VERSION "created by canmatrix"

NS_ :

BS_:

BU_: IPD

BO_ 712 IPD_BKPCANFD_100ms_FrP124: 16 IPD
 SG_ NrwroadFwdBtnDsp : 15|2@0+ (1,0) [0|3] "null" Vector__XXX
 SG_ NrwroadFwdReDst : 23|11@0+ (0.1,0) [0|204.7] "m" Vector__XXX
 SG_ NrwroadFwdDsp : 28|5@0+ (1,0) [0|31] "null" Vector__XXX
 SG_ NrwroadFwdDstL : 39|8@0+ (1,0) [0|255] "cm" Vector__XXX
 SG_ NrwroadFwdDstR : 47|8@0+ (1,0) [0|255] "cm" Vector__XXX
 SG_ NrwroadFwdCndNotSt : 55|5@0+ (1,0) [0|31] "null" Vector__XXX
 SG_ NrwroadFwdDstTostDsp : 111|4@0+ (1,0) [0|15] "null" Vector__XXX
 SG_ NrwroadFwdSwSts : 113|2@0+ (1,0) [0|3] "null" Vector__XXX
 SG_ NrwroadFwdDst360Req : 116|3@0+ (1,0) [0|7] "null" Vector__XXX
 SG_ NrwroadFwdDstBtnDsp : 119|3@0+ (1,0) [0|7] "null" Vector__XXX

BO_ 710 IPD_BKPCANFD_100ms_FrP127: 64 IPD
 SG_ SpedRegulaModSwSts : 180|3@0+ (1,0) [0|7] "null" Vector__XXX
 SG_ RADSSwSts : 373|2@0+ (1,0) [0|3] "null" Vector__XXX

BO_ 706 IPD_BKPCANFD_100ms_FrP128: 64 IPD
 SG_ PDSysKeyPsAvlbl : 113|2@0+ (1,0) [0|3] "null" Vector__XXX

BO_ 807 IPD_BKPCANFD_100ms_FrP35: 64 IPD
 SG_ TSRTrgtWarnSign : 23|7@0+ (1,0) [0|127] "null" Vector__XXX
 SG_ SpdAstSysTrgtSpd_IPD : 55|15@0+ (0.015625,0) [0.000000|511.984375] "null" Vector__XXX
 SG_ TSRTrgtBanSign : 77|6@0+ (1,0) [0|63] "null" Vector__XXX
 SG_ TSRSwReqResp : 97|2@0+ (1,0) [0|3] "null" Vector__XXX
 SG_ SLIFSts_IPD : 100|3@0+ (1,0) [0|7] "null" Vector__XXX
 SG_ TSRSts : 111|3@0+ (1,0) [0|7] "null" Vector__XXX
 SG_ PilotSysAVCamrF1FltSts : 244|3@0+ (1,0) [0|7] "null" Vector__XXX
 SG_ PilotSysADASFltSts : 247|3@0+ (1,0) [0|7] "null" Vector__XXX
 SG_ AIParkngSSPLotSwSts : 249|2@0+ (1,0) [0|3] "null" Vector__XXX
 SG_ PilotSysAVCamrRFltSts : 252|3@0+ (1,0) [0|7] "null" Vector__XXX
 SG_ PilotSysAVCamrF3FltSts : 255|3@0+ (1,0) [0|7] "null" Vector__XXX
 SG_ PilotSysAVCamrFRSFltSts : 260|3@0+ (1,0) [0|7] "null" Vector__XXX
 SG_ PilotSysAVCamrFLSFltSts : 263|3@0+ (1,0) [0|7] "null" Vector__XXX
 SG_ PilotSysAVCamrRRSFltSts : 268|3@0+ (1,0) [0|7] "null" Vector__XXX
 SG_ PilotSysAVCamrRLSFltSts : 271|3@0+ (1,0) [0|7] "null" Vector__XXX
 SG_ PilotSysHDAVMCamrRFltSts : 276|3@0+ (1,0) [0|7] "null" Vector__XXX
 SG_ PilotSysHDAVMCamrFFltSts : 279|3@0+ (1,0) [0|7] "null" Vector__XXX
 SG_ PilotSysHDAVMCamrRHFltSts : 284|3@0+ (1,0) [0|7] "null" Vector__XXX
 SG_ PilotSysHDAVMCamrLHFltSts : 287|3@0+ (1,0) [0|7] "null" Vector__XXX
 SG_ SLIFWrnngMdResp : 289|2@0+ (1,0) [0|3] "null" Vector__XXX
 SG_ PilotSysLFSDAFltSts : 292|3@0+ (1,0) [0|7] "null" Vector__XXX
 SG_ PilotSysFDRFltSts : 295|3@0+ (1,0) [0|7] "null" Vector__XXX
 SG_ TrgtSpdSrcSts_IPD : 297|2@0+ (1,0) [0|3] "null" Vector__XXX
 SG_ PilotSysLHRDAFltSts : 300|3@0+ (1,0) [0|7] "null" Vector__XXX
 SG_ PilotSysRFSDAFltSts : 303|3@0+ (1,0) [0|7] "null" Vector__XXX
 SG_ SLIFAudWrnng_IPD : 304|1@0+ (1,0) [0|1] "null" Vector__XXX
 SG_ SLIFUpdtInd_IPD : 305|1@0+ (1,0) [0|1] "null" Vector__XXX
 SG_ PilotSysFLIDARFltSts : 308|3@0+ (1,0) [0|7] "null" Vector__XXX
 SG_ PilotSysRHRDAFltSts : 311|3@0+ (1,0) [0|7] "null" Vector__XXX
 SG_ PilotSysUSSFltSts : 319|3@0+ (1,0) [0|7] "null" Vector__XXX
 SG_ HORWarningEvtSts : 338|3@0+ (1,0) [0|7] "null" Vector__XXX
 SG_ EORWarningEvtSts : 341|3@0+ (1,0) [0|7] "null" Vector__XXX
 SG_ PosALCFailed : 351|8@0+ (1,0) [0|255] "null" Vector__XXX
 SG_ SLIFSysFltSts : 355|3@0+ (1,0) [0|7] "null" Vector__XXX
 SG_ ADS_ISAMsgReq : 359|4@0+ (1,0) [0|15] "null" Vector__XXX
 SG_ SLIFUpdtIndResp_IPD : 361|2@0+ (1,0) [0|3] "null" Vector__XXX
 SG_ ADS_ISASysFltSts : 364|3@0+ (1,0) [0|7] "null" Vector__XXX
 SG_ ADS_ISASysSts : 367|3@0+ (1,0) [0|7] "null" Vector__XXX
 SG_ ParkngSpdSwResp : 375|2@0+ (1,0) [0|3] "null" Vector__XXX

BO_ 765 IPD_BKPCANFD_100ms_FrP50: 32 IPD
 SG_ FrtCamrHeatCtrl : 195|1@0+ (1,0) [0|1] "null" Vector__XXX

BO_ 844 IPD_BKPCANFD_100ms_FrP58: 32 IPD
 SG_ RAAlrWorDis : 23|10@0+ (0.1,0) [0|102.3] "m" Vector__XXX
 SG_ IACCPreSpdLimtCmd : 25|2@0+ (1,0) [0|3] "null" Vector__XXX
 SG_ IACCPreMsgReq : 29|4@0+ (1,0) [0|15] "null" Vector__XXX
 SG_ TgtParkingFavorite : 59|4@0+ (1,0) [0|15] "null" Vector__XXX
 SG_ IPDWtrClntInltFlwReq : 63|4@0+ (1,0) [0|15] "null" Vector__XXX
 SG_ IPDAVCamrHeatReq : 72|1@0+ (1,0) [0|1] "null" Vector__XXX
 SG_ IPDWtrClntInltTimeReq : 109|1@0+ (1,0) [0|1] "null" Vector__XXX
 SG_ SpdLmtOfstSetNumResp : 115|4@0+ (1,0) [0|15] "null" Vector__XXX
 SG_ TJAICAMsgReq : 123|5@0+ (1,0) [0|31] "null" Vector__XXX
 SG_ SpdLmtOfstSetPercResp : 127|3@0+ (1,0) [0|7] "null" Vector__XXX
 SG_ ACCStsSw : 129|2@0+ (1,0) [0|3] "null" Vector__XXX
 SG_ ACCSpdLimtSw : 131|2@0+ (1,0) [0|3] "null" Vector__XXX
 SG_ SpdLimitManualSts : 137|2@0+ (1,0) [0|3] "null" Vector__XXX
 SG_ NonDirectDMSSwDspCmd : 139|2@0+ (1,0) [0|3] "null" Vector__XXX
 SG_ CCSpdlVcCmdSwReqDspCmd : 141|2@0+ (1,0) [0|3] "null" Vector__XXX
 SG_ ADAudioSWSts : 143|2@0+ (1,0) [0|3] "null" Vector__XXX
 SG_ SpdLmtMdMsgReq : 147|3@0+ (1,0) [0|7] "null" Vector__XXX
 SG_ NonDirectDMSSysSts : 151|3@0+ (1,0) [0|7] "null" Vector__XXX
 SG_ ParkngEndDis : 159|8@0+ (0.1,0) [0|25.5] "null" Vector__XXX
 SG_ IACCOvTSuppresCmd : 167|3@0+ (1,0) [0|7] "null" Vector__XXX

BO_ 755 IPD_BKPCANFD_100ms_FrP61: 24 IPD
 SG_ LADSInfoDispReqToICM_HPP : 23|8@0+ (1,0) [0|255] "null" Vector__XXX
 SG_ ESSAdoWrnngDspCmd : 25|2@0+ (1,0) [0|3] "null" Vector__XXX
 SG_ HPPFnSts : 31|6@0+ (1,0) [0|63] "null" Vector__XXX
 SG_ HPPInBmtSts : 32|1@0+ (1,0) [0|1] "null" Vector__XXX
 SG_ LADSCurToEndPntDist : 39|7@0+ (0.1,0) [0|12.7] "null" Vector__XXX
 SG_ ESSDspCmd : 41|2@0+ (1,0) [0|3] "null" Vector__XXX
 SG_ NOACitySysMsg : 47|6@0+ (1,0) [0|63] "null" Vector__XXX
 SG_ FLSUSSSts : 49|2@0+ (1,0) [0|3] "null" Vector__XXX
 SG_ NOPSysMsg : 55|6@0+ (1,0) [0|63] "null" Vector__XXX
 SG_ LCRInHMI : 58|3@0+ (1,0) [0|7] "null" Vector__XXX
 SG_ NOADistDecMsg : 63|5@0+ (1,0) [0|31] "null" Vector__XXX
 SG_ NarRoVslAssSwResp : 66|3@0+ (1,0) [0|7] "null" Vector__XXX
 SG_ NrwroadBwdAssMesg : 71|5@0+ (1,0) [0|31] "null" Vector__XXX
 SG_ JAMsgReq : 75|4@0+ (1,0) [0|15] "null" Vector__XXX
 SG_ DetourMsgReq : 79|4@0+ (1,0) [0|15] "null" Vector__XXX
 SG_ ParkngOutDircnSelResult : 83|4@0+ (1,0) [0|15] "null" Vector__XXX
 SG_ NOAQukChgSwDspCmd : 87|4@0+ (1,0) [0|15] "null" Vector__XXX
 SG_ NrwroadBwdAssSwSts : 90|3@0+ (1,0) [0|7] "null" Vector__XXX
 SG_ FLUSSSts : 92|2@0+ (1,0) [0|3] "null" Vector__XXX
 SG_ PEBSts : 95|3@0+ (1,0) [0|7] "null" Vector__XXX
 SG_ FrtCarGoNotfrDspCmd : 97|2@0+ (1,0) [0|3] "null" Vector__XXX
 SG_ FRSUSSSts : 99|2@0+ (1,0) [0|3] "null" Vector__XXX
 SG_ FMRUSSSts : 101|2@0+ (1,0) [0|3] "null" Vector__XXX
 SG_ FMLUSSSts : 103|2@0+ (1,0) [0|3] "null" Vector__XXX
 SG_ NOALaneSetDspCmd : 105|2@0+ (1,0) [0|3] "null" Vector__XXX
 SG_ NOAETCSetDspCmd : 107|2@0+ (1,0) [0|3] "null" Vector__XXX
 SG_ LCRSwDspCmd : 109|2@0+ (1,0) [0|3] "null" Vector__XXX
 SG_ FRUSSSts : 111|2@0+ (1,0) [0|3] "null" Vector__XXX
 SG_ NOPCitySwDspCmd : 113|2@0+ (1,0) [0|3] "null" Vector__XXX
 SG_ NOPSwDspCmd : 116|3@0+ (1,0) [0|7] "null" Vector__XXX
 SG_ NOAReportSetDspCmd : 119|3@0+ (1,0) [0|7] "null" Vector__XXX
 SG_ RLUSSSts : 121|2@0+ (1,0) [0|3] "null" Vector__XXX
 SG_ RLSUSSSts : 123|2@0+ (1,0) [0|3] "null" Vector__XXX
 SG_ PEBWarngReq : 125|2@0+ (1,0) [0|3] "null" Vector__XXX
 SG_ NrwroadBwdAssConfrmSwDscmd : 127|2@0+ (1,0) [0|3] "null" Vector__XXX
 SG_ RRUSSSts : 129|2@0+ (1,0) [0|3] "null" Vector__XXX
 SG_ RRSUSSSts : 131|2@0+ (1,0) [0|3] "null" Vector__XXX
 SG_ RMRUSSSts : 133|2@0+ (1,0) [0|3] "null" Vector__XXX
 SG_ RMLUSSSts : 135|2@0+ (1,0) [0|3] "null" Vector__XXX
 SG_ ParkngOutFRCrsSts : 136|1@0+ (1,0) [0|1] "null" Vector__XXX
 SG_ ParkngOutFLParllSts : 137|1@0+ (1,0) [0|1] "null" Vector__XXX
 SG_ ParkngOutFLCrsSts : 138|1@0+ (1,0) [0|1] "null" Vector__XXX
 SG_ ParkngOutBkRCrsSts : 139|1@0+ (1,0) [0|1] "null" Vector__XXX
 SG_ ParkngOutBkLCrsSts : 140|1@0+ (1,0) [0|1] "null" Vector__XXX
 SG_ ParkngOutBkCrsSts : 141|1@0+ (1,0) [0|1] "null" Vector__XXX
 SG_ HPPOnRoutSts : 142|1@0+ (1,0) [0|1] "null" Vector__XXX
 SG_ HPPMapBuildSts : 143|1@0+ (1,0) [0|1] "null" Vector__XXX
 SG_ ParkngDirAvlSts : 145|3@0+ (1,0) [0|7] "null" Vector__XXX
 SG_ ParkngDirSwResp : 147|2@0+ (1,0) [0|3] "null" Vector__XXX
 SG_ ParkngSlotFindSts : 149|1@0+ (1,0) [0|1] "null" Vector__XXX
 SG_ ParkngOutFrtCrsSts : 150|1@0+ (1,0) [0|1] "null" Vector__XXX
 SG_ ParkngOutFRParllSts : 151|1@0+ (1,0) [0|1] "null" Vector__XXX
 SG_ PEBSwResp : 158|2@0+ (1,0) [0|3] "null" Vector__XXX

BO_ 774 IPD_BKPCANFD_100ms_P31: 64 IPD
 SG_ TrfcMrgdForbidDist : 15|15@0+ (0.0156,-256) [-256.0000|255.1652] "null" Vector__XXX
 SG_ TrfcMrgdInfoSignDist : 31|15@0+ (0.0156,-256) [-256.0000|255.1652] "null" Vector__XXX
 SG_ TrfcMrgdWrnngSignDist : 47|15@0+ (0.0156,-256) [-256.0000|255.1652] "null" Vector__XXX
 SG_ ParkngInPrgs : 63|7@0+ (1,0) [0|127] "%" Vector__XXX
 SG_ ParkngNCPAvlSts : 76|3@0+ (1,0) [0|7] "null" Vector__XXX
 SG_ TrfcLghtFuctionSwSts : 97|2@0+ (1,0) [0|3] "null" Vector__XXX
 SG_ APASpdMdSwSts : 99|2@0+ (1,0) [0|3] "null" Vector__XXX
 SG_ TrfcMrgdWrnngSign : 175|64@0+ (1,0) [0|18446744073709551615] "null" Vector__XXX
 SG_ TrfcMrgdForbidSign : 239|64@0+ (1,0) [0|18446744073709551615] "null" Vector__XXX
 SG_ TrfcMrgdInfoSign : 303|64@0+ (1,0) [0|18446744073709551615] "null" Vector__XXX

BO_ 208 IPD_BKPCANFD_10ms_FrP59: 16 IPD
 SG_ APAParkInOffsetType : 15|4@0+ (1,0) [0|15] "null" Vector__XXX
 SG_ APARemShifGear : 23|10@0+ (1,0) [0|1023] "null" Vector__XXX
 SG_ APASW : 29|2@0+ (1,0) [0|3] "null" Vector__XXX

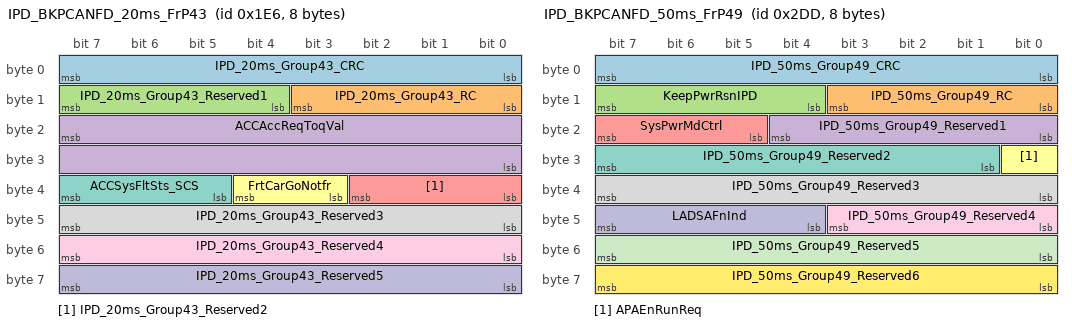
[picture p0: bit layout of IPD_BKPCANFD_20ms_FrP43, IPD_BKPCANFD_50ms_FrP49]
BO_ 486 IPD_BKPCANFD_20ms_FrP43: 8 IPD
 SG_ IPD_20ms_Group43_CRC : 7|8@0+ (1,0) [0|255] "null" Vector__XXX
 SG_ IPD_20ms_Group43_RC : 11|4@0+ (1,0) [0|15] "null" Vector__XXX
 SG_ IPD_20ms_Group43_Reserved1 : 15|4@0+ (1,0) [0|15] "null" Vector__XXX
 SG_ ACCAccReqToqVal : 23|16@0+ (1,0) [0|65535] "Nm" Vector__XXX
 SG_ IPD_20ms_Group43_Reserved2 : 34|3@0+ (1,0) [0|7] "null" Vector__XXX
 SG_ FrtCarGoNotfr : 36|2@0+ (1,0) [0|3] "null" Vector__XXX
 SG_ ACCSysFltSts_SCS : 39|3@0+ (1,0) [0|7] "null" Vector__XXX
 SG_ IPD_20ms_Group43_Reserved3 : 47|8@0+ (1,0) [0|255] "null" Vector__XXX
 SG_ IPD_20ms_Group43_Reserved4 : 55|8@0+ (1,0) [0|255] "null" Vector__XXX
 SG_ IPD_20ms_Group43_Reserved5 : 63|8@0+ (1,0) [0|255] "null" Vector__XXX

BO_ 337 IPD_BKPCANFD_20ms_FrP60: 20 IPD
 SG_ IPD_20ms_Group60_CRC : 7|8@0+ (1,0) [0|255] "null" Vector__XXX
 SG_ IPD_20ms_Group60_RC : 11|4@0+ (1,0) [0|15] "null" Vector__XXX
 SG_ AutoLaneChngRLaneSts : 15|4@0+ (1,0) [0|15] "null" Vector__XXX
 SG_ IPD_20ms_Group60_Reserved1 : 23|8@0+ (1,0) [0|255] "null" Vector__XXX
 SG_ IPD_20ms_Group60_Reserved2 : 31|8@0+ (1,0) [0|255] "null" Vector__XXX
 SG_ APASCSToqReqVal : 39|16@0+ (1,0) [0|65535] "Nm" Vector__XXX
 SG_ APAVehCrdnatPosY : 55|13@0+ (1,-4096) [-4096|4095] "cm" Vector__XXX
 SG_ APAVehCrdnatAzmth : 56|9@0+ (1,0) [0|511] "degree" Vector__XXX
 SG_ ESSDirInd : 58|2@0+ (1,0) [0|3] "null" Vector__XXX
 SG_ PilotTkovMsgReq : 75|4@0+ (1,0) [0|15] "null" Vector__XXX
 SG_ NOPSysSts_ZPD : 79|4@0+ (1,0) [0|15] "null" Vector__XXX
 SG_ PrkgDstCtrlSwResp : 81|2@0+ (1,0) [0|3] "null" Vector__XXX
 SG_ ALCSysSts : 84|3@0+ (1,0) [0|7] "null" Vector__XXX
 SG_ ALCSysFltSts : 87|3@0+ (1,0) [0|7] "null" Vector__XXX
 SG_ APAVehCrdnatPosX : 95|12@0+ (1,-2048) [-2048|2047] "cm" Vector__XXX
 SG_ AutoLaneChngLLaneSts : 99|4@0+ (1,0) [0|15] "null" Vector__XXX
 SG_ IPD_20ms_Group60_Reserved4 : 105|2@0+ (1,0) [0|3] "null" Vector__XXX
 SG_ ESSSysSts : 108|3@0+ (1,0) [0|7] "null" Vector__XXX
 SG_ ESSSysFltSts : 111|3@0+ (1,0) [0|7] "null" Vector__XXX
 SG_ IPD_20ms_Group60_Reserved6 : 112|1@0+ (1,0) [0|1] "null" Vector__XXX
 SG_ ESSDrvrTkovReq : 113|1@0+ (1,0) [0|1] "null" Vector__XXX
 SG_ IPD_20ms_Group60_Reserved5 : 116|3@0+ (1,0) [0|7] "null" Vector__XXX
 SG_ Parkngslottype : 119|3@0+ (1,0) [0|7] "null" Vector__XXX
 SG_ IPD_20ms_Group60_Reserved7 : 124|5@0+ (1,0) [0|31] "null" Vector__XXX
 SG_ NOPSysFltSts : 127|3@0+ (1,0) [0|7] "null" Vector__XXX
 SG_ IPD_20ms_Group60_Reserved8 : 135|8@0+ (1,0) [0|255] "null" Vector__XXX
 SG_ IPD_20ms_Group60_Reserved9 : 143|8@0+ (1,0) [0|255] "null" Vector__XXX
 SG_ IPD_20ms_Group60_Reserved10 : 151|8@0+ (1,0) [0|255] "null" Vector__XXX
 SG_ IPD_20ms_Group60_Reserved11 : 159|8@0+ (1,0) [0|255] "null" Vector__XXX

BO_ 720 IPD_BKPCANFD_50ms_FrP14: 16 IPD
 SG_ IPD_50ms_Group14_CRC : 7|8@0+ (1,0) [0|255] "null" Vector__XXX
 SG_ IPD_50ms_Group14_RC : 11|4@0+ (1,0) [0|15] "null" Vector__XXX
 SG_ IPD_50ms_Group14_Reserved1 : 15|4@0+ (1,0) [0|15] "null" Vector__XXX
 SG_ IPD_50ms_Group14_Reserved2 : 23|8@0+ (1,0) [0|255] "null" Vector__XXX
 SG_ IPD_50ms_Group14_Reserved3 : 31|8@0+ (1,0) [0|255] "null" Vector__XXX
 SG_ IPD_50ms_Group14_Reserved4 : 39|8@0+ (1,0) [0|255] "null" Vector__XXX
 SG_ IPD_50ms_Group14_Reserved5 : 47|8@0+ (1,0) [0|255] "null" Vector__XXX
 SG_ IPD_50ms_Group14_Reserved6 : 55|8@0+ (1,0) [0|255] "null" Vector__XXX
 SG_ LADSInfoDispReq : 63|8@0+ (1,0) [0|255] "null" Vector__XXX
 SG_ LADSInfoDispReqToICM : 71|8@0+ (1,0) [0|255] "null" Vector__XXX
 SG_ IPD_50ms_Group14_Reserved7 : 72|1@0+ (1,0) [0|1] "null" Vector__XXX
 SG_ LADSProgressBar : 79|7@0+ (1,0) [0|127] "Percent" Vector__XXX
 SG_ SDWLSRObsRng : 83|4@0+ (1,0) [0|15] "null" Vector__XXX
 SG_ SDWLSFObsRng : 87|4@0+ (1,0) [0|15] "null" Vector__XXX
 SG_ SDWRSRObsRng : 91|4@0+ (1,0) [0|15] "null" Vector__XXX
 SG_ SDWRSFObsRng : 95|4@0+ (1,0) [0|15] "null" Vector__XXX
 SG_ IPD_50ms_Group14_Reserved8 : 103|8@0+ (1,0) [0|255] "null" Vector__XXX
 SG_ IPD_50ms_Group14_Reserved9 : 111|8@0+ (1,0) [0|255] "null" Vector__XXX
 SG_ IPD_50ms_Group14_Reserved10 : 119|8@0+ (1,0) [0|255] "null" Vector__XXX
 SG_ IPD_50ms_Group14_Reserved11 : 127|8@0+ (1,0) [0|255] "null" Vector__XXX

BO_ 733 IPD_BKPCANFD_50ms_FrP49: 8 IPD
 SG_ IPD_50ms_Group49_CRC : 7|8@0+ (1,0) [0|255] "null" Vector__XXX
 SG_ IPD_50ms_Group49_RC : 11|4@0+ (1,0) [0|15] "null" Vector__XXX
 SG_ KeepPwrRsnIPD : 15|4@0+ (1,0) [0|15] "null" Vector__XXX
 SG_ IPD_50ms_Group49_Reserved1 : 20|5@0+ (1,0) [0|31] "null" Vector__XXX
 SG_ SysPwrMdCtrl : 23|3@0+ (1,0) [0|7] "null" Vector__XXX
 SG_ APAEnRunReq : 24|1@0+ (1,0) [0|1] "null" Vector__XXX
 SG_ IPD_50ms_Group49_Reserved2 : 31|7@0+ (1,0) [0|127] "null" Vector__XXX
 SG_ IPD_50ms_Group49_Reserved3 : 39|8@0+ (1,0) [0|255] "null" Vector__XXX
 SG_ IPD_50ms_Group49_Reserved4 : 43|4@0+ (1,0) [0|15] "null" Vector__XXX
 SG_ LADSAFnInd : 47|4@0+ (1,0) [0|15] "null" Vector__XXX
 SG_ IPD_50ms_Group49_Reserved5 : 55|8@0+ (1,0) [0|255] "null" Vector__XXX
 SG_ IPD_50ms_Group49_Reserved6 : 63|8@0+ (1,0) [0|255] "null" Vector__XXX

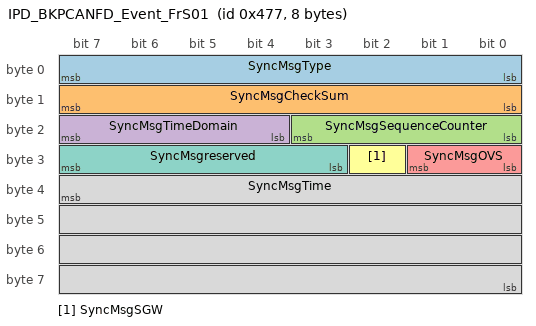
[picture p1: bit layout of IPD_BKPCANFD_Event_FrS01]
BO_ 1143 IPD_BKPCANFD_Event_FrS01: 8 IPD
 SG_ SyncMsgType : 7|8@0+ (1,0) [0|255] "null" Vector__XXX
 SG_ SyncMsgCheckSum : 15|8@0+ (1,0) [0|255] "null" Vector__XXX
 SG_ SyncMsgSequenceCounter : 19|4@0+ (1,0) [0|15] "null" Vector__XXX
 SG_ SyncMsgTimeDomain : 23|4@0+ (1,0) [0|15] "null" Vector__XXX
 SG_ SyncMsgOVS : 25|2@0+ (1,0) [0|3] "s" Vector__XXX
 SG_ SyncMsgSGW : 26|1@0+ (1,0) [0|1] "null" Vector__XXX
 SG_ SyncMsgreserved : 31|5@0+ (1,0) [0|31] "null" Vector__XXX
 SG_ SyncMsgTime : 39|32@0+ (1,0) [0|4294967295] "null" Vector__XXX

BO_ 1399 IPD_BKPCANFD_Event_FrS13: 20 IPD
 SG_ IPDIdentityResp : 7|64@0+ (1,0) [0|18446744073709551615] "null" Vector__XXX

BO_ 1526 IPD_BKPCANFD_Event_FrS35: 8 IPD
 SG_ IPDComKeyEnbResp : 3|1@0+ (1,0) [0|1] "null" Vector__XXX
 SG_ AIParkngRespICB : 55|8@0+ (1,0) [0|255] "null" Vector__XXX

BA_DEF_ BO_ "FrameTriggeringName" STRING;
BA_DEF_ BO_ "GenMsgCycleTime" INT 0 65535;
BA_DEF_ BO_ "GenMsgDelayTime" INT 0 65535;
BA_DEF_ BO_ "GenMsgSendType" ENUM  "cyclicX","spontanX","cyclicIfActiveX","spontanWithDelay","cyclicAndSpontanX","cyclicAndSpontanWithDelay","spontanWithRepitition","cyclicIfActiveAndSpontanWD","cyclicIfActiveFast","cyclicWithRepeatOnDemand","none";
BA_DEF_ BO_ "GenMsgStartValue" STRING;
BA_DEF_ BO_ "PduName" STRING;
BA_DEF_ BO_ "SystemMessageLongSymbol" STRING;
BA_DEF_ BO_ "VFrameFormat" ENUM  "StandardCAN","ExtendedCAN","reserved","reserved","reserved","reserved","reserved","reserved","reserved","reserved","reserved","reserved","reserved","reserved","StandardCAN_FD","ExtendedCAN_FD";
BA_DEF_ SG_ "CompuMethodName" STRING;
BA_DEF_ SG_ "GenSigStartValue" FLOAT 0 100000000000;
BA_DEF_ SG_ "ISignalName" STRING;
BA_DEF_ SG_ "LongName" STRING;
BA_DEF_ SG_ "SysSignalName" STRING;
BA_DEF_ SG_ "SystemSignalLongSymbol" STRING;
BA_ "FrameTriggeringName" BO_ 712 "IPD_BKPCANFD_100ms_FrP124";
BA_ "GenMsgCycleTime" BO_ 712 100;
BA_ "GenMsgSendType" BO_ 712 0;
BA_ "GenMsgStartValue" BO_ 712 "00c0ffe0ffff00000000000000000100";
BA_ "PduName" BO_ 712 "IPD_100ms_PDU124";
BA_ "VFrameFormat" BO_ 712 14;
BA_ "FrameTriggeringName" BO_ 710 "IPD_BKPCANFD_100ms_FrP127";
BA_ "GenMsgCycleTime" BO_ 710 100;
BA_ "GenMsgSendType" BO_ 710 0;
BA_ "GenMsgStartValue" BO_ 710 "00000000000000000000000000000000000000000000000000000000000000000000000000000000000000000000100000000000000000000000000000000000";
BA_ "PduName" BO_ 710 "IPD_100ms_PDU127";
BA_ "VFrameFormat" BO_ 710 14;
BA_ "FrameTriggeringName" BO_ 706 "IPD_BKPCANFD_100ms_FrP128";
BA_ "GenMsgCycleTime" BO_ 706 100;
BA_ "GenMsgSendType" BO_ 706 0;
BA_ "GenMsgStartValue" BO_ 706 "00000000000000000000000000000000000000000000000000000000000000000000000000000000000000000000000000000000000000000000000000000000";
BA_ "PduName" BO_ 706 "IPD_100ms_PDU128";
BA_ "VFrameFormat" BO_ 706 14;
BA_ "FrameTriggeringName" BO_ 807 "IPD_BKPCANFD_100ms_FrP35";
BA_ "GenMsgCycleTime" BO_ 807 100;
BA_ "GenMsgSendType" BO_ 807 0;
BA_ "GenMsgStartValue" BO_ 807 "00000000000000000000000000000000000000000000000000000000000000000000000000000000000000000000000000000000000000000000000000000000";
BA_ "PduName" BO_ 807 "IPD_100ms_PDU35";
BA_ "VFrameFormat" BO_ 807 14;
BA_ "FrameTriggeringName" BO_ 765 "IPD_BKPCANFD_100ms_FrP50";
BA_ "GenMsgCycleTime" BO_ 765 100;
BA_ "GenMsgSendType" BO_ 765 0;
BA_ "GenMsgStartValue" BO_ 765 "0000000000000000000000000000000000000000000000000000000000000000";
BA_ "PduName" BO_ 765 "IPD_100ms_PDU50";
BA_ "VFrameFormat" BO_ 765 14;
BA_ "FrameTriggeringName" BO_ 844 "IPD_BKPCANFD_100ms_FrP58";
BA_ "GenMsgCycleTime" BO_ 844 100;
BA_ "GenMsgSendType" BO_ 844 0;
BA_ "GenMsgStartValue" BO_ 844 "0000000000000000000000000000000000000000000000000000000000000000";
BA_ "PduName" BO_ 844 "IPD_100ms_PDU58";
BA_ "VFrameFormat" BO_ 844 14;
BA_ "FrameTriggeringName" BO_ 755 "IPD_BKPCANFD_100ms_FrP61";
BA_ "GenMsgCycleTime" BO_ 755 100;
BA_ "GenMsgSendType" BO_ 755 0;
BA_ "GenMsgStartValue" BO_ 755 "000000020002040000000000000000000000000000000000";
BA_ "PduName" BO_ 755 "IPD_100ms_PDU61";
BA_ "VFrameFormat" BO_ 755 14;
BA_ "FrameTriggeringName" BO_ 774 "IPD_BKPCANFD_100ms_P31";
BA_ "GenMsgCycleTime" BO_ 774 100;
BA_ "GenMsgSendType" BO_ 774 0;
BA_ "GenMsgStartValue" BO_ 774 "00000000000000000000000004000000000000000000000000000000000000000000000000000000000000000000000000000000000000000000000000000000";
BA_ "PduName" BO_ 774 "ICBAD_100ms_PDU31";
BA_ "VFrameFormat" BO_ 774 14;
BA_ "FrameTriggeringName" BO_ 208 "IPD_BKPCANFD_10ms_FrP59";
BA_ "GenMsgCycleTime" BO_ 208 10;
BA_ "GenMsgSendType" BO_ 208 0;
BA_ "GenMsgStartValue" BO_ 208 "00000000000000000000000000000000";
BA_ "PduName" BO_ 208 "IPD_10ms_PDU59";
BA_ "VFrameFormat" BO_ 208 14;
BA_ "FrameTriggeringName" BO_ 486 "IPD_BKPCANFD_20ms_FrP43";
BA_ "GenMsgCycleTime" BO_ 486 20;
BA_ "GenMsgSendType" BO_ 486 0;
BA_ "GenMsgStartValue" BO_ 486 "00f0000007ffffff";
BA_ "PduName" BO_ 486 "IPD_20ms_PDU43";
BA_ "VFrameFormat" BO_ 486 14;
BA_ "FrameTriggeringName" BO_ 337 "IPD_BKPCANFD_20ms_FrP60";
BA_ "GenMsgCycleTime" BO_ 337 20;
BA_ "GenMsgSendType" BO_ 337 0;
BA_ "GenMsgStartValue" BO_ 337 "0000ffff000000000000010000071d1fffffffff";
BA_ "PduName" BO_ 337 "IPD_20ms_PDU60";
BA_ "VFrameFormat" BO_ 337 14;
BA_ "FrameTriggeringName" BO_ 720 "IPD_BKPCANFD_50ms_FrP14";
BA_ "GenMsgCycleTime" BO_ 720 50;
BA_ "GenMsgSendType" BO_ 720 0;
BA_ "GenMsgStartValue" BO_ 720 "00f0ffffffffff0000010000ffffffff";
BA_ "PduName" BO_ 720 "IPD_50ms_PDU14";
BA_ "VFrameFormat" BO_ 720 14;
BA_ "FrameTriggeringName" BO_ 733 "IPD_BKPCANFD_50ms_FrP49";
BA_ "GenMsgCycleTime" BO_ 733 50;
BA_ "GenMsgSendType" BO_ 733 0;
BA_ "GenMsgStartValue" BO_ 733 "00001ffeff0fffff";
BA_ "PduName" BO_ 733 "IPD_50ms_PDU49";
BA_ "VFrameFormat" BO_ 733 14;
BA_ "FrameTriggeringName" BO_ 1143 "IPD_BKPCANFD_Event_FrS01";
BA_ "GenMsgSendType" BO_ 1143 1;
BA_ "GenMsgStartValue" BO_ 1143 "0000100000000000";
BA_ "PduName" BO_ 1143 "IPD_Sporadic_PDU01";
BA_ "VFrameFormat" BO_ 1143 14;
BA_ "FrameTriggeringName" BO_ 1399 "IPD_BKPCANFD_Event_FrS13";
BA_ "GenMsgSendType" BO_ 1399 1;
BA_ "GenMsgStartValue" BO_ 1399 "0000000000000000000000000000000000000000";
BA_ "PduName" BO_ 1399 "IPD_Sporadic_PDU13";
BA_ "VFrameFormat" BO_ 1399 14;
BA_ "FrameTriggeringName" BO_ 1526 "IPD_BKPCANFD_Event_FrS35";
BA_ "GenMsgSendType" BO_ 1526 1;
BA_ "GenMsgStartValue" BO_ 1526 "0000000000000000";
BA_ "PduName" BO_ 1526 "IPD_Sporadic_PDU35";
BA_ "VFrameFormat" BO_ 1526 14;
BA_ "CompuMethodName" SG_ 712 NrwroadFwdBtnDsp "NrwroadFwdBtnDsp";
BA_ "GenSigStartValue" SG_ 712 NrwroadFwdBtnDsp 3;
BA_ "ISignalName" SG_ 712 NrwroadFwdBtnDsp "INrwroadFwdBtnDsp";
BA_ "LongName" SG_ 712 NrwroadFwdBtnDsp "Narrow road forward button display";
BA_ "SysSignalName" SG_ 712 NrwroadFwdBtnDsp "NrwroadFwdBtnDsp";
BA_ "CompuMethodName" SG_ 712 NrwroadFwdReDst "NrwroadFwdReDst";
BA_ "GenSigStartValue" SG_ 712 NrwroadFwdReDst 2047;
BA_ "ISignalName" SG_ 712 NrwroadFwdReDst "INrwroadFwdReDst";
BA_ "LongName" SG_ 712 NrwroadFwdReDst "Narrow road forward remaining distance";
BA_ "SysSignalName" SG_ 712 NrwroadFwdReDst "NrwroadFwdReDst";
BA_ "CompuMethodName" SG_ 712 NrwroadFwdDsp "NrwroadFwdDsp";
BA_ "ISignalName" SG_ 712 NrwroadFwdDsp "INrwroadFwdDsp";
BA_ "LongName" SG_ 712 NrwroadFwdDsp "Narrow road forward display";
BA_ "SysSignalName" SG_ 712 NrwroadFwdDsp "NrwroadFwdDsp";
BA_ "CompuMethodName" SG_ 712 NrwroadFwdDstL "NrwroadFwdDstL";
BA_ "GenSigStartValue" SG_ 712 NrwroadFwdDstL 255;
BA_ "ISignalName" SG_ 712 NrwroadFwdDstL "INrwroadFwdDstL";
BA_ "LongName" SG_ 712 NrwroadFwdDstL "Narrow road forward distance left";
BA_ "SysSignalName" SG_ 712 NrwroadFwdDstL "NrwroadFwdDstL";
BA_ "CompuMethodName" SG_ 712 NrwroadFwdDstR "NrwroadFwdDstR";
BA_ "GenSigStartValue" SG_ 712 NrwroadFwdDstR 255;
BA_ "ISignalName" SG_ 712 NrwroadFwdDstR "INrwroadFwdDstR";
BA_ "LongName" SG_ 712 NrwroadFwdDstR "Narrow road forward distance right";
BA_ "SysSignalName" SG_ 712 NrwroadFwdDstR "NrwroadFwdDstR";
BA_ "CompuMethodName" SG_ 712 NrwroadFwdCndNotSt "NrwroadFwdCndNotSt";
BA_ "ISignalName" SG_ 712 NrwroadFwdCndNotSt "INrwroadFwdCndNotSt";
BA_ "LongName" SG_ 712 NrwroadFwdCndNotSt "Narrow road forward not satisfied";
BA_ "SysSignalName" SG_ 712 NrwroadFwdCndNotSt "NrwroadFwdCndNotSt";
BA_ "CompuMethodName" SG_ 712 NrwroadFwdDstTostDsp "NrwroadFwdDstTostDsp";
BA_ "ISignalName" SG_ 712 NrwroadFwdDstTostDsp "INrwroadFwdDstTostDsp";
BA_ "LongName" SG_ 712 NrwroadFwdDstTostDsp "Narrow road forward distance Toast display";
BA_ "SysSignalName" SG_ 712 NrwroadFwdDstTostDsp "NrwroadFwdDstTostDsp";
BA_ "CompuMethodName" SG_ 712 NrwroadFwdSwSts "NrwroadFwdSwSts";
BA_ "GenSigStartValue" SG_ 712 NrwroadFwdSwSts 1;
BA_ "ISignalName" SG_ 712 NrwroadFwdSwSts "INrwroadFwdSwSts";
BA_ "LongName" SG_ 712 NrwroadFwdSwSts "Narrow road forward Switch Status";
BA_ "SysSignalName" SG_ 712 NrwroadFwdSwSts "NrwroadFwdSwSts";
BA_ "CompuMethodName" SG_ 712 NrwroadFwdDst360Req "NrwroadFwdDst360Req";
BA_ "ISignalName" SG_ 712 NrwroadFwdDst360Req "INrwroadFwdDst360Req";
BA_ "LongName" SG_ 712 NrwroadFwdDst360Req "Narrow road forward distance 360 Requst";
BA_ "SysSignalName" SG_ 712 NrwroadFwdDst360Req "NrwroadFwdDst360Req";
BA_ "CompuMethodName" SG_ 712 NrwroadFwdDstBtnDsp "NrwroadFwdDstBtnDsp";
BA_ "ISignalName" SG_ 712 NrwroadFwdDstBtnDsp "INrwroadFwdDstBtnDsp";
BA_ "LongName" SG_ 712 NrwroadFwdDstBtnDsp "Narrow road forward distance button display";
BA_ "SysSignalName" SG_ 712 NrwroadFwdDstBtnDsp "NrwroadFwdDstBtnDsp";
BA_ "CompuMethodName" SG_ 710 SpedRegulaModSwSts "SpedRegulaModSwSts";
BA_ "ISignalName" SG_ 710 SpedRegulaModSwSts "ISpedRegulaModSwSts";
BA_ "LongName" SG_ 710 SpedRegulaModSwSts "Speed Regulation Mode Switch status";
BA_ "SysSignalName" SG_ 710 SpedRegulaModSwSts "SpedRegulaModSwSts";
BA_ "CompuMethodName" SG_ 710 RADSSwSts "RADSSwSts";
BA_ "GenSigStartValue" SG_ 710 RADSSwSts 1;
BA_ "ISignalName" SG_ 710 RADSSwSts "IRADSSwSts";
BA_ "LongName" SG_ 710 RADSSwSts "Remenber Autonomous Driving System Switch Status";
BA_ "SysSignalName" SG_ 710 RADSSwSts "RADSSwSts";
BA_ "CompuMethodName" SG_ 706 PDSysKeyPsAvlbl "PDSysKeyPsAvlbl";
BA_ "ISignalName" SG_ 706 PDSysKeyPsAvlbl "IPDSysKeyPsAvlbl";
BA_ "LongName" SG_ 706 PDSysKeyPsAvlbl "Key valid";
BA_ "SysSignalName" SG_ 706 PDSysKeyPsAvlbl "PDSysKeyPsAvlbl";
BA_ "CompuMethodName" SG_ 807 TSRTrgtWarnSign "TSRTrgtWarnSign";
BA_ "ISignalName" SG_ 807 TSRTrgtWarnSign "ITSRTrgtWarnSign";
BA_ "LongName" SG_ 807 TSRTrgtWarnSign "Traffic Sign Recognization Target Warning Sign";
BA_ "SysSignalName" SG_ 807 TSRTrgtWarnSign "TSRTrgtWarnSign";
BA_ "CompuMethodName" SG_ 807 SpdAstSysTrgtSpd_IPD "SpdAstSysTrgtSpd_IPD";
BA_ "ISignalName" SG_ 807 SpdAstSysTrgtSpd_IPD "ISpdAstSysTrgtSpd_IPD";
BA_ "LongName" SG_ 807 SpdAstSysTrgtSpd_IPD "Speed_Assist_System_Target_Speed";
BA_ "SysSignalName" SG_ 807 SpdAstSysTrgtSpd_IPD "SpdAstSysTrgtSpd_IPD";
BA_ "CompuMethodName" SG_ 807 TSRTrgtBanSign "TSRTrgtBanSign";
BA_ "ISignalName" SG_ 807 TSRTrgtBanSign "ITSRTrgtBanSign";
BA_ "LongName" SG_ 807 TSRTrgtBanSign "Traffic Sign Recognization Target Ban Sign";
BA_ "SysSignalName" SG_ 807 TSRTrgtBanSign "TSRTrgtBanSign";
BA_ "CompuMethodName" SG_ 807 TSRSwReqResp "TSRSwReqResp";
BA_ "ISignalName" SG_ 807 TSRSwReqResp "ITSRSwReqResp";
BA_ "LongName" SG_ 807 TSRSwReqResp "TSR_Switch_Request_Response";
BA_ "SysSignalName" SG_ 807 TSRSwReqResp "TSRSwReqResp";
BA_ "CompuMethodName" SG_ 807 SLIFSts_IPD "SLIFSts_IPD";
BA_ "ISignalName" SG_ 807 SLIFSts_IPD "ISLIFSts_IPD";
BA_ "LongName" SG_ 807 SLIFSts_IPD "Speed Limit Information Function Status";
BA_ "SysSignalName" SG_ 807 SLIFSts_IPD "SLIFSts_IPD";
BA_ "CompuMethodName" SG_ 807 TSRSts "TSRSts";
BA_ "ISignalName" SG_ 807 TSRSts "ITSRSts";
BA_ "LongName" SG_ 807 TSRSts "Traffic Sign Recognization Function Status";
BA_ "SysSignalName" SG_ 807 TSRSts "TSRSts";
BA_ "CompuMethodName" SG_ 807 PilotSysAVCamrF1FltSts "PilotSysAVCamrF1FltSts";
BA_ "ISignalName" SG_ 807 PilotSysAVCamrF1FltSts "IPilotSysAVCamrF1FltSts";
BA_ "LongName" SG_ 807 PilotSysAVCamrF1FltSts "Pilot System AVCamr_F1 Fault Status";
BA_ "SysSignalName" SG_ 807 PilotSysAVCamrF1FltSts "PilotSysAVCamrF1FltSts";
BA_ "CompuMethodName" SG_ 807 PilotSysADASFltSts "PilotSysADASFltSts";
BA_ "ISignalName" SG_ 807 PilotSysADASFltSts "IPilotSysADASFltSts";
BA_ "LongName" SG_ 807 PilotSysADASFltSts "Pilot System ADAS Fault Status";
BA_ "SysSignalName" SG_ 807 PilotSysADASFltSts "PilotSysADASFltSts";
BA_ "CompuMethodName" SG_ 807 AIParkngSSPLotSwSts "AIParkngSSPLotSwSts";
BA_ "ISignalName" SG_ 807 AIParkngSSPLotSwSts "IAIParkngSSPLotSwSts";
BA_ "LongName" SG_ 807 AIParkngSSPLotSwSts "Ai Parking Silent Search Parking Slot Switch Status";
BA_ "SysSignalName" SG_ 807 AIParkngSSPLotSwSts "AIParkngSSPLotSwSts";
BA_ "CompuMethodName" SG_ 807 PilotSysAVCamrRFltSts "PilotSysAVCamrRFltSts";
BA_ "ISignalName" SG_ 807 PilotSysAVCamrRFltSts "IPilotSysAVCamrRFltSts";
BA_ "LongName" SG_ 807 PilotSysAVCamrRFltSts "Pilot System AVCamr_R Fault Status";
BA_ "SysSignalName" SG_ 807 PilotSysAVCamrRFltSts "PilotSysAVCamrRFltSts";
BA_ "CompuMethodName" SG_ 807 PilotSysAVCamrF3FltSts "PilotSysAVCamrF3FltSts";
BA_ "ISignalName" SG_ 807 PilotSysAVCamrF3FltSts "IPilotSysAVCamrF3FltSts";
BA_ "LongName" SG_ 807 PilotSysAVCamrF3FltSts "Pilot System AVCamr_F3 Fault Status";
BA_ "SysSignalName" SG_ 807 PilotSysAVCamrF3FltSts "PilotSysAVCamrF3FltSts";
BA_ "CompuMethodName" SG_ 807 PilotSysAVCamrFRSFltSts "PilotSysAVCamrFRSFltSts";
BA_ "ISignalName" SG_ 807 PilotSysAVCamrFRSFltSts "IPilotSysAVCamrFRSFltSts";
BA_ "LongName" SG_ 807 PilotSysAVCamrFRSFltSts "Pilot System AVCamr_FRS Fault Status";
BA_ "SysSignalName" SG_ 807 PilotSysAVCamrFRSFltSts "PilotSysAVCamrFRSFltSts";
BA_ "CompuMethodName" SG_ 807 PilotSysAVCamrFLSFltSts "PilotSysAVCamrFLSFltSts";
BA_ "ISignalName" SG_ 807 PilotSysAVCamrFLSFltSts "IPilotSysAVCamrFLSFltSts";
BA_ "LongName" SG_ 807 PilotSysAVCamrFLSFltSts "Pilot System AVCamr_FLS Fault Status";
BA_ "SysSignalName" SG_ 807 PilotSysAVCamrFLSFltSts "PilotSysAVCamrFLSFltSts";
BA_ "CompuMethodName" SG_ 807 PilotSysAVCamrRRSFltSts "PilotSysAVCamrRRSFltSts";
BA_ "ISignalName" SG_ 807 PilotSysAVCamrRRSFltSts "IPilotSysAVCamrRRSFltSts";
BA_ "LongName" SG_ 807 PilotSysAVCamrRRSFltSts "Pilot System AVCamr_RRS Fault Status";
BA_ "SysSignalName" SG_ 807 PilotSysAVCamrRRSFltSts "PilotSysAVCamrRRSFltSts";
BA_ "CompuMethodName" SG_ 807 PilotSysAVCamrRLSFltSts "PilotSysAVCamrRLSFltSts";
BA_ "ISignalName" SG_ 807 PilotSysAVCamrRLSFltSts "IPilotSysAVCamrRLSFltSts";
BA_ "LongName" SG_ 807 PilotSysAVCamrRLSFltSts "Pilot System AVCamr_RLS Fault Status";
BA_ "SysSignalName" SG_ 807 PilotSysAVCamrRLSFltSts "PilotSysAVCamrRLSFltSts";
BA_ "CompuMethodName" SG_ 807 PilotSysHDAVMCamrRFltSts "PilotSysHDAVMCamrRFltSts";
BA_ "ISignalName" SG_ 807 PilotSysHDAVMCamrRFltSts "IPilotSysHDAVMCamrRFltSts";
BA_ "LongName" SG_ 807 PilotSysHDAVMCamrRFltSts "Pilot System HDAVMCamr_R Fault Status";
BA_ "SysSignalName" SG_ 807 PilotSysHDAVMCamrRFltSts "PilotSysHDAVMCamrRFltSts";
BA_ "CompuMethodName" SG_ 807 PilotSysHDAVMCamrFFltSts "PilotSysHDAVMCamrFFltSts";
BA_ "ISignalName" SG_ 807 PilotSysHDAVMCamrFFltSts "IPilotSysHDAVMCamrFFltSts";
BA_ "LongName" SG_ 807 PilotSysHDAVMCamrFFltSts "Pilot System HDAVMCamr_F Fault Status";
BA_ "SysSignalName" SG_ 807 PilotSysHDAVMCamrFFltSts "PilotSysHDAVMCamrFFltSts";
BA_ "CompuMethodName" SG_ 807 PilotSysHDAVMCamrRHFltSts "PilotSysHDAVMCamrRHFltSts";
BA_ "ISignalName" SG_ 807 PilotSysHDAVMCamrRHFltSts "IPilotSysHDAVMCamrRHFltSts";
BA_ "LongName" SG_ 807 PilotSysHDAVMCamrRHFltSts "Pilot System HDAVMCamr_RH Fault Status";
BA_ "SysSignalName" SG_ 807 PilotSysHDAVMCamrRHFltSts "PilotSysHDAVMCamrRHFltSts";
BA_ "CompuMethodName" SG_ 807 PilotSysHDAVMCamrLHFltSts "PilotSysHDAVMCamrLHFltSts";
BA_ "ISignalName" SG_ 807 PilotSysHDAVMCamrLHFltSts "IPilotSysHDAVMCamrLHFltSts";
BA_ "LongName" SG_ 807 PilotSysHDAVMCamrLHFltSts "Pilot System HDAVMCamr_LH Fault Status";
BA_ "SysSignalName" SG_ 807 PilotSysHDAVMCamrLHFltSts "PilotSysHDAVMCamrLHFltSts";
BA_ "CompuMethodName" SG_ 807 SLIFWrnngMdResp "SLIFWrnngMdResp";
BA_ "ISignalName" SG_ 807 SLIFWrnngMdResp "ISLIFWrnngMdResp";
BA_ "LongName" SG_ 807 SLIFWrnngMdResp "Speed Limit Information Function Warning Mode Response";
BA_ "SysSignalName" SG_ 807 SLIFWrnngMdResp "SLIFWrnngMdResp";
BA_ "CompuMethodName" SG_ 807 PilotSysLFSDAFltSts "PilotSysLFSDAFltSts";
BA_ "ISignalName" SG_ 807 PilotSysLFSDAFltSts "IPilotSysLFSDAFltSts";
BA_ "LongName" SG_ 807 PilotSysLFSDAFltSts "Pilot System LFSDA Fault Status";
BA_ "SysSignalName" SG_ 807 PilotSysLFSDAFltSts "PilotSysLFSDAFltSts";
BA_ "CompuMethodName" SG_ 807 PilotSysFDRFltSts "PilotSysFDRFltSts";
BA_ "ISignalName" SG_ 807 PilotSysFDRFltSts "IPilotSysFDRFltSts";
BA_ "LongName" SG_ 807 PilotSysFDRFltSts "Pilot System FDR Fault Status";
BA_ "SysSignalName" SG_ 807 PilotSysFDRFltSts "PilotSysFDRFltSts";
BA_ "CompuMethodName" SG_ 807 TrgtSpdSrcSts_IPD "TrgtSpdSrcSts_IPD";
BA_ "ISignalName" SG_ 807 TrgtSpdSrcSts_IPD "ITrgtSpdSrcSts_IPD";
BA_ "LongName" SG_ 807 TrgtSpdSrcSts_IPD "Target Speed Source Status";
BA_ "SysSignalName" SG_ 807 TrgtSpdSrcSts_IPD "TrgtSpdSrcSts_IPD";
BA_ "CompuMethodName" SG_ 807 PilotSysLHRDAFltSts "PilotSysLHRDAFltSts";
BA_ "ISignalName" SG_ 807 PilotSysLHRDAFltSts "IPilotSysLHRDAFltSts";
BA_ "LongName" SG_ 807 PilotSysLHRDAFltSts "Pilot System LHRDA Fault Status";
BA_ "SysSignalName" SG_ 807 PilotSysLHRDAFltSts "PilotSysLHRDAFltSts";
BA_ "CompuMethodName" SG_ 807 PilotSysRFSDAFltSts "PilotSysRFSDAFltSts";
BA_ "ISignalName" SG_ 807 PilotSysRFSDAFltSts "IPilotSysRFSDAFltSts";
BA_ "LongName" SG_ 807 PilotSysRFSDAFltSts "Pilot System RFSDA Fault Status";
BA_ "SysSignalName" SG_ 807 PilotSysRFSDAFltSts "PilotSysRFSDAFltSts";
BA_ "CompuMethodName" SG_ 807 SLIFAudWrnng_IPD "SLIFAudWrnng_IPD";
BA_ "ISignalName" SG_ 807 SLIFAudWrnng_IPD "ISLIFAudWrnng_IPD";
BA_ "LongName" SG_ 807 SLIFAudWrnng_IPD "Speed Limit Information Function Audible Warning";
BA_ "SysSignalName" SG_ 807 SLIFAudWrnng_IPD "SLIFAudWrnng_IPD";
BA_ "CompuMethodName" SG_ 807 SLIFUpdtInd_IPD "SLIFUpdtInd_IPD";
BA_ "ISignalName" SG_ 807 SLIFUpdtInd_IPD "ISLIFUpdtInd_IPD";
BA_ "LongName" SG_ 807 SLIFUpdtInd_IPD "Speed Limit Information Function Update Indication";
BA_ "SysSignalName" SG_ 807 SLIFUpdtInd_IPD "SLIFUpdtInd_IPD";
BA_ "CompuMethodName" SG_ 807 PilotSysFLIDARFltSts "PilotSysFLIDARFltSts";
BA_ "ISignalName" SG_ 807 PilotSysFLIDARFltSts "IPilotSysFLIDARFltSts";
BA_ "LongName" SG_ 807 PilotSysFLIDARFltSts "Pilot System FLIDAR Fault Status";
BA_ "SysSignalName" SG_ 807 PilotSysFLIDARFltSts "PilotSysFLIDARFltSts";
BA_ "CompuMethodName" SG_ 807 PilotSysRHRDAFltSts "PilotSysRHRDAFltSts";
BA_ "ISignalName" SG_ 807 PilotSysRHRDAFltSts "IPilotSysRHRDAFltSts";
BA_ "LongName" SG_ 807 PilotSysRHRDAFltSts "Pilot System RHRDA Fault Status";
BA_ "SysSignalName" SG_ 807 PilotSysRHRDAFltSts "PilotSysRHRDAFltSts";
BA_ "CompuMethodName" SG_ 807 PilotSysUSSFltSts "PilotSysUSSFltSts";
BA_ "ISignalName" SG_ 807 PilotSysUSSFltSts "IPilotSysUSSFltSts";
BA_ "LongName" SG_ 807 PilotSysUSSFltSts "Pilot System USS Fault Status";
BA_ "SysSignalName" SG_ 807 PilotSysUSSFltSts "PilotSysUSSFltSts";
BA_ "CompuMethodName" SG_ 807 HORWarningEvtSts "HORWarningEvtSts";
BA_ "ISignalName" SG_ 807 HORWarningEvtSts "IHORWarningEvtSts";
BA_ "LongName" SG_ 807 HORWarningEvtSts "HOR Warning Event Status";
BA_ "SysSignalName" SG_ 807 HORWarningEvtSts "HORWarningEvtSts";
BA_ "CompuMethodName" SG_ 807 EORWarningEvtSts "EORWarningEvtSts";
BA_ "ISignalName" SG_ 807 EORWarningEvtSts "IEORWarningEvtSts";
BA_ "LongName" SG_ 807 EORWarningEvtSts "EOR Warning Event Status";
BA_ "SysSignalName" SG_ 807 EORWarningEvtSts "EORWarningEvtSts";
BA_ "CompuMethodName" SG_ 807 PosALCFailed "PosALCFailed";
BA_ "ISignalName" SG_ 807 PosALCFailed "IPosALCFailed";
BA_ "LongName" SG_ 807 PosALCFailed "Positive ALC Failed";
BA_ "SysSignalName" SG_ 807 PosALCFailed "PosALCFailed";
BA_ "CompuMethodName" SG_ 807 SLIFSysFltSts "SLIFSysFltSts";
BA_ "ISignalName" SG_ 807 SLIFSysFltSts "ISLIFSysFltSts";
BA_ "LongName" SG_ 807 SLIFSysFltSts "Speed_Limit_Information_Function_System_Fault_Status";
BA_ "SysSignalName" SG_ 807 SLIFSysFltSts "SLIFSysFltSts";
BA_ "CompuMethodName" SG_ 807 ADS_ISAMsgReq "ADS_ISAMsgReq";
BA_ "ISignalName" SG_ 807 ADS_ISAMsgReq "IADS_ISAMsgReq";
BA_ "LongName" SG_ 807 ADS_ISAMsgReq "ADAS_Intelligence_Speed_Assist _System_Message_Request";
BA_ "SysSignalName" SG_ 807 ADS_ISAMsgReq "ADS_ISAMsgReq";
BA_ "CompuMethodName" SG_ 807 SLIFUpdtIndResp_IPD "SLIFUpdtIndResp_IPD";
BA_ "ISignalName" SG_ 807 SLIFUpdtIndResp_IPD "ISLIFUpdtIndResp_IPD";
BA_ "LongName" SG_ 807 SLIFUpdtIndResp_IPD "Speed Limit Information Function Update Indication Response";
BA_ "SysSignalName" SG_ 807 SLIFUpdtIndResp_IPD "SLIFUpdtIndResp_IPD";
BA_ "CompuMethodName" SG_ 807 ADS_ISASysFltSts "ADS_ISASysFltSts";
BA_ "ISignalName" SG_ 807 ADS_ISASysFltSts "IADS_ISASysFltSts";
BA_ "LongName" SG_ 807 ADS_ISASysFltSts "ADAS_Intelligence_Speed_Assist _System_Fault_Status";
BA_ "SysSignalName" SG_ 807 ADS_ISASysFltSts "ADS_ISASysFltSts";
BA_ "CompuMethodName" SG_ 807 ADS_ISASysSts "ADS_ISASysSts";
BA_ "ISignalName" SG_ 807 ADS_ISASysSts "IADS_ISASysSts";
BA_ "LongName" SG_ 807 ADS_ISASysSts "ADAS_Intelligence_Speed_Assist _System_Status";
BA_ "SysSignalName" SG_ 807 ADS_ISASysSts "ADS_ISASysSts";
BA_ "CompuMethodName" SG_ 807 ParkngSpdSwResp "ParkngSpdSwResp";
BA_ "ISignalName" SG_ 807 ParkngSpdSwResp "IParkngSpdSwResp";
BA_ "LongName" SG_ 807 ParkngSpdSwResp "Parking_Speed_Switch_Response";
BA_ "SysSignalName" SG_ 807 ParkngSpdSwResp "ParkngSpdSwResp";
BA_ "CompuMethodName" SG_ 765 FrtCamrHeatCtrl "FrtCamrHeatCtrl";
BA_ "ISignalName" SG_ 765 FrtCamrHeatCtrl "IFrtCamrHeatCtrl";
BA_ "LongName" SG_ 765 FrtCamrHeatCtrl "Front Camera Heat Control";
BA_ "SysSignalName" SG_ 765 FrtCamrHeatCtrl "FrtCamrHeatCtrl";
BA_ "CompuMethodName" SG_ 844 RAAlrWorDis "RAAlrWorDis";
BA_ "ISignalName" SG_ 844 RAAlrWorDis "IRAAlrWorDis";
BA_ "LongName" SG_ 844 RAAlrWorDis "Reverse Assist Already Working Distance";
BA_ "SysSignalName" SG_ 844 RAAlrWorDis "RAAlrWorDis";
BA_ "CompuMethodName" SG_ 844 IACCPreSpdLimtCmd "IACCPreSpdLimtCmd";
BA_ "ISignalName" SG_ 844 IACCPreSpdLimtCmd "IIACCPreSpdLimtCmd";
BA_ "LongName" SG_ 844 IACCPreSpdLimtCmd "Intelligent ACC prediction speed limit command";
BA_ "SysSignalName" SG_ 844 IACCPreSpdLimtCmd "IACCPreSpdLimtCmd";
BA_ "CompuMethodName" SG_ 844 IACCPreMsgReq "IACCPreMsgReq";
BA_ "ISignalName" SG_ 844 IACCPreMsgReq "IIACCPreMsgReq";
BA_ "LongName" SG_ 844 IACCPreMsgReq "Intelligent ACC prediction message request";
BA_ "SysSignalName" SG_ 844 IACCPreMsgReq "IACCPreMsgReq";
BA_ "CompuMethodName" SG_ 844 TgtParkingFavorite "TgtParkingFavorite";
BA_ "ISignalName" SG_ 844 TgtParkingFavorite "ITgtParkingFavorite";
BA_ "LongName" SG_ 844 TgtParkingFavorite "Target Parking Favorite";
BA_ "SysSignalName" SG_ 844 TgtParkingFavorite "TgtParkingFavorite";
BA_ "CompuMethodName" SG_ 844 IPDWtrClntInltFlwReq "IPDWtrClntInltFlwReq";
BA_ "ISignalName" SG_ 844 IPDWtrClntInltFlwReq "IIPDWtrClntInltFlwReq";
BA_ "LongName" SG_ 844 IPDWtrClntInltFlwReq "IPD_water_coolant_inlet_flow_request";
BA_ "SysSignalName" SG_ 844 IPDWtrClntInltFlwReq "IPDWtrClntInltFlwReq";
BA_ "CompuMethodName" SG_ 844 IPDAVCamrHeatReq "IPDAVCamrHeatReq";
BA_ "ISignalName" SG_ 844 IPDAVCamrHeatReq "IIPDAVCamrHeatReq";
BA_ "SysSignalName" SG_ 844 IPDAVCamrHeatReq "IPDAVCamrHeatReq";
BA_ "CompuMethodName" SG_ 844 IPDWtrClntInltTimeReq "IPDWtrClntInltTimeReq";
BA_ "ISignalName" SG_ 844 IPDWtrClntInltTimeReq "IIPDWtrClntInltTimeReq";
BA_ "LongName" SG_ 844 IPDWtrClntInltTimeReq "IPD_water_coolant_inlet_Time_request";
BA_ "SysSignalName" SG_ 844 IPDWtrClntInltTimeReq "IPDWtrClntInltTimeReq";
BA_ "CompuMethodName" SG_ 844 SpdLmtOfstSetNumResp "SpdLmtOfstSetNumResp";
BA_ "ISignalName" SG_ 844 SpdLmtOfstSetNumResp "ISpdLmtOfstSetNumResp";
BA_ "LongName" SG_ 844 SpdLmtOfstSetNumResp "Speed Limit Offset Set Number_Response";
BA_ "SysSignalName" SG_ 844 SpdLmtOfstSetNumResp "SpdLmtOfstSetNumResp";
BA_ "CompuMethodName" SG_ 844 TJAICAMsgReq "TJAICAMsgReq";
BA_ "ISignalName" SG_ 844 TJAICAMsgReq "ITJAICAMsgReq";
BA_ "LongName" SG_ 844 TJAICAMsgReq "Traffic_Jam_Assist_Integrated_Cruise_Assist_Message_Request";
BA_ "SysSignalName" SG_ 844 TJAICAMsgReq "TJAICAMsgReq";
BA_ "CompuMethodName" SG_ 844 SpdLmtOfstSetPercResp "SpdLmtOfstSetPercResp";
BA_ "ISignalName" SG_ 844 SpdLmtOfstSetPercResp "ISpdLmtOfstSetPercResp";
BA_ "LongName" SG_ 844 SpdLmtOfstSetPercResp "Speed Limit Offset Set Percent_Response";
BA_ "SysSignalName" SG_ 844 SpdLmtOfstSetPercResp "SpdLmtOfstSetPercResp";
BA_ "CompuMethodName" SG_ 844 ACCStsSw "ACCStsSw";
BA_ "ISignalName" SG_ 844 ACCStsSw "IACCStsSw";
BA_ "LongName" SG_ 844 ACCStsSw "ACC status switch";
BA_ "SysSignalName" SG_ 844 ACCStsSw "ACCStsSw";
BA_ "CompuMethodName" SG_ 844 ACCSpdLimtSw "ACCSpdLimtSw";
BA_ "ISignalName" SG_ 844 ACCSpdLimtSw "IACCSpdLimtSw";
BA_ "LongName" SG_ 844 ACCSpdLimtSw "ACC speed limit swtich";
BA_ "SysSignalName" SG_ 844 ACCSpdLimtSw "ACCSpdLimtSw";
BA_ "CompuMethodName" SG_ 844 SpdLimitManualSts "SpdLimitManualSts";
BA_ "ISignalName" SG_ 844 SpdLimitManualSts "ISpdLimitManualSts";
BA_ "LongName" SG_ 844 SpdLimitManualSts "Speed limit manual status";
BA_ "SysSignalName" SG_ 844 SpdLimitManualSts "SpdLimitManualSts";
BA_ "CompuMethodName" SG_ 844 NonDirectDMSSwDspCmd "NonDirectDMSSwDspCmd";
BA_ "ISignalName" SG_ 844 NonDirectDMSSwDspCmd "INonDirectDMSSwDspCmd";
BA_ "LongName" SG_ 844 NonDirectDMSSwDspCmd "Non-directional_Driver_Monitor_System_Switch_Display_Command";
BA_ "SysSignalName" SG_ 844 NonDirectDMSSwDspCmd "NonDirectDMSSwDspCmd";
BA_ "CompuMethodName" SG_ 844 CCSpdlVcCmdSwReqDspCmd "CCSpdlVcCmdSwReqDspCmd";
BA_ "ISignalName" SG_ 844 CCSpdlVcCmdSwReqDspCmd "ICCSpdlVcCmdSwReqDspCmd";
BA_ "LongName" SG_ 844 CCSpdlVcCmdSwReqDspCmd "Cruise_Control_Speed_Voice_Command_Switch_Request_Display_Command";
BA_ "SysSignalName" SG_ 844 CCSpdlVcCmdSwReqDspCmd "CCSpdlVcCmdSwReqDspCmd";
BA_ "CompuMethodName" SG_ 844 ADAudioSWSts "ADAudioSWSts";
BA_ "ISignalName" SG_ 844 ADAudioSWSts "IADAudioSWSts";
BA_ "LongName" SG_ 844 ADAudioSWSts "AD audio switch status";
BA_ "SysSignalName" SG_ 844 ADAudioSWSts "ADAudioSWSts";
BA_ "CompuMethodName" SG_ 844 SpdLmtMdMsgReq "SpdLmtMdMsgReq";
BA_ "ISignalName" SG_ 844 SpdLmtMdMsgReq "ISpdLmtMdMsgReq";
BA_ "LongName" SG_ 844 SpdLmtMdMsgReq "Speed_Limit_Mode_Message_Request";
BA_ "SysSignalName" SG_ 844 SpdLmtMdMsgReq "SpdLmtMdMsgReq";
BA_ "CompuMethodName" SG_ 844 NonDirectDMSSysSts "NonDirectDMSSysSts";
BA_ "ISignalName" SG_ 844 NonDirectDMSSysSts "INonDirectDMSSysSts";
BA_ "LongName" SG_ 844 NonDirectDMSSysSts "Non-directional_Driver_Monitor_System_System_Status";
BA_ "SysSignalName" SG_ 844 NonDirectDMSSysSts "NonDirectDMSSysSts";
BA_ "CompuMethodName" SG_ 844 ParkngEndDis "ParkngEndDis";
BA_ "ISignalName" SG_ 844 ParkngEndDis "IParkngEndDis";
BA_ "LongName" SG_ 844 ParkngEndDis "Parking to End Distance";
BA_ "SysSignalName" SG_ 844 ParkngEndDis "ParkngEndDis";
BA_ "CompuMethodName" SG_ 844 IACCOvTSuppresCmd "IACCOvTSuppresCmd";
BA_ "ISignalName" SG_ 844 IACCOvTSuppresCmd "IIACCOvTSuppresCmd";
BA_ "LongName" SG_ 844 IACCOvTSuppresCmd "Intelligent ACC Overtaking Suppres Command";
BA_ "SysSignalName" SG_ 844 IACCOvTSuppresCmd "IACCOvTSuppresCmd";
BA_ "CompuMethodName" SG_ 755 LADSInfoDispReqToICM_HPP "LADSInfoDispReqToICM_HPP";
BA_ "ISignalName" SG_ 755 LADSInfoDispReqToICM_HPP "ILADSInfoDispReqToICM_HPP";
BA_ "LongName" SG_ 755 LADSInfoDispReqToICM_HPP "Advance_Park_Assist_Information_Display_Request_HPP";
BA_ "SysSignalName" SG_ 755 LADSInfoDispReqToICM_HPP "LADSInfoDispReqToICM_HPP";
BA_ "CompuMethodName" SG_ 755 ESSAdoWrnngDspCmd "ESSAdoWrnngDspCmd";
BA_ "GenSigStartValue" SG_ 755 ESSAdoWrnngDspCmd 2;
BA_ "ISignalName" SG_ 755 ESSAdoWrnngDspCmd "IESSAdoWrnngDspCmd";
BA_ "LongName" SG_ 755 ESSAdoWrnngDspCmd "Emergency_Steering_System Audio Warning Display Command";
BA_ "SysSignalName" SG_ 755 ESSAdoWrnngDspCmd "ESSAdoWrnngDspCmd";
BA_ "CompuMethodName" SG_ 755 HPPFnSts "HPPFnSts";
BA_ "ISignalName" SG_ 755 HPPFnSts "IHPPFnSts";
BA_ "LongName" SG_ 755 HPPFnSts "HPP_Function_Status";
BA_ "SysSignalName" SG_ 755 HPPFnSts "HPPFnSts";
BA_ "CompuMethodName" SG_ 755 HPPInBmtSts "HPPInBmtSts";
BA_ "ISignalName" SG_ 755 HPPInBmtSts "IHPPInBmtSts";
BA_ "LongName" SG_ 755 HPPInBmtSts "HPP_In_Basement_Status";
BA_ "SysSignalName" SG_ 755 HPPInBmtSts "HPPInBmtSts";
BA_ "CompuMethodName" SG_ 755 LADSCurToEndPntDist "LADSCurToEndPntDist";
BA_ "ISignalName" SG_ 755 LADSCurToEndPntDist "ILADSCurToEndPntDist";
BA_ "LongName" SG_ 755 LADSCurToEndPntDist "Low Speed Automated Driving System Current To End Point Distance";
BA_ "SysSignalName" SG_ 755 LADSCurToEndPntDist "LADSCurToEndPntDist";
BA_ "CompuMethodName" SG_ 755 ESSDspCmd "ESSDspCmd";
BA_ "GenSigStartValue" SG_ 755 ESSDspCmd 2;
BA_ "ISignalName" SG_ 755 ESSDspCmd "IESSDspCmd";
BA_ "LongName" SG_ 755 ESSDspCmd "Emergency_Steering_Display_Command";
BA_ "SysSignalName" SG_ 755 ESSDspCmd "ESSDspCmd";
BA_ "CompuMethodName" SG_ 755 NOACitySysMsg "NOACitySysMsg";
BA_ "ISignalName" SG_ 755 NOACitySysMsg "INOACitySysMsg";
BA_ "LongName" SG_ 755 NOACitySysMsg "Navigation  On AutoPilot City
System
  Message";
BA_ "SysSignalName" SG_ 755 NOACitySysMsg "NOACitySysMsg";
BA_ "CompuMethodName" SG_ 755 FLSUSSSts "FLSUSSSts";
BA_ "ISignalName" SG_ 755 FLSUSSSts "IFLSUSSSts";
BA_ "LongName" SG_ 755 FLSUSSSts "Front Left Side USS Status";
BA_ "SysSignalName" SG_ 755 FLSUSSSts "FLSUSSSts";
BA_ "CompuMethodName" SG_ 755 NOPSysMsg "NOPSysMsg";
BA_ "GenSigStartValue" SG_ 755 NOPSysMsg 1;
BA_ "ISignalName" SG_ 755 NOPSysMsg "INOPSysMsg";
BA_ "LongName" SG_ 755 NOPSysMsg "Navigation On Pilot System Message";
BA_ "SysSignalName" SG_ 755 NOPSysMsg "NOPSysMsg";
BA_ "CompuMethodName" SG_ 755 LCRInHMI "LCRInHMI";
BA_ "ISignalName" SG_ 755 LCRInHMI "ILCRInHMI";
BA_ "LongName" SG_ 755 LCRInHMI "Lane Change Recommendation In Human Machine Interface";
BA_ "SysSignalName" SG_ 755 LCRInHMI "LCRInHMI";
BA_ "CompuMethodName" SG_ 755 NOADistDecMsg "NOADistDecMsg";
BA_ "ISignalName" SG_ 755 NOADistDecMsg "INOADistDecMsg";
BA_ "LongName" SG_ 755 NOADistDecMsg "NOA distance decrease Message";
BA_ "SysSignalName" SG_ 755 NOADistDecMsg "NOADistDecMsg";
BA_ "CompuMethodName" SG_ 755 NarRoVslAssSwResp "NarRoVslAssSwResp";
BA_ "ISignalName" SG_ 755 NarRoVslAssSwResp "INarRoVslAssSwResp";
BA_ "LongName" SG_ 755 NarRoVslAssSwResp "Narrow road Visual Assist Switch Response";
BA_ "SysSignalName" SG_ 755 NarRoVslAssSwResp "NarRoVslAssSwResp";
BA_ "CompuMethodName" SG_ 755 NrwroadBwdAssMesg "NrwroadBwdAssMesg";
BA_ "ISignalName" SG_ 755 NrwroadBwdAssMesg "INrwroadBwdAssMesg";
BA_ "LongName" SG_ 755 NrwroadBwdAssMesg "Narrow road Backward Assistance Message";
BA_ "SysSignalName" SG_ 755 NrwroadBwdAssMesg "NrwroadBwdAssMesg";
BA_ "CompuMethodName" SG_ 755 JAMsgReq "JAMsgReq";
BA_ "ISignalName" SG_ 755 JAMsgReq "IJAMsgReq";
BA_ "LongName" SG_ 755 JAMsgReq "Junction Assist Message Request";
BA_ "SysSignalName" SG_ 755 JAMsgReq "JAMsgReq";
BA_ "CompuMethodName" SG_ 755 DetourMsgReq "DetourMsgReq";
BA_ "ISignalName" SG_ 755 DetourMsgReq "IDetourMsgReq";
BA_ "LongName" SG_ 755 DetourMsgReq "Detour Message Request";
BA_ "SysSignalName" SG_ 755 DetourMsgReq "DetourMsgReq";
BA_ "CompuMethodName" SG_ 755 ParkngOutDircnSelResult "ParkngOutDircnSelResult";
BA_ "ISignalName" SG_ 755 ParkngOutDircnSelResult "IParkngOutDircnSelResult";
BA_ "LongName" SG_ 755 ParkngOutDircnSelResult "Parking Out Direction Select Result";
BA_ "SysSignalName" SG_ 755 ParkngOutDircnSelResult "ParkngOutDircnSelResult";
BA_ "CompuMethodName" SG_ 755 NOAQukChgSwDspCmd "NOAQukChgSwDspCmd";
BA_ "ISignalName" SG_ 755 NOAQukChgSwDspCmd "INOAQukChgSwDspCmd";
BA_ "LongName" SG_ 755 NOAQukChgSwDspCmd "NOA quickly change Switch Display Command";
BA_ "SysSignalName" SG_ 755 NOAQukChgSwDspCmd "NOAQukChgSwDspCmd";
BA_ "CompuMethodName" SG_ 755 NrwroadBwdAssSwSts "NrwroadBwdAssSwSts";
BA_ "ISignalName" SG_ 755 NrwroadBwdAssSwSts "INrwroadBwdAssSwSts";
BA_ "LongName" SG_ 755 NrwroadBwdAssSwSts "Narrow road Backward Assistance Switch Status";
BA_ "SysSignalName" SG_ 755 NrwroadBwdAssSwSts "NrwroadBwdAssSwSts";
BA_ "CompuMethodName" SG_ 755 FLUSSSts "FLUSSSts";
BA_ "ISignalName" SG_ 755 FLUSSSts "IFLUSSSts";
BA_ "LongName" SG_ 755 FLUSSSts "Front Left USS Status";
BA_ "SysSignalName" SG_ 755 FLUSSSts "FLUSSSts";
BA_ "CompuMethodName" SG_ 755 PEBSts "PEBSts";
BA_ "ISignalName" SG_ 755 PEBSts "IPEBSts";
BA_ "LongName" SG_ 755 PEBSts "Parking_Emergency_Brake_Status";
BA_ "SysSignalName" SG_ 755 PEBSts "PEBSts";
BA_ "CompuMethodName" SG_ 755 FrtCarGoNotfrDspCmd "FrtCarGoNotfrDspCmd";
BA_ "ISignalName" SG_ 755 FrtCarGoNotfrDspCmd "IFrtCarGoNotfrDspCmd";
BA_ "LongName" SG_ 755 FrtCarGoNotfrDspCmd "FrontCar GoNotifierDisplayCommand";
BA_ "SysSignalName" SG_ 755 FrtCarGoNotfrDspCmd "FrtCarGoNotfrDspCmd";
BA_ "CompuMethodName" SG_ 755 FRSUSSSts "FRSUSSSts";
BA_ "ISignalName" SG_ 755 FRSUSSSts "IFRSUSSSts";
BA_ "LongName" SG_ 755 FRSUSSSts "Front Right Side USS Status";
BA_ "SysSignalName" SG_ 755 FRSUSSSts "FRSUSSSts";
BA_ "CompuMethodName" SG_ 755 FMRUSSSts "FMRUSSSts";
BA_ "ISignalName" SG_ 755 FMRUSSSts "IFMRUSSSts";
BA_ "LongName" SG_ 755 FMRUSSSts "Front Middle Right USS Status";
BA_ "SysSignalName" SG_ 755 FMRUSSSts "FMRUSSSts";
BA_ "CompuMethodName" SG_ 755 FMLUSSSts "FMLUSSSts";
BA_ "ISignalName" SG_ 755 FMLUSSSts "IFMLUSSSts";
BA_ "LongName" SG_ 755 FMLUSSSts "Front Middle Left USS Status";
BA_ "SysSignalName" SG_ 755 FMLUSSSts "FMLUSSSts";
BA_ "CompuMethodName" SG_ 755 NOALaneSetDspCmd "NOALaneSetDspCmd";
BA_ "ISignalName" SG_ 755 NOALaneSetDspCmd "INOALaneSetDspCmd";
BA_ "LongName" SG_ 755 NOALaneSetDspCmd "NOA Lane Set Display Command";
BA_ "SysSignalName" SG_ 755 NOALaneSetDspCmd "NOALaneSetDspCmd";
BA_ "CompuMethodName" SG_ 755 NOAETCSetDspCmd "NOAETCSetDspCmd";
BA_ "ISignalName" SG_ 755 NOAETCSetDspCmd "INOAETCSetDspCmd";
BA_ "LongName" SG_ 755 NOAETCSetDspCmd "NOA ETC Set Display Command";
BA_ "SysSignalName" SG_ 755 NOAETCSetDspCmd "NOAETCSetDspCmd";
BA_ "CompuMethodName" SG_ 755 LCRSwDspCmd "LCRSwDspCmd";
BA_ "ISignalName" SG_ 755 LCRSwDspCmd "ILCRSwDspCmd";
BA_ "LongName" SG_ 755 LCRSwDspCmd "Lane Change Recommendation Switch Display Command";
BA_ "SysSignalName" SG_ 755 LCRSwDspCmd "LCRSwDspCmd";
BA_ "CompuMethodName" SG_ 755 FRUSSSts "FRUSSSts";
BA_ "ISignalName" SG_ 755 FRUSSSts "IFRUSSSts";
BA_ "LongName" SG_ 755 FRUSSSts "Front Right USS Status";
BA_ "SysSignalName" SG_ 755 FRUSSSts "FRUSSSts";
BA_ "CompuMethodName" SG_ 755 NOPCitySwDspCmd "NOPCitySwDspCmd";
BA_ "ISignalName" SG_ 755 NOPCitySwDspCmd "INOPCitySwDspCmd";
BA_ "LongName" SG_ 755 NOPCitySwDspCmd "Navigation On Pilot City Display Command";
BA_ "SysSignalName" SG_ 755 NOPCitySwDspCmd "NOPCitySwDspCmd";
BA_ "CompuMethodName" SG_ 755 NOPSwDspCmd "NOPSwDspCmd";
BA_ "ISignalName" SG_ 755 NOPSwDspCmd "INOPSwDspCmd";
BA_ "LongName" SG_ 755 NOPSwDspCmd "Nop Switch Request Display Command";
BA_ "SysSignalName" SG_ 755 NOPSwDspCmd "NOPSwDspCmd";
BA_ "CompuMethodName" SG_ 755 NOAReportSetDspCmd "NOAReportSetDspCmd";
BA_ "ISignalName" SG_ 755 NOAReportSetDspCmd "INOAReportSetDspCmd";
BA_ "LongName" SG_ 755 NOAReportSetDspCmd "NOA Report Set Display Command";
BA_ "SysSignalName" SG_ 755 NOAReportSetDspCmd "NOAReportSetDspCmd";
BA_ "CompuMethodName" SG_ 755 RLUSSSts "RLUSSSts";
BA_ "ISignalName" SG_ 755 RLUSSSts "IRLUSSSts";
BA_ "LongName" SG_ 755 RLUSSSts "Rear Left USS Status";
BA_ "SysSignalName" SG_ 755 RLUSSSts "RLUSSSts";
BA_ "CompuMethodName" SG_ 755 RLSUSSSts "RLSUSSSts";
BA_ "ISignalName" SG_ 755 RLSUSSSts "IRLSUSSSts";
BA_ "LongName" SG_ 755 RLSUSSSts "Rear Left Side USS Status";
BA_ "SysSignalName" SG_ 755 RLSUSSSts "RLSUSSSts";
BA_ "CompuMethodName" SG_ 755 PEBWarngReq "PEBWarngReq";
BA_ "ISignalName" SG_ 755 PEBWarngReq "IPEBWarngReq";
BA_ "LongName" SG_ 755 PEBWarngReq "Parking_Emergency_Brake_Warning_Request";
BA_ "SysSignalName" SG_ 755 PEBWarngReq "PEBWarngReq";
BA_ "CompuMethodName" SG_ 755 NrwroadBwdAssConfrmSwDscmd "NrwroadBwdAssConfrmSwDscmd";
BA_ "ISignalName" SG_ 755 NrwroadBwdAssConfrmSwDscmd "INrwroadBwdAssConfrmSwDscmd";
BA_ "LongName" SG_ 755 NrwroadBwdAssConfrmSwDscmd "Narrow road Backward Assistance Conform Switch Display command";
BA_ "SysSignalName" SG_ 755 NrwroadBwdAssConfrmSwDscmd "NrwroadBwdAssConfrmSwDscmd";
BA_ "CompuMethodName" SG_ 755 RRUSSSts "RRUSSSts";
BA_ "ISignalName" SG_ 755 RRUSSSts "IRRUSSSts";
BA_ "LongName" SG_ 755 RRUSSSts "Rear Right USS Status";
BA_ "SysSignalName" SG_ 755 RRUSSSts "RRUSSSts";
BA_ "CompuMethodName" SG_ 755 RRSUSSSts "RRSUSSSts";
BA_ "ISignalName" SG_ 755 RRSUSSSts "IRRSUSSSts";
BA_ "LongName" SG_ 755 RRSUSSSts "Rear Right Side USS Status";
BA_ "SysSignalName" SG_ 755 RRSUSSSts "RRSUSSSts";
BA_ "CompuMethodName" SG_ 755 RMRUSSSts "RMRUSSSts";
BA_ "ISignalName" SG_ 755 RMRUSSSts "IRMRUSSSts";
BA_ "LongName" SG_ 755 RMRUSSSts "Rear Middle Right USS Status";
BA_ "SysSignalName" SG_ 755 RMRUSSSts "RMRUSSSts";
BA_ "CompuMethodName" SG_ 755 RMLUSSSts "RMLUSSSts";
BA_ "ISignalName" SG_ 755 RMLUSSSts "IRMLUSSSts";
BA_ "LongName" SG_ 755 RMLUSSSts "Rear Middle Left USS Status";
BA_ "SysSignalName" SG_ 755 RMLUSSSts "RMLUSSSts";
BA_ "CompuMethodName" SG_ 755 ParkngOutFRCrsSts "ParkngOutFRCrsSts";
BA_ "ISignalName" SG_ 755 ParkngOutFRCrsSts "IParkngOutFRCrsSts";
BA_ "LongName" SG_ 755 ParkngOutFRCrsSts "Parking Out Front Right Cross Status";
BA_ "SysSignalName" SG_ 755 ParkngOutFRCrsSts "ParkngOutFRCrsSts";
BA_ "CompuMethodName" SG_ 755 ParkngOutFLParllSts "ParkngOutFLParllSts";
BA_ "ISignalName" SG_ 755 ParkngOutFLParllSts "IParkngOutFLParllSts";
BA_ "LongName" SG_ 755 ParkngOutFLParllSts "Parking Out Front Left Parallel Status";
BA_ "SysSignalName" SG_ 755 ParkngOutFLParllSts "ParkngOutFLParllSts";
BA_ "CompuMethodName" SG_ 755 ParkngOutFLCrsSts "ParkngOutFLCrsSts";
BA_ "ISignalName" SG_ 755 ParkngOutFLCrsSts "IParkngOutFLCrsSts";
BA_ "LongName" SG_ 755 ParkngOutFLCrsSts "Parking Out Front Left Cross Status";
BA_ "SysSignalName" SG_ 755 ParkngOutFLCrsSts "ParkngOutFLCrsSts";
BA_ "CompuMethodName" SG_ 755 ParkngOutBkRCrsSts "ParkngOutBkRCrsSts";
BA_ "ISignalName" SG_ 755 ParkngOutBkRCrsSts "IParkngOutBkRCrsSts";
BA_ "LongName" SG_ 755 ParkngOutBkRCrsSts "Parking Out Back Right Cross Status";
BA_ "SysSignalName" SG_ 755 ParkngOutBkRCrsSts "ParkngOutBkRCrsSts";
BA_ "CompuMethodName" SG_ 755 ParkngOutBkLCrsSts "ParkngOutBkLCrsSts";
BA_ "ISignalName" SG_ 755 ParkngOutBkLCrsSts "IParkngOutBkLCrsSts";
BA_ "LongName" SG_ 755 ParkngOutBkLCrsSts "Parking Out Back Left Cross Status";
BA_ "SysSignalName" SG_ 755 ParkngOutBkLCrsSts "ParkngOutBkLCrsSts";
BA_ "CompuMethodName" SG_ 755 ParkngOutBkCrsSts "ParkngOutBkCrsSts";
BA_ "ISignalName" SG_ 755 ParkngOutBkCrsSts "IParkngOutBkCrsSts";
BA_ "LongName" SG_ 755 ParkngOutBkCrsSts "Parking Out Back Cross Status";
BA_ "SysSignalName" SG_ 755 ParkngOutBkCrsSts "ParkngOutBkCrsSts";
BA_ "CompuMethodName" SG_ 755 HPPOnRoutSts "HPPOnRoutSts";
BA_ "ISignalName" SG_ 755 HPPOnRoutSts "IHPPOnRoutSts";
BA_ "LongName" SG_ 755 HPPOnRoutSts "HPP_On_Rout_Ststus";
BA_ "SysSignalName" SG_ 755 HPPOnRoutSts "HPPOnRoutSts";
BA_ "CompuMethodName" SG_ 755 HPPMapBuildSts "HPPMapBuildSts";
BA_ "ISignalName" SG_ 755 HPPMapBuildSts "IHPPMapBuildSts";
BA_ "LongName" SG_ 755 HPPMapBuildSts "HPP_Map_Build_Status";
BA_ "SysSignalName" SG_ 755 HPPMapBuildSts "HPPMapBuildSts";
BA_ "CompuMethodName" SG_ 755 ParkngDirAvlSts "ParkngDirAvlSts";
BA_ "ISignalName" SG_ 755 ParkngDirAvlSts "IParkngDirAvlSts";
BA_ "LongName" SG_ 755 ParkngDirAvlSts "Parking_Direct_Available_Status";
BA_ "SysSignalName" SG_ 755 ParkngDirAvlSts "ParkngDirAvlSts";
BA_ "CompuMethodName" SG_ 755 ParkngDirSwResp "ParkngDirSwResp";
BA_ "ISignalName" SG_ 755 ParkngDirSwResp "IParkngDirSwResp";
BA_ "LongName" SG_ 755 ParkngDirSwResp "Parking_Direction_Switch_Response";
BA_ "SysSignalName" SG_ 755 ParkngDirSwResp "ParkngDirSwResp";
BA_ "CompuMethodName" SG_ 755 ParkngSlotFindSts "ParkngSlotFindSts";
BA_ "ISignalName" SG_ 755 ParkngSlotFindSts "IParkngSlotFindSts";
BA_ "LongName" SG_ 755 ParkngSlotFindSts "Parking Slot Find Status";
BA_ "SysSignalName" SG_ 755 ParkngSlotFindSts "ParkngSlotFindSts";
BA_ "CompuMethodName" SG_ 755 ParkngOutFrtCrsSts "ParkngOutFrtCrsSts";
BA_ "ISignalName" SG_ 755 ParkngOutFrtCrsSts "IParkngOutFrtCrsSts";
BA_ "LongName" SG_ 755 ParkngOutFrtCrsSts "Parking Out Front Cross Status";
BA_ "SysSignalName" SG_ 755 ParkngOutFrtCrsSts "ParkngOutFrtCrsSts";
BA_ "CompuMethodName" SG_ 755 ParkngOutFRParllSts "ParkngOutFRParllSts";
BA_ "ISignalName" SG_ 755 ParkngOutFRParllSts "IParkngOutFRParllSts";
BA_ "LongName" SG_ 755 ParkngOutFRParllSts "Parking Out Front Right Parallel Status";
BA_ "SysSignalName" SG_ 755 ParkngOutFRParllSts "ParkngOutFRParllSts";
BA_ "CompuMethodName" SG_ 755 PEBSwResp "PEBSwResp";
BA_ "ISignalName" SG_ 755 PEBSwResp "IPEBSwResp";
BA_ "LongName" SG_ 755 PEBSwResp "Parking_Emergency_Brake_Switch_Response";
BA_ "SysSignalName" SG_ 755 PEBSwResp "PEBSwResp";
BA_ "CompuMethodName" SG_ 774 TrfcMrgdForbidDist "TrfcMrgdForbidDist";
BA_ "ISignalName" SG_ 774 TrfcMrgdForbidDist "ITrfcMrgdForbidDist";
BA_ "LongName" SG_ 774 TrfcMrgdForbidDist "Traffic_Merged_Forbid_Sign_Distance";
BA_ "SysSignalName" SG_ 774 TrfcMrgdForbidDist "TrfcMrgdForbidDist";
BA_ "CompuMethodName" SG_ 774 TrfcMrgdInfoSignDist "TrfcMrgdInfoSignDist";
BA_ "ISignalName" SG_ 774 TrfcMrgdInfoSignDist "ITrfcMrgdInfoSignDist";
BA_ "LongName" SG_ 774 TrfcMrgdInfoSignDist "Traffic_Merged_Information_Sign_Distance";
BA_ "SysSignalName" SG_ 774 TrfcMrgdInfoSignDist "TrfcMrgdInfoSignDist";
BA_ "CompuMethodName" SG_ 774 TrfcMrgdWrnngSignDist "TrfcMrgdWrnngSignDist";
BA_ "ISignalName" SG_ 774 TrfcMrgdWrnngSignDist "ITrfcMrgdWrnngSignDist";
BA_ "LongName" SG_ 774 TrfcMrgdWrnngSignDist "Traffic_Merged_Warnning_Sign_Distance";
BA_ "SysSignalName" SG_ 774 TrfcMrgdWrnngSignDist "TrfcMrgdWrnngSignDist";
BA_ "CompuMethodName" SG_ 774 ParkngInPrgs "ParkngInPrgs";
BA_ "ISignalName" SG_ 774 ParkngInPrgs "IParkngInPrgs";
BA_ "LongName" SG_ 774 ParkngInPrgs "Parking Progress";
BA_ "SysSignalName" SG_ 774 ParkngInPrgs "ParkngInPrgs";
BA_ "CompuMethodName" SG_ 774 ParkngNCPAvlSts "ParkngNCPAvlSts";
BA_ "ISignalName" SG_ 774 ParkngNCPAvlSts "IParkngNCPAvlSts";
BA_ "LongName" SG_ 774 ParkngNCPAvlSts "Parking_Non_Centered_Parking_Available_Status";
BA_ "SysSignalName" SG_ 774 ParkngNCPAvlSts "ParkngNCPAvlSts";
BA_ "CompuMethodName" SG_ 774 TrfcLghtFuctionSwSts "TrfcLghtFuctionSwSts";
BA_ "ISignalName" SG_ 774 TrfcLghtFuctionSwSts "ITrfcLghtFuctionSwSts";
BA_ "LongName" SG_ 774 TrfcLghtFuctionSwSts "Traffic Light Fuction Switch Status";
BA_ "SysSignalName" SG_ 774 TrfcLghtFuctionSwSts "TrfcLghtFuctionSwSts";
BA_ "CompuMethodName" SG_ 774 APASpdMdSwSts "APASpdMdSwSts";
BA_ "GenSigStartValue" SG_ 774 APASpdMdSwSts 1;
BA_ "ISignalName" SG_ 774 APASpdMdSwSts "IAPASpdMdSwSts";
BA_ "LongName" SG_ 774 APASpdMdSwSts "Advanced Park Assist Speed Mode Switch Status";
BA_ "SysSignalName" SG_ 774 APASpdMdSwSts "APASpdMdSwSts";
BA_ "CompuMethodName" SG_ 774 TrfcMrgdWrnngSign "TrfcMrgdWrnngSign";
BA_ "ISignalName" SG_ 774 TrfcMrgdWrnngSign "ITrfcMrgdWrnngSign";
BA_ "LongName" SG_ 774 TrfcMrgdWrnngSign "Traffic_Merged_Warnning_Sign";
BA_ "SysSignalName" SG_ 774 TrfcMrgdWrnngSign "TrfcMrgdWrnngSign";
BA_ "CompuMethodName" SG_ 774 TrfcMrgdForbidSign "TrfcMrgdForbidSign";
BA_ "ISignalName" SG_ 774 TrfcMrgdForbidSign "ITrfcMrgdForbidSign";
BA_ "LongName" SG_ 774 TrfcMrgdForbidSign "Traffic_Merged_Forbid_Sign";
BA_ "SysSignalName" SG_ 774 TrfcMrgdForbidSign "TrfcMrgdForbidSign";
BA_ "CompuMethodName" SG_ 774 TrfcMrgdInfoSign "TrfcMrgdInfoSign";
BA_ "ISignalName" SG_ 774 TrfcMrgdInfoSign "ITrfcMrgdInfoSign";
BA_ "LongName" SG_ 774 TrfcMrgdInfoSign "Traffic_Merged_Information_Sign";
BA_ "SysSignalName" SG_ 774 TrfcMrgdInfoSign "TrfcMrgdInfoSign";
BA_ "CompuMethodName" SG_ 208 APAParkInOffsetType "APAParkInOffsetType";
BA_ "ISignalName" SG_ 208 APAParkInOffsetType "IAPAParkInOffsetType";
BA_ "LongName" SG_ 208 APAParkInOffsetType "apa_park_in_offset_type";
BA_ "SysSignalName" SG_ 208 APAParkInOffsetType "APAParkInOffsetType";
BA_ "CompuMethodName" SG_ 208 APARemShifGear "APARemShifGear";
BA_ "ISignalName" SG_ 208 APARemShifGear "IAPARemShifGear";
BA_ "LongName" SG_ 208 APARemShifGear "apa_remaining_shift_gear";
BA_ "SysSignalName" SG_ 208 APARemShifGear "APARemShifGear";
BA_ "CompuMethodName" SG_ 208 APASW "APASW";
BA_ "ISignalName" SG_ 208 APASW "IAPASW";
BA_ "LongName" SG_ 208 APASW "apa_switch_setting";
BA_ "SysSignalName" SG_ 208 APASW "APASW";
BA_ "CompuMethodName" SG_ 486 IPD_20ms_Group43_CRC "IPD_20ms_Group43_CRC";
BA_ "ISignalName" SG_ 486 IPD_20ms_Group43_CRC "IIPD_20ms_Group43_CRC";
BA_ "LongName" SG_ 486 IPD_20ms_Group43_CRC "IPD_20ms_Group43_CRC";
BA_ "SysSignalName" SG_ 486 IPD_20ms_Group43_CRC "IPD_20ms_Group43_CRC";
BA_ "CompuMethodName" SG_ 486 IPD_20ms_Group43_RC "IPD_20ms_Group43_RC";
BA_ "ISignalName" SG_ 486 IPD_20ms_Group43_RC "IIPD_20ms_Group43_RC";
BA_ "LongName" SG_ 486 IPD_20ms_Group43_RC "IPD_20ms_Group43_RC";
BA_ "SysSignalName" SG_ 486 IPD_20ms_Group43_RC "IPD_20ms_Group43_RC";
BA_ "CompuMethodName" SG_ 486 IPD_20ms_Group43_Reserved1 "IPD_20ms_Group43_Reserved1";
BA_ "GenSigStartValue" SG_ 486 IPD_20ms_Group43_Reserved1 15;
BA_ "ISignalName" SG_ 486 IPD_20ms_Group43_Reserved1 "IIPD_20ms_Group43_Reserved1";
BA_ "SysSignalName" SG_ 486 IPD_20ms_Group43_Reserved1 "IPD_20ms_Group43_Reserved1";
BA_ "CompuMethodName" SG_ 486 ACCAccReqToqVal "ACCAccReqToqVal";
BA_ "ISignalName" SG_ 486 ACCAccReqToqVal "IACCAccReqToqVal";
BA_ "LongName" SG_ 486 ACCAccReqToqVal "Adaptive Cruise Control Acceleration Request Torque Value";
BA_ "SysSignalName" SG_ 486 ACCAccReqToqVal "ACCAccReqToqVal";
BA_ "CompuMethodName" SG_ 486 IPD_20ms_Group43_Reserved2 "IPD_20ms_Group43_Reserved2";
BA_ "GenSigStartValue" SG_ 486 IPD_20ms_Group43_Reserved2 7;
BA_ "ISignalName" SG_ 486 IPD_20ms_Group43_Reserved2 "IIPD_20ms_Group43_Reserved2";
BA_ "SysSignalName" SG_ 486 IPD_20ms_Group43_Reserved2 "IPD_20ms_Group43_Reserved2";
BA_ "CompuMethodName" SG_ 486 FrtCarGoNotfr "FrtCarGoNotfr";
BA_ "ISignalName" SG_ 486 FrtCarGoNotfr "IFrtCarGoNotfr";
BA_ "LongName" SG_ 486 FrtCarGoNotfr "FrontCar GoNotifier";
BA_ "SysSignalName" SG_ 486 FrtCarGoNotfr "FrtCarGoNotfr";
BA_ "CompuMethodName" SG_ 486 ACCSysFltSts_SCS "ACCSysFltSts_SCS";
BA_ "ISignalName" SG_ 486 ACCSysFltSts_SCS "IACCSysFltSts_SCS";
BA_ "LongName" SG_ 486 ACCSysFltSts_SCS "Adaptive_Cruise_Control_System_Fault_Status";
BA_ "SysSignalName" SG_ 486 ACCSysFltSts_SCS "ACCSysFltSts_SCS";
BA_ "CompuMethodName" SG_ 486 IPD_20ms_Group43_Reserved3 "IPD_20ms_Group43_Reserved3";
BA_ "GenSigStartValue" SG_ 486 IPD_20ms_Group43_Reserved3 255;
BA_ "ISignalName" SG_ 486 IPD_20ms_Group43_Reserved3 "IIPD_20ms_Group43_Reserved3";
BA_ "SysSignalName" SG_ 486 IPD_20ms_Group43_Reserved3 "IPD_20ms_Group43_Reserved3";
BA_ "CompuMethodName" SG_ 486 IPD_20ms_Group43_Reserved4 "IPD_20ms_Group43_Reserved4";
BA_ "GenSigStartValue" SG_ 486 IPD_20ms_Group43_Reserved4 255;
BA_ "ISignalName" SG_ 486 IPD_20ms_Group43_Reserved4 "IIPD_20ms_Group43_Reserved4";
BA_ "SysSignalName" SG_ 486 IPD_20ms_Group43_Reserved4 "IPD_20ms_Group43_Reserved4";
BA_ "CompuMethodName" SG_ 486 IPD_20ms_Group43_Reserved5 "IPD_20ms_Group43_Reserved5";
BA_ "GenSigStartValue" SG_ 486 IPD_20ms_Group43_Reserved5 255;
BA_ "ISignalName" SG_ 486 IPD_20ms_Group43_Reserved5 "IIPD_20ms_Group43_Reserved5";
BA_ "SysSignalName" SG_ 486 IPD_20ms_Group43_Reserved5 "IPD_20ms_Group43_Reserved5";
BA_ "CompuMethodName" SG_ 337 IPD_20ms_Group60_CRC "IPD_20ms_Group60_CRC";
BA_ "ISignalName" SG_ 337 IPD_20ms_Group60_CRC "IIPD_20ms_Group60_CRC";
BA_ "LongName" SG_ 337 IPD_20ms_Group60_CRC "IPD_20ms_Group60_CRC";
BA_ "SysSignalName" SG_ 337 IPD_20ms_Group60_CRC "IPD_20ms_Group60_CRC";
BA_ "CompuMethodName" SG_ 337 IPD_20ms_Group60_RC "IPD_20ms_Group60_RC";
BA_ "ISignalName" SG_ 337 IPD_20ms_Group60_RC "IIPD_20ms_Group60_RC";
BA_ "LongName" SG_ 337 IPD_20ms_Group60_RC "IPD_20ms_Group60_RC";
BA_ "SysSignalName" SG_ 337 IPD_20ms_Group60_RC "IPD_20ms_Group60_RC";
BA_ "CompuMethodName" SG_ 337 AutoLaneChngRLaneSts "AutoLaneChngRLaneSts";
BA_ "ISignalName" SG_ 337 AutoLaneChngRLaneSts "IAutoLaneChngRLaneSts";
BA_ "LongName" SG_ 337 AutoLaneChngRLaneSts "Auto_Lane_Change_Right_Lane_Status";
BA_ "SysSignalName" SG_ 337 AutoLaneChngRLaneSts "AutoLaneChngRLaneSts";
BA_ "CompuMethodName" SG_ 337 IPD_20ms_Group60_Reserved1 "IPD_20ms_Group60_Reserved1";
BA_ "GenSigStartValue" SG_ 337 IPD_20ms_Group60_Reserved1 255;
BA_ "ISignalName" SG_ 337 IPD_20ms_Group60_Reserved1 "IIPD_20ms_Group60_Reserved1";
BA_ "SysSignalName" SG_ 337 IPD_20ms_Group60_Reserved1 "IPD_20ms_Group60_Reserved1";
BA_ "CompuMethodName" SG_ 337 IPD_20ms_Group60_Reserved2 "IPD_20ms_Group60_Reserved2";
BA_ "GenSigStartValue" SG_ 337 IPD_20ms_Group60_Reserved2 255;
BA_ "ISignalName" SG_ 337 IPD_20ms_Group60_Reserved2 "IIPD_20ms_Group60_Reserved2";
BA_ "SysSignalName" SG_ 337 IPD_20ms_Group60_Reserved2 "IPD_20ms_Group60_Reserved2";
BA_ "CompuMethodName" SG_ 337 APASCSToqReqVal "APASCSToqReqVal";
BA_ "ISignalName" SG_ 337 APASCSToqReqVal "IAPASCSToqReqVal";
BA_ "LongName" SG_ 337 APASCSToqReqVal "Advance Park Assist Stability Control System Torque Request Value";
BA_ "SysSignalName" SG_ 337 APASCSToqReqVal "APASCSToqReqVal";
BA_ "CompuMethodName" SG_ 337 APAVehCrdnatPosY "APAVehCrdnatPosY";
BA_ "ISignalName" SG_ 337 APAVehCrdnatPosY "IAPAVehCrdnatPosY";
BA_ "LongName" SG_ 337 APAVehCrdnatPosY "Advanced_Park_Assist_Vehicle_Coordinate_Position_Y";
BA_ "SysSignalName" SG_ 337 APAVehCrdnatPosY "APAVehCrdnatPosY";
BA_ "CompuMethodName" SG_ 337 APAVehCrdnatAzmth "APAVehCrdnatAzmth";
BA_ "ISignalName" SG_ 337 APAVehCrdnatAzmth "IAPAVehCrdnatAzmth";
BA_ "LongName" SG_ 337 APAVehCrdnatAzmth "Advanced_Park_Assist_Vehicle_Coordinate_Azimuth";
BA_ "SysSignalName" SG_ 337 APAVehCrdnatAzmth "APAVehCrdnatAzmth";
BA_ "CompuMethodName" SG_ 337 ESSDirInd "ESSDirInd";
BA_ "ISignalName" SG_ 337 ESSDirInd "IESSDirInd";
BA_ "LongName" SG_ 337 ESSDirInd "Emergency_Steering_System _Direction_Indication";
BA_ "SysSignalName" SG_ 337 ESSDirInd "ESSDirInd";
BA_ "CompuMethodName" SG_ 337 PilotTkovMsgReq "PilotTkovMsgReq";
BA_ "ISignalName" SG_ 337 PilotTkovMsgReq "IPilotTkovMsgReq";
BA_ "LongName" SG_ 337 PilotTkovMsgReq "Pilot Take Over Message Request";
BA_ "SysSignalName" SG_ 337 PilotTkovMsgReq "PilotTkovMsgReq";
BA_ "CompuMethodName" SG_ 337 NOPSysSts_ZPD "NOPSysSts_ZPD";
BA_ "ISignalName" SG_ 337 NOPSysSts_ZPD "INOPSysSts_ZPD";
BA_ "LongName" SG_ 337 NOPSysSts_ZPD "Navigation On Pilot System Status";
BA_ "SysSignalName" SG_ 337 NOPSysSts_ZPD "NOPSysSts_ZPD";
BA_ "CompuMethodName" SG_ 337 PrkgDstCtrlSwResp "PrkgDstCtrlSwResp";
BA_ "GenSigStartValue" SG_ 337 PrkgDstCtrlSwResp 1;
BA_ "ISignalName" SG_ 337 PrkgDstCtrlSwResp "IPrkgDstCtrlSwResp";
BA_ "LongName" SG_ 337 PrkgDstCtrlSwResp "Parking Distance Ctrl Switch Response";
BA_ "SysSignalName" SG_ 337 PrkgDstCtrlSwResp "PrkgDstCtrlSwResp";
BA_ "CompuMethodName" SG_ 337 ALCSysSts "ALCSysSts";
BA_ "ISignalName" SG_ 337 ALCSysSts "IALCSysSts";
BA_ "LongName" SG_ 337 ALCSysSts "Auto_Lane_Change_System_Status";
BA_ "SysSignalName" SG_ 337 ALCSysSts "ALCSysSts";
BA_ "CompuMethodName" SG_ 337 ALCSysFltSts "ALCSysFltSts";
BA_ "ISignalName" SG_ 337 ALCSysFltSts "IALCSysFltSts";
BA_ "LongName" SG_ 337 ALCSysFltSts "ALC System Failure Status";
BA_ "SysSignalName" SG_ 337 ALCSysFltSts "ALCSysFltSts";
BA_ "CompuMethodName" SG_ 337 APAVehCrdnatPosX "APAVehCrdnatPosX";
BA_ "ISignalName" SG_ 337 APAVehCrdnatPosX "IAPAVehCrdnatPosX";
BA_ "LongName" SG_ 337 APAVehCrdnatPosX "Advanced_Park_Assist_Vehicle_Coordinate_Position_X";
BA_ "SysSignalName" SG_ 337 APAVehCrdnatPosX "APAVehCrdnatPosX";
BA_ "CompuMethodName" SG_ 337 AutoLaneChngLLaneSts "AutoLaneChngLLaneSts";
BA_ "ISignalName" SG_ 337 AutoLaneChngLLaneSts "IAutoLaneChngLLaneSts";
BA_ "LongName" SG_ 337 AutoLaneChngLLaneSts "Auto_Lane_Change_Left_Lane_Status";
BA_ "SysSignalName" SG_ 337 AutoLaneChngLLaneSts "AutoLaneChngLLaneSts";
BA_ "CompuMethodName" SG_ 337 IPD_20ms_Group60_Reserved4 "IPD_20ms_Group60_Reserved4";
BA_ "GenSigStartValue" SG_ 337 IPD_20ms_Group60_Reserved4 3;
BA_ "ISignalName" SG_ 337 IPD_20ms_Group60_Reserved4 "IIPD_20ms_Group60_Reserved4";
BA_ "SysSignalName" SG_ 337 IPD_20ms_Group60_Reserved4 "IPD_20ms_Group60_Reserved4";
BA_ "CompuMethodName" SG_ 337 ESSSysSts "ESSSysSts";
BA_ "GenSigStartValue" SG_ 337 ESSSysSts 1;
BA_ "ISignalName" SG_ 337 ESSSysSts "IESSSysSts";
BA_ "LongName" SG_ 337 ESSSysSts "Emergency_Steering_System_Status";
BA_ "SysSignalName" SG_ 337 ESSSysSts "ESSSysSts";
BA_ "CompuMethodName" SG_ 337 ESSSysFltSts "ESSSysFltSts";
BA_ "ISignalName" SG_ 337 ESSSysFltSts "IESSSysFltSts";
BA_ "LongName" SG_ 337 ESSSysFltSts "Emergency_Steering_System_Fault_Status";
BA_ "SysSignalName" SG_ 337 ESSSysFltSts "ESSSysFltSts";
BA_ "CompuMethodName" SG_ 337 IPD_20ms_Group60_Reserved6 "IPD_20ms_Group60_Reserved6";
BA_ "GenSigStartValue" SG_ 337 IPD_20ms_Group60_Reserved6 1;
BA_ "ISignalName" SG_ 337 IPD_20ms_Group60_Reserved6 "IIPD_20ms_Group60_Reserved6";
BA_ "SysSignalName" SG_ 337 IPD_20ms_Group60_Reserved6 "IPD_20ms_Group60_Reserved6";
BA_ "CompuMethodName" SG_ 337 ESSDrvrTkovReq "ESSDrvrTkovReq";
BA_ "ISignalName" SG_ 337 ESSDrvrTkovReq "IESSDrvrTkovReq";
BA_ "LongName" SG_ 337 ESSDrvrTkovReq "Emergency_Steering_System_Takeover_Request";
BA_ "SysSignalName" SG_ 337 ESSDrvrTkovReq "ESSDrvrTkovReq";
BA_ "CompuMethodName" SG_ 337 IPD_20ms_Group60_Reserved5 "IPD_20ms_Group60_Reserved5";
BA_ "GenSigStartValue" SG_ 337 IPD_20ms_Group60_Reserved5 7;
BA_ "ISignalName" SG_ 337 IPD_20ms_Group60_Reserved5 "IIPD_20ms_Group60_Reserved5";
BA_ "SysSignalName" SG_ 337 IPD_20ms_Group60_Reserved5 "IPD_20ms_Group60_Reserved5";
BA_ "CompuMethodName" SG_ 337 Parkngslottype "Parkngslottype";
BA_ "ISignalName" SG_ 337 Parkngslottype "IParkngslottype";
BA_ "LongName" SG_ 337 Parkngslottype "Parking Slot Type";
BA_ "SysSignalName" SG_ 337 Parkngslottype "Parkngslottype";
BA_ "CompuMethodName" SG_ 337 IPD_20ms_Group60_Reserved7 "IPD_20ms_Group60_Reserved7";
BA_ "GenSigStartValue" SG_ 337 IPD_20ms_Group60_Reserved7 31;
BA_ "ISignalName" SG_ 337 IPD_20ms_Group60_Reserved7 "IIPD_20ms_Group60_Reserved7";
BA_ "SysSignalName" SG_ 337 IPD_20ms_Group60_Reserved7 "IPD_20ms_Group60_Reserved7";
BA_ "CompuMethodName" SG_ 337 NOPSysFltSts "NOPSysFltSts";
BA_ "ISignalName" SG_ 337 NOPSysFltSts "INOPSysFltSts";
BA_ "LongName" SG_ 337 NOPSysFltSts "Nop System Failure Status";
BA_ "SysSignalName" SG_ 337 NOPSysFltSts "NOPSysFltSts";
BA_ "CompuMethodName" SG_ 337 IPD_20ms_Group60_Reserved8 "IPD_20ms_Group60_Reserved8";
BA_ "GenSigStartValue" SG_ 337 IPD_20ms_Group60_Reserved8 255;
BA_ "ISignalName" SG_ 337 IPD_20ms_Group60_Reserved8 "IIPD_20ms_Group60_Reserved8";
BA_ "SysSignalName" SG_ 337 IPD_20ms_Group60_Reserved8 "IPD_20ms_Group60_Reserved8";
BA_ "CompuMethodName" SG_ 337 IPD_20ms_Group60_Reserved9 "IPD_20ms_Group60_Reserved9";
BA_ "GenSigStartValue" SG_ 337 IPD_20ms_Group60_Reserved9 255;
BA_ "ISignalName" SG_ 337 IPD_20ms_Group60_Reserved9 "IIPD_20ms_Group60_Reserved9";
BA_ "SysSignalName" SG_ 337 IPD_20ms_Group60_Reserved9 "IPD_20ms_Group60_Reserved9";
BA_ "CompuMethodName" SG_ 337 IPD_20ms_Group60_Reserved10 "IPD_20ms_Group60_Reserved10";
BA_ "GenSigStartValue" SG_ 337 IPD_20ms_Group60_Reserved10 255;
BA_ "ISignalName" SG_ 337 IPD_20ms_Group60_Reserved10 "IIPD_20ms_Group60_Reserved10";
BA_ "SysSignalName" SG_ 337 IPD_20ms_Group60_Reserved10 "IPD_20ms_Group60_Reserved10";
BA_ "CompuMethodName" SG_ 337 IPD_20ms_Group60_Reserved11 "IPD_20ms_Group60_Reserved11";
BA_ "GenSigStartValue" SG_ 337 IPD_20ms_Group60_Reserved11 255;
BA_ "ISignalName" SG_ 337 IPD_20ms_Group60_Reserved11 "IIPD_20ms_Group60_Reserved11";
BA_ "SysSignalName" SG_ 337 IPD_20ms_Group60_Reserved11 "IPD_20ms_Group60_Reserved11";
BA_ "CompuMethodName" SG_ 720 IPD_50ms_Group14_CRC "IPD_50ms_Group14_CRC";
BA_ "ISignalName" SG_ 720 IPD_50ms_Group14_CRC "IIPD_50ms_Group14_CRC";
BA_ "SysSignalName" SG_ 720 IPD_50ms_Group14_CRC "IPD_50ms_Group14_CRC";
BA_ "CompuMethodName" SG_ 720 IPD_50ms_Group14_RC "IPD_50ms_Group14_RC";
BA_ "ISignalName" SG_ 720 IPD_50ms_Group14_RC "IIPD_50ms_Group14_RC";
BA_ "SysSignalName" SG_ 720 IPD_50ms_Group14_RC "IPD_50ms_Group14_RC";
BA_ "CompuMethodName" SG_ 720 IPD_50ms_Group14_Reserved1 "IPD_50ms_Group14_Reserved1";
BA_ "GenSigStartValue" SG_ 720 IPD_50ms_Group14_Reserved1 15;
BA_ "ISignalName" SG_ 720 IPD_50ms_Group14_Reserved1 "IIPD_50ms_Group14_Reserved1";
BA_ "SysSignalName" SG_ 720 IPD_50ms_Group14_Reserved1 "IPD_50ms_Group14_Reserved1";
BA_ "CompuMethodName" SG_ 720 IPD_50ms_Group14_Reserved2 "IPD_50ms_Group14_Reserved2";
BA_ "GenSigStartValue" SG_ 720 IPD_50ms_Group14_Reserved2 255;
BA_ "ISignalName" SG_ 720 IPD_50ms_Group14_Reserved2 "IIPD_50ms_Group14_Reserved2";
BA_ "SysSignalName" SG_ 720 IPD_50ms_Group14_Reserved2 "IPD_50ms_Group14_Reserved2";
BA_ "CompuMethodName" SG_ 720 IPD_50ms_Group14_Reserved3 "IPD_50ms_Group14_Reserved3";
BA_ "GenSigStartValue" SG_ 720 IPD_50ms_Group14_Reserved3 255;
BA_ "ISignalName" SG_ 720 IPD_50ms_Group14_Reserved3 "IIPD_50ms_Group14_Reserved3";
BA_ "SysSignalName" SG_ 720 IPD_50ms_Group14_Reserved3 "IPD_50ms_Group14_Reserved3";
BA_ "CompuMethodName" SG_ 720 IPD_50ms_Group14_Reserved4 "IPD_50ms_Group14_Reserved4";
BA_ "GenSigStartValue" SG_ 720 IPD_50ms_Group14_Reserved4 255;
BA_ "ISignalName" SG_ 720 IPD_50ms_Group14_Reserved4 "IIPD_50ms_Group14_Reserved4";
BA_ "SysSignalName" SG_ 720 IPD_50ms_Group14_Reserved4 "IPD_50ms_Group14_Reserved4";
BA_ "CompuMethodName" SG_ 720 IPD_50ms_Group14_Reserved5 "IPD_50ms_Group14_Reserved5";
BA_ "GenSigStartValue" SG_ 720 IPD_50ms_Group14_Reserved5 255;
BA_ "ISignalName" SG_ 720 IPD_50ms_Group14_Reserved5 "IIPD_50ms_Group14_Reserved5";
BA_ "SysSignalName" SG_ 720 IPD_50ms_Group14_Reserved5 "IPD_50ms_Group14_Reserved5";
BA_ "CompuMethodName" SG_ 720 IPD_50ms_Group14_Reserved6 "IPD_50ms_Group14_Reserved6";
BA_ "GenSigStartValue" SG_ 720 IPD_50ms_Group14_Reserved6 255;
BA_ "ISignalName" SG_ 720 IPD_50ms_Group14_Reserved6 "IIPD_50ms_Group14_Reserved6";
BA_ "SysSignalName" SG_ 720 IPD_50ms_Group14_Reserved6 "IPD_50ms_Group14_Reserved6";
BA_ "CompuMethodName" SG_ 720 LADSInfoDispReq "LADSInfoDispReq";
BA_ "ISignalName" SG_ 720 LADSInfoDispReq "ILADSInfoDispReq";
BA_ "LongName" SG_ 720 LADSInfoDispReq "Low Speed Automated Driving System Information Display Request";
BA_ "SysSignalName" SG_ 720 LADSInfoDispReq "LADSInfoDispReq";
BA_ "CompuMethodName" SG_ 720 LADSInfoDispReqToICM "LADSInfoDispReqToICM";
BA_ "ISignalName" SG_ 720 LADSInfoDispReqToICM "ILADSInfoDispReqToICM";
BA_ "LongName" SG_ 720 LADSInfoDispReqToICM "Low Speed Automated Driving System Informaiton Display Request To Intelligent Cockpit Module";
BA_ "SysSignalName" SG_ 720 LADSInfoDispReqToICM "LADSInfoDispReqToICM";
BA_ "CompuMethodName" SG_ 720 IPD_50ms_Group14_Reserved7 "IPD_50ms_Group14_Reserved7";
BA_ "GenSigStartValue" SG_ 720 IPD_50ms_Group14_Reserved7 1;
BA_ "ISignalName" SG_ 720 IPD_50ms_Group14_Reserved7 "IIPD_50ms_Group14_Reserved7";
BA_ "SysSignalName" SG_ 720 IPD_50ms_Group14_Reserved7 "IPD_50ms_Group14_Reserved7";
BA_ "CompuMethodName" SG_ 720 LADSProgressBar "LADSProgressBar";
BA_ "ISignalName" SG_ 720 LADSProgressBar "ILADSProgressBar";
BA_ "LongName" SG_ 720 LADSProgressBar "Lads_Progress_Bar";
BA_ "SysSignalName" SG_ 720 LADSProgressBar "LADSProgressBar";
BA_ "CompuMethodName" SG_ 720 SDWLSRObsRng "SDWLSRObsRng";
BA_ "ISignalName" SG_ 720 SDWLSRObsRng "ISDWLSRObsRng";
BA_ "LongName" SG_ 720 SDWLSRObsRng "SDW Left Side Rear Obstacle Range";
BA_ "SysSignalName" SG_ 720 SDWLSRObsRng "SDWLSRObsRng";
BA_ "CompuMethodName" SG_ 720 SDWLSFObsRng "SDWLSFObsRng";
BA_ "ISignalName" SG_ 720 SDWLSFObsRng "ISDWLSFObsRng";
BA_ "LongName" SG_ 720 SDWLSFObsRng "SDW Left Side Front Obstacle Range";
BA_ "SysSignalName" SG_ 720 SDWLSFObsRng "SDWLSFObsRng";
BA_ "CompuMethodName" SG_ 720 SDWRSRObsRng "SDWRSRObsRng";
BA_ "ISignalName" SG_ 720 SDWRSRObsRng "ISDWRSRObsRng";
BA_ "LongName" SG_ 720 SDWRSRObsRng "SDW Right Side Rear Obstacle Range";
BA_ "SysSignalName" SG_ 720 SDWRSRObsRng "SDWRSRObsRng";
BA_ "CompuMethodName" SG_ 720 SDWRSFObsRng "SDWRSFObsRng";
BA_ "ISignalName" SG_ 720 SDWRSFObsRng "ISDWRSFObsRng";
BA_ "LongName" SG_ 720 SDWRSFObsRng "SDW Right Side Front Obstacle Range";
BA_ "SysSignalName" SG_ 720 SDWRSFObsRng "SDWRSFObsRng";
BA_ "CompuMethodName" SG_ 720 IPD_50ms_Group14_Reserved8 "IPD_50ms_Group14_Reserved8";
BA_ "GenSigStartValue" SG_ 720 IPD_50ms_Group14_Reserved8 255;
BA_ "ISignalName" SG_ 720 IPD_50ms_Group14_Reserved8 "IIPD_50ms_Group14_Reserved8";
BA_ "SysSignalName" SG_ 720 IPD_50ms_Group14_Reserved8 "IPD_50ms_Group14_Reserved8";
BA_ "CompuMethodName" SG_ 720 IPD_50ms_Group14_Reserved9 "IPD_50ms_Group14_Reserved9";
BA_ "GenSigStartValue" SG_ 720 IPD_50ms_Group14_Reserved9 255;
BA_ "ISignalName" SG_ 720 IPD_50ms_Group14_Reserved9 "IIPD_50ms_Group14_Reserved9";
BA_ "SysSignalName" SG_ 720 IPD_50ms_Group14_Reserved9 "IPD_50ms_Group14_Reserved9";
BA_ "CompuMethodName" SG_ 720 IPD_50ms_Group14_Reserved10 "IPD_50ms_Group14_Reserved10";
BA_ "GenSigStartValue" SG_ 720 IPD_50ms_Group14_Reserved10 255;
BA_ "ISignalName" SG_ 720 IPD_50ms_Group14_Reserved10 "IIPD_50ms_Group14_Reserved10";
BA_ "SysSignalName" SG_ 720 IPD_50ms_Group14_Reserved10 "IPD_50ms_Group14_Reserved10";
BA_ "CompuMethodName" SG_ 720 IPD_50ms_Group14_Reserved11 "IPD_50ms_Group14_Reserved11";
BA_ "GenSigStartValue" SG_ 720 IPD_50ms_Group14_Reserved11 255;
BA_ "ISignalName" SG_ 720 IPD_50ms_Group14_Reserved11 "IIPD_50ms_Group14_Reserved11";
BA_ "SysSignalName" SG_ 720 IPD_50ms_Group14_Reserved11 "IPD_50ms_Group14_Reserved11";
BA_ "CompuMethodName" SG_ 733 IPD_50ms_Group49_CRC "IPD_50ms_Group49_CRC";
BA_ "ISignalName" SG_ 733 IPD_50ms_Group49_CRC "IIPD_50ms_Group49_CRC";
BA_ "SysSignalName" SG_ 733 IPD_50ms_Group49_CRC "IPD_50ms_Group49_CRC";
BA_ "CompuMethodName" SG_ 733 IPD_50ms_Group49_RC "IPD_50ms_Group49_RC";
BA_ "ISignalName" SG_ 733 IPD_50ms_Group49_RC "IIPD_50ms_Group49_RC";
BA_ "SysSignalName" SG_ 733 IPD_50ms_Group49_RC "IPD_50ms_Group49_RC";
BA_ "CompuMethodName" SG_ 733 KeepPwrRsnIPD "KeepPwrRsnIPD";
BA_ "ISignalName" SG_ 733 KeepPwrRsnIPD "IKeepPwrRsnIPD";
BA_ "LongName" SG_ 733 KeepPwrRsnIPD "Keep Power Reason IPD";
BA_ "SysSignalName" SG_ 733 KeepPwrRsnIPD "KeepPwrRsnIPD";
BA_ "CompuMethodName" SG_ 733 IPD_50ms_Group49_Reserved1 "IPD_50ms_Group49_Reserved1";
BA_ "GenSigStartValue" SG_ 733 IPD_50ms_Group49_Reserved1 31;
BA_ "ISignalName" SG_ 733 IPD_50ms_Group49_Reserved1 "IIPD_50ms_Group49_Reserved1";
BA_ "SysSignalName" SG_ 733 IPD_50ms_Group49_Reserved1 "IPD_50ms_Group49_Reserved1";
BA_ "CompuMethodName" SG_ 733 SysPwrMdCtrl "SysPwrMdCtrl";
BA_ "ISignalName" SG_ 733 SysPwrMdCtrl "ISysPwrMdCtrl";
BA_ "LongName" SG_ 733 SysPwrMdCtrl "System power mode control";
BA_ "SysSignalName" SG_ 733 SysPwrMdCtrl "SysPwrMdCtrl";
BA_ "CompuMethodName" SG_ 733 APAEnRunReq "APAEnRunReq";
BA_ "ISignalName" SG_ 733 APAEnRunReq "IAPAEnRunReq";
BA_ "LongName" SG_ 733 APAEnRunReq "Advanced Park Assist Engine Run Request";
BA_ "SysSignalName" SG_ 733 APAEnRunReq "APAEnRunReq";
BA_ "CompuMethodName" SG_ 733 IPD_50ms_Group49_Reserved2 "IPD_50ms_Group49_Reserved2";
BA_ "GenSigStartValue" SG_ 733 IPD_50ms_Group49_Reserved2 127;
BA_ "ISignalName" SG_ 733 IPD_50ms_Group49_Reserved2 "IIPD_50ms_Group49_Reserved2";
BA_ "SysSignalName" SG_ 733 IPD_50ms_Group49_Reserved2 "IPD_50ms_Group49_Reserved2";
BA_ "CompuMethodName" SG_ 733 IPD_50ms_Group49_Reserved3 "IPD_50ms_Group49_Reserved3";
BA_ "GenSigStartValue" SG_ 733 IPD_50ms_Group49_Reserved3 255;
BA_ "ISignalName" SG_ 733 IPD_50ms_Group49_Reserved3 "IIPD_50ms_Group49_Reserved3";
BA_ "SysSignalName" SG_ 733 IPD_50ms_Group49_Reserved3 "IPD_50ms_Group49_Reserved3";
BA_ "CompuMethodName" SG_ 733 IPD_50ms_Group49_Reserved4 "IPD_50ms_Group49_Reserved4";
BA_ "GenSigStartValue" SG_ 733 IPD_50ms_Group49_Reserved4 15;
BA_ "ISignalName" SG_ 733 IPD_50ms_Group49_Reserved4 "IIPD_50ms_Group49_Reserved4";
BA_ "SysSignalName" SG_ 733 IPD_50ms_Group49_Reserved4 "IPD_50ms_Group49_Reserved4";
BA_ "CompuMethodName" SG_ 733 LADSAFnInd "LADSAFnInd";
BA_ "ISignalName" SG_ 733 LADSAFnInd "ILADSAFnInd";
BA_ "LongName" SG_ 733 LADSAFnInd "Advanced Park Assist Active Function Indication";
BA_ "SysSignalName" SG_ 733 LADSAFnInd "LADSAFnInd";
BA_ "CompuMethodName" SG_ 733 IPD_50ms_Group49_Reserved5 "IPD_50ms_Group49_Reserved5";
BA_ "GenSigStartValue" SG_ 733 IPD_50ms_Group49_Reserved5 255;
BA_ "ISignalName" SG_ 733 IPD_50ms_Group49_Reserved5 "IIPD_50ms_Group49_Reserved5";
BA_ "SysSignalName" SG_ 733 IPD_50ms_Group49_Reserved5 "IPD_50ms_Group49_Reserved5";
BA_ "CompuMethodName" SG_ 733 IPD_50ms_Group49_Reserved6 "IPD_50ms_Group49_Reserved6";
BA_ "GenSigStartValue" SG_ 733 IPD_50ms_Group49_Reserved6 255;
BA_ "ISignalName" SG_ 733 IPD_50ms_Group49_Reserved6 "IIPD_50ms_Group49_Reserved6";
BA_ "SysSignalName" SG_ 733 IPD_50ms_Group49_Reserved6 "IPD_50ms_Group49_Reserved6";
BA_ "CompuMethodName" SG_ 1143 SyncMsgType "SyncMsgType";
BA_ "ISignalName" SG_ 1143 SyncMsgType "ISyncMsgType";
BA_ "LongName" SG_ 1143 SyncMsgType "IPD_SYNC_Type";
BA_ "SysSignalName" SG_ 1143 SyncMsgType "SyncMsgType";
BA_ "CompuMethodName" SG_ 1143 SyncMsgCheckSum "SyncMsgCheckSum";
BA_ "ISignalName" SG_ 1143 SyncMsgCheckSum "ISyncMsgCheckSum";
BA_ "LongName" SG_ 1143 SyncMsgCheckSum "IPD_SYNC_CRC";
BA_ "SysSignalName" SG_ 1143 SyncMsgCheckSum "SyncMsgCheckSum";
BA_ "CompuMethodName" SG_ 1143 SyncMsgSequenceCounter "SyncMsgSequenceCounter";
BA_ "ISignalName" SG_ 1143 SyncMsgSequenceCounter "ISyncMsgSequenceCounter";
BA_ "LongName" SG_ 1143 SyncMsgSequenceCounter "IPD_SYNC_SequenceCnt";
BA_ "SysSignalName" SG_ 1143 SyncMsgSequenceCounter "SyncMsgSequenceCounter";
BA_ "CompuMethodName" SG_ 1143 SyncMsgTimeDomain "SyncMsgTimeDomain";
BA_ "GenSigStartValue" SG_ 1143 SyncMsgTimeDomain 1;
BA_ "ISignalName" SG_ 1143 SyncMsgTimeDomain "ISyncMsgTimeDomain";
BA_ "LongName" SG_ 1143 SyncMsgTimeDomain "IPD_SYNC_TimeDomain";
BA_ "SysSignalName" SG_ 1143 SyncMsgTimeDomain "SyncMsgTimeDomain";
BA_ "CompuMethodName" SG_ 1143 SyncMsgOVS "SyncMsgOVS";
BA_ "ISignalName" SG_ 1143 SyncMsgOVS "ISyncMsgOVS";
BA_ "LongName" SG_ 1143 SyncMsgOVS "IPD_SYNC_OVS";
BA_ "SysSignalName" SG_ 1143 SyncMsgOVS "SyncMsgOVS";
BA_ "CompuMethodName" SG_ 1143 SyncMsgSGW "SyncMsgSGW";
BA_ "ISignalName" SG_ 1143 SyncMsgSGW "ISyncMsgSGW";
BA_ "LongName" SG_ 1143 SyncMsgSGW "IPD_SYNC_SGW";
BA_ "SysSignalName" SG_ 1143 SyncMsgSGW "SyncMsgSGW";
BA_ "CompuMethodName" SG_ 1143 SyncMsgreserved "SyncMsgreserved";
BA_ "ISignalName" SG_ 1143 SyncMsgreserved "ISyncMsgreserved";
BA_ "LongName" SG_ 1143 SyncMsgreserved "IPD_SYNC_reserved";
BA_ "SysSignalName" SG_ 1143 SyncMsgreserved "SyncMsgreserved";
BA_ "CompuMethodName" SG_ 1143 SyncMsgTime "SyncMsgTime";
BA_ "ISignalName" SG_ 1143 SyncMsgTime "ISyncMsgTime";
BA_ "LongName" SG_ 1143 SyncMsgTime "IPD_SYNC_SyncTime";
BA_ "SysSignalName" SG_ 1143 SyncMsgTime "SyncMsgTime";
BA_ "CompuMethodName" SG_ 1399 IPDIdentityResp "IPDIdentityResp";
BA_ "ISignalName" SG_ 1399 IPDIdentityResp "IIPDIdentityResp";
BA_ "LongName" SG_ 1399 IPDIdentityResp "IPD Identification Response";
BA_ "SysSignalName" SG_ 1399 IPDIdentityResp "IPDIdentityResp";
BA_ "CompuMethodName" SG_ 1526 IPDComKeyEnbResp "IPDComKeyEnbResp";
BA_ "ISignalName" SG_ 1526 IPDComKeyEnbResp "IIPDComKeyEnbResp";
BA_ "LongName" SG_ 1526 IPDComKeyEnbResp "IPD Communication Key Enable Response";
BA_ "SysSignalName" SG_ 1526 IPDComKeyEnbResp "IPDComKeyEnbResp";
BA_ "CompuMethodName" SG_ 1526 AIParkngRespICB "AIParkngRespICB";
BA_ "ISignalName" SG_ 1526 AIParkngRespICB "IAIParkngRespICB";
BA_ "LongName" SG_ 1526 AIParkngRespICB "AIParking Function Response";
BA_ "SysSignalName" SG_ 1526 AIParkngRespICB "AIParkngRespICB";
VAL_ 712 NrwroadFwdBtnDsp 0 "NrwroadFwdBtnDsp_0_unavailable" 1 "NrwroadFwdBtnDsp_1_passive" 2 "NrwroadFwdBtnDsp_2_postive" 3 "NrwroadFwdBtnDsp_3_Reserved";
VAL_ 712 NrwroadFwdDsp 0 "NrwroadFwdDsp_0_Reserved0" 1 "NrwroadFwdDsp_1_Reserved1" 2 "NrwroadFwdDsp_2_Reserved2" 3 "NrwroadFwdDsp_3_Reserved3" 4 "NrwroadFwdDsp_4_Reserved4" 5 "NrwroadFwdDsp_5_Reserved5" 6 "NrwroadFwdDsp_6_Reserved6" 7 "NrwroadFwdDsp_7_Reserved7" 8 "NrwroadFwdDsp_8_Reserved8" 9 "NrwroadFwdDsp_9_Reserved9" 10 "NrwroadFwdDsp_10_Reserved10" 11 "NrwroadFwdDsp_11_Reserved11" 12 "NrwroadFwdDsp_12_Reserved12" 13 "NrwroadFwdDsp_13_Reserved13" 14 "NrwroadFwdDsp_14_Reserved14" 15 "NrwroadFwdDsp_15_Reserved15" 16 "NrwroadFwdDsp_16_Reserved16" 17 "NrwroadFwdDsp_17_Reserved17" 18 "NrwroadFwdDsp_18_Reserved18" 19 "NrwroadFwdDsp_19_Reserved19" 20 "NrwroadFwdDsp_20_Reserved20" 21 "NrwroadFwdDsp_21_Reserved21" 22 "NrwroadFwdDsp_22_Reserved22" 23 "NrwroadFwdDsp_23_Reserved23" 24 "NrwroadFwdDsp_24_Reserved24" 25 "NrwroadFwdDsp_25_Reserved25" 26 "NrwroadFwdDsp_26_Reserved26" 27 "NrwroadFwdDsp_27_Reserved27" 28 "NrwroadFwdDsp_28_Reserved28" 29 "NrwroadFwdDsp_29_Reserved29" 30 "NrwroadFwdDsp_30_Reserved30" 31 "NrwroadFwdDsp_31_Reserved31";
VAL_ 712 NrwroadFwdCndNotSt 0 "NrwroadFwdCndNotSt_0_Reserved0" 1 "NrwroadFwdCndNotSt_1_Reserved1" 2 "NrwroadFwdCndNotSt_2_Reserved2" 3 "NrwroadFwdCndNotSt_3_Reserved3" 4 "NrwroadFwdCndNotSt_4_Reserved4" 5 "NrwroadFwdCndNotSt_5_Reserved5" 6 "NrwroadFwdCndNotSt_6_Reserved6" 7 "NrwroadFwdCndNotSt_7_Reserved7" 8 "NrwroadFwdCndNotSt_8_Reserved8" 9 "NrwroadFwdCndNotSt_9_Reserved9" 10 "NrwroadFwdCndNotSt_10_Reserved10" 11 "NrwroadFwdCndNotSt_11_Reserved11" 12 "NrwroadFwdCndNotSt_12_Reserved12" 13 "NrwroadFwdCndNotSt_13_Reserved13" 14 "NrwroadFwdCndNotSt_14_Reserved14" 15 "NrwroadFwdCndNotSt_15_Reserved15" 16 "NrwroadFwdCndNotSt_16_Reserved16" 17 "NrwroadFwdCndNotSt_17_Reserved17" 18 "NrwroadFwdCndNotSt_18_Reserved18" 19 "NrwroadFwdCndNotSt_19_Reserved19" 20 "NrwroadFwdCndNotSt_20_Reserved20" 21 "NrwroadFwdCndNotSt_21_Reserved21" 22 "NrwroadFwdCndNotSt_22_Reserved22" 23 "NrwroadFwdCndNotSt_23_Reserved23" 24 "NrwroadFwdCndNotSt_24_Reserved24" 25 "NrwroadFwdCndNotSt_25_Reserved25" 26 "NrwroadFwdCndNotSt_26_Reserved26" 27 "NrwroadFwdCndNotSt_27_Reserved27" 28 "NrwroadFwdCndNotSt_28_Reserved28" 29 "NrwroadFwdCndNotSt_29_Reserved29" 30 "NrwroadFwdCndNotSt_30_Reserved30" 31 "NrwroadFwdCndNotSt_31_Reserved31";
VAL_ 712 NrwroadFwdDstTostDsp 0 "NrwroadFwdDstTostDsp_0_Unavialable" 1 "NrwroadFwdDstTostDsp_1_RecommendedRelease" 2 "NrwroadFwdDstTostDsp_2_StartRelease" 3 "NrwroadFwdDstTostDsp_3_SuspendRelease" 4 "NrwroadFwdDstTostDsp_4_ResumeRelease" 5 "NrwroadFwdDstTostDsp_5_QuitRelease" 6 "NrwroadFwdDstTostDsp_6_Reserved6" 7 "NrwroadFwdDstTostDsp_7_Reserved7" 8 "NrwroadFwdDstTostDsp_8_Reserved8" 9 "NrwroadFwdDstTostDsp_9_Reserved9" 10 "NrwroadFwdDstTostDsp_10_Reserved10" 11 "NrwroadFwdDstTostDsp_11_Reserved11" 12 "NrwroadFwdDstTostDsp_12_Reserved12" 13 "NrwroadFwdDstTostDsp_13_Reserved13" 14 "NrwroadFwdDstTostDsp_14_Reserved14" 15 "NrwroadFwdDstTostDsp_15_Reserved15";
VAL_ 712 NrwroadFwdSwSts 0 "NrwroadFwdSwSts_0_Unavaliable" 1 "NrwroadFwdSwSts_1_Off" 2 "NrwroadFwdSwSts_2_On" 3 "NrwroadFwdSwSts_3_Reserve";
VAL_ 712 NrwroadFwdDst360Req 0 "NrwroadFwdDst360Req_0_NoRequest" 1 "NrwroadFwdDst360Req_1_Request" 2 "NrwroadFwdDst360Req_2_Quit" 3 "NrwroadFwdDst360Req_3_Hold" 4 "NrwroadFwdDst360Req_4_Reserved4" 5 "NrwroadFwdDst360Req_5_Reserved5" 6 "NrwroadFwdDst360Req_6_Reserved6" 7 "NrwroadFwdDst360Req_7_Reserved7";
VAL_ 712 NrwroadFwdDstBtnDsp 0 "NrwroadFwdDstBtndsp_0_Unavialable" 1 "NrwroadFwdDstBtndsp_1_Highlight" 2 "NrwroadFwdDstBtndsp_2_Flashing" 3 "NrwroadFwdDstBtndsp_3_Hide" 4 "NrwroadFwdDstBtndsp_4_Reserved4" 5 "NrwroadFwdDstBtndsp_5_Reserved5" 6 "NrwroadFwdDstBtndsp_6_Reserved6" 7 "NrwroadFwdDstBtndsp_7_Reserved7";
VAL_ 710 SpedRegulaModSwSts 0 "SpedRegulaModSwSts_0_unavaliable" 1 "SpedRegulaModSwSts_1_switch_on" 2 "SpedRegulaModSwSts_2_switch_off" 3 "SpedRegulaModSwSts_3_switch_hide" 4 "SpedRegulaModSwSts_4_Reserved" 5 "SpedRegulaModSwSts_5_Reserved" 6 "SpedRegulaModSwSts_6_Reserved" 7 "SpedRegulaModSwSts_7_Reserved";
VAL_ 710 RADSSwSts 0 "RADSSwSts_0_Unavaliable" 1 "RADSSwSts_1_Off" 2 "RADSSwSts_2_On" 3 "RADSSwSts_3_Reserve";
VAL_ 706 PDSysKeyPsAvlbl 0 "PDSysKeyPsAvlbl_0_Invalid" 1 "PDSysKeyPsAvlbl_1_Valid";
VAL_ 807 TSRTrgtWarnSign 0 "TSRTrgtWarnSign_0_NoSign" 1 "TSRTrgtWarnSign_1_Dangerous_road_by_mountain_Right" 2 "TSRTrgtWarnSign_2_Dangerous_road_by_mountain_Left" 3 "TSRTrgtWarnSign_3_Town" 4 "TSRTrgtWarnSign_4_Dike_Road_Right" 5 "TSRTrgtWarnSign_5_Dike_Road_Left" 6 "TSRTrgtWarnSign_6_T_Crossover" 7 "TSRTrgtWarnSign_7_Ferry" 8 "TSRTrgtWarnSign_8_Narrowing" 9 "TSRTrgtWarnSign_9_Falling_Rocks_Left" 10 "TSRTrgtWarnSign_10_ReverseCurveL" 11 "TSRTrgtWarnSign_11_ReverseCurveR" 12 "TSRTrgtWarnSign_12_Waterway" 13 "TSRTrgtWarnSign_13_Crossroad" 14 "TSRTrgtWarnSign_14_Intersection" 15 "TSRTrgtWarnSign_15_Y_Crossing_LR" 16 "TSRTrgtWarnSign_16_Y_Crossing_RR" 17 "TSRTrgtWarnSign_17_Y_Crossing_LF" 18 "TSRTrgtWarnSign_18_Narrowing_Left" 19 "TSRTrgtWarnSign_19_Y_Crossing_RF" 20 "TSRTrgtWarnSign_20_T_Intersection" 21 "TSRTrgtWarnSign_21_T_Intersection_Left" 22 "TSRTrgtWarnSign_22_T_Intersection_Right" 23 "TSRTrgtWarnSign_23_Roundabout" 24 "TSRTrgtWarnSign_24_ContinuousBend" 25 "TSRTrgtWarnSign_25_ContinuousDownhill" 26 "TSRTrgtWarnSign_26_Uneven" 27 "TSRTrgtWarnSign_27_Rain" 28 "TSRTrgtWarnSign_28_Low_lying_Road" 29 "TSRTrgtWarnSign_29_Convex_Road" 30 "TSRTrgtWarnSign_30_Slow" 31 "TSRTrgtWarnSign_31_Uphill" 32 "TSRTrgtWarnSign_32_WarnWorks" 33 "TSRTrgtWarnSign_33_Cross_Plane" 34 "TSRTrgtWarnSign_34_AccidentProneSection" 35 "TSRTrgtWarnSign_35_Two_way_traffic" 36 "TSRTrgtWarnSign_36_WarnWildanimal" 37 "TSRTrgtWarnSign_37_Tunnel" 38 "TSRTrgtWarnSign_38_lightingIntoTunnel" 39 "TSRTrgtWarnSign_39_Arched_bridge" 40 "TSRTrgtWarnSign_40_Unguarded_railway_crossing" 41 "TSRTrgtWarnSign_41_Downhill" 42 "TSRTrgtWarnSign_42_SharpTurnR" 43 "TSRTrgtWarnSign_43_SharpTurnL" 44 "TSRTrgtWarnSign_44_Easy_slide" 45 "TSRTrgtWarnSign_45_Traffic_Light" 46 "TSRTrgtWarnSign_46_Guarded_railway_crossing" 47 "TSRTrgtWarnSign_47_Narrowing_Right" 48 "TSRTrgtWarnSign_48_Passfromright" 49 "TSRTrgtWarnSign_49_Narrow_bridge" 50 "TSRTrgtWarnSign_50_Maintaindistance" 51 "TSRTrgtWarnSign_51_ThunderStorm" 52 "TSRTrgtWarnSign_52_Warn_handicapped" 53 "TSRTrgtWarnSign_53_Tidal_driveway" 54 "TSRTrgtWarnSign_54_Fog" 55 "TSRTrgtWarnSign_55_WarnKids" 56 "TSRTrgtWarnSign_56_WarnBike" 57 "TSRTrgtWarnSign_57_WarnPed" 58 "TSRTrgtWarnSign_58_ConfluenceL" 59 "TSRTrgtWarnSign_59_ConfluenceR" 60 "TSRTrgtWarnSign_60_WarnCrosswind" 61 "TSRTrgtWarnSign_61_Snow" 62 "TSRTrgtWarnSign_62_Falling_Rocks_Right" 63 "TSRTrgtWarnSign_63_WarnRisk" 64 "TSRTrgtWarnSign_64_WarnCattle" 65 "TSRTrgtWarnSign_65_Passfromleft" 66 "TSRTrgtWarnSign_66_Passfromleftright" 67 "TSRTrgtWarnSign_67_Warnqueue" 68 "TSRTrgtWarnSign_68_SpeedHump" 69 "TSRTrgtWarnSign_69_AccidentManagement" 70 "TSRTrgtWarnSign_70_IcyRoad";
VAL_ 807 TSRTrgtBanSign 0 "TSRTrgtBanSign_0_NoSign" 1 "TSRTrgtBanSign_1_NoOvertake" 2 "TSRTrgtBanSign_2_NoAnimalPowerVehicle" 3 "TSRTrgtBanSign_3_NoBus" 4 "TSRTrgtBanSign_4_NoElectricTricycle" 5 "TSRTrgtBanSign_5_NoTurnaround" 6 "TSRTrgtBanSign_6_NoBicycle" 7 "TSRTrgtBanSign_7_NoTruckLeft" 8 "TSRTrgtBanSign_8_NoTrailer" 9 "TSRTrgtBanSign_9_NoWalkers" 10 "TSRTrgtBanSign_10_NoCar" 11 "TSRTrgtBanSign_11_NoWhistle" 12 "TSRTrgtBanSign_12_NoMotorcycle" 13 "TSRTrgtBanSign_13_NoObjectshown" 14 "TSRTrgtBanSign_14_NoStraight" 15 "TSRTrgtBanSign_15_NoRickshaw" 16 "TSRTrgtBanSign_16_NoHumanpoweredtrucks" 17 "TSRTrgtBanSign_17_NoHumanpoweredtricycles" 18 "TSRTrgtBanSign_18_NoTractor" 19 "TSRTrgtBanSign_19_NoRightTurn" 20 "TSRTrgtBanSign_20_NoLeftRightTurn" 21 "TSRTrgtBanSign_21_NoStraightRightTurn" 22 "TSRTrgtBanSign_22_NolowSpeedtruck" 23 "TSRTrgtBanSign_23_NoLeftTurn" 24 "TSRTrgtBanSign_24_NoCarTurnRight" 25 "TSRTrgtBanSign_25_NoCar" 26 "TSRTrgtBanSign_26_NoTruck" 27 "TSRTrgtBanSign_27_NoDangerousgoodvehicle" 28 "TSRTrgtBanSign_28_NoStraightLeftTurn" 29 "TSRTrgtBanSign_29_Quality_Limit" 30 "TSRTrgtBanSign_30_Axle_load_Limit" 31 "TSRTrgtBanSign_31_Custom" 32 "TSRTrgtBanSign_32_Check" 33 "TSRTrgtBanSign_33_NoParking" 34 "TSRTrgtBanSign_34_NoLongParking" 35 "TSRTrgtBanSign_35_Higth_limit_350cm" 36 "TSRTrgtBanSign_36_Width_limit_300cm" 37 "TSRTrgtBanSign_37_StopGiveWay" 38 "TSRTrgtBanSign_38_GiveWay" 39 "TSRTrgtBanSign_38_NoPass" 40 "TSRTrgtBanSign_40_OncomingGiveWay" 41 "TSRTrgtBanSign_41_NoEntry" 42 "TSRTrgtBanSign_42_RelieveNoOvertake";
VAL_ 807 TSRSwReqResp 0 "TSRSwReqResp_0_Unavailable" 1 "TSRSwReqResp_1_Off" 2 "TSRSwReqResp_2_On";
VAL_ 807 SLIFSts_IPD 0 "SLIFSts_IPD_0_Off" 1 "SLIFSts_IPD_1_Active" 2 "SLIFSts_IPD_2_Overspeed" 3 "SLIFSts_IPD_3_Standby" 4 "SLIFSts_IPD_4_Fault";
VAL_ 807 TSRSts 0 "TSRSts_0_Off" 1 "TSRSts_1_Active" 3 "TSRSts_3_Standby" 4 "TSRSts_4_Fault";
VAL_ 807 PilotSysAVCamrF1FltSts 0 "PilotSysAVCamrF1FltSts_0_NoError" 1 "PilotSysAVCamrF1FltSts_1_BlockError" 2 "PilotSysAVCamrF1FltSts_2_SystemTemporaryUnvailable" 3 "PilotSysAVCamrF1FltSts_3_ServiceRequired" 4 "PilotSysAVCamrF1FltSts_4_Reserved";
VAL_ 807 PilotSysADASFltSts 0 "PilotSysADASFltSts_0_NoError" 1 "PilotSysADASFltSts_1_TemporaryError" 2 "PilotSysADASFltSts_2_PermanentError" 3 "PilotSysADASFltSts_3_SensorBlockError" 4 "PilotSysADASFltSts_4_SensorTemporaryError" 5 "PilotSysADASFltSts_5_SensorPermanentError" 6 "PilotSysADASFltSts_6_Reserved" 7 "PilotSysADASFltSts_7_Reserved";
VAL_ 807 AIParkngSSPLotSwSts 0 "AIParkngSSPLotSwSts_0_no_reqest" 1 "AIParkngSSPLotSwSts_1_Off" 2 "AIParkngSSPLotSwSts_2_On";
VAL_ 807 PilotSysAVCamrRFltSts 0 "PilotSysAVCamrRFltSts_0_NoError" 1 "PilotSysAVCamrRFltSts_1_BlockError" 2 "PilotSysAVCamrRFltSts_2_SystemTemporaryUnvailable" 3 "PilotSysAVCamrRFltSts_3_ServiceRequired" 4 "PilotSysAVCamrRFltSts_4_Reserved";
VAL_ 807 PilotSysAVCamrF3FltSts 0 "PilotSysAVCamrF3FltSts_0_NoError" 1 "PilotSysAVCamrF3FltSts_1_BlockError" 2 "PilotSysAVCamrF3FltSts_2_SystemTemporaryUnvailable" 3 "PilotSysAVCamrF3FltSts_3_ServiceRequired" 4 "PilotSysAVCamrF3FltSts_4_Reserved";
VAL_ 807 PilotSysAVCamrFRSFltSts 0 "PilotSysAVCamrFRSFltSts_0_NoError" 1 "PilotSysAVCamrFRSFltSts_1_BlockError" 2 "PilotSysAVCamrFRSFltSts_2_SystemTemporaryUnvailable" 3 "PilotSysAVCamrFRSFltSts_3_ServiceRequired" 4 "PilotSysAVCamrFRSFltSts_4_Reserved";
VAL_ 807 PilotSysAVCamrFLSFltSts 0 "PilotSysAVCamrFLSFltSts_0_NoError" 1 "PilotSysAVCamrFLSFltSts_1_BlockError" 2 "PilotSysAVCamrFLSFltSts_2_SystemTemporaryUnvailable" 3 "PilotSysAVCamrFLSFltSts_3_ServiceRequired" 4 "PilotSysAVCamrFLSFltSts_4_Reserved";
VAL_ 807 PilotSysAVCamrRRSFltSts 0 "PilotSysAVCamrRRSFltSts_0_NoError" 1 "PilotSysAVCamrRRSFltSts_1_BlockError" 2 "PilotSysAVCamrRRSFltSts_2_SystemTemporaryUnvailable" 3 "PilotSysAVCamrRRSFltSts_3_ServiceRequired" 4 "PilotSysAVCamrRRSFltSts_4_Reserved";
VAL_ 807 PilotSysAVCamrRLSFltSts 0 "PilotSysAVCamrRLSFltSts_0_NoError" 1 "PilotSysAVCamrRLSFltSts_1_BlockError" 2 "PilotSysAVCamrRLSFltSts_2_SystemTemporaryUnvailable" 3 "PilotSysAVCamrRLSFltSts_3_ServiceRequired" 4 "PilotSysAVCamrRLSFltSts_4_Reserved";
VAL_ 807 PilotSysHDAVMCamrRFltSts 0 "PilotSysHDAVMCamrRFltSts_0_NoError" 1 "PilotSysHDAVMCamrRFltSts_1_BlockError" 2 "PilotSysHDAVMCamrRFltSts_2_SystemTemporaryUnvailable" 3 "PilotSysHDAVMCamrRFltSts_3_ServiceRequired" 4 "PilotSysHDAVMCamrRFltSts_4_Reserved";
VAL_ 807 PilotSysHDAVMCamrFFltSts 0 "PilotSysHDAVMCamrFFltSts_0_NoError" 1 "PilotSysHDAVMCamrFFltSts_1_BlockError" 2 "PilotSysHDAVMCamrFFltSts_2_SystemTemporaryUnvailable" 3 "PilotSysHDAVMCamrFFltSts_3_ServiceRequired" 4 "PilotSysHDAVMCamrFFltSts_4_Reserved";
VAL_ 807 PilotSysHDAVMCamrRHFltSts 0 "PilotSysHDAVMCamrRHFltSts_0_NoError" 1 "PilotSysHDAVMCamrRHFltSts_1_BlockError" 2 "PilotSysHDAVMCamrRHFltSts_2_SystemTemporaryUnvailable" 3 "PilotSysHDAVMCamrRHFltSts_3_ServiceRequired" 4 "PilotSysHDAVMCamrRHFltSts_4_Reserved";
VAL_ 807 PilotSysHDAVMCamrLHFltSts 0 "PilotSysHDAVMCamrLHFltSts_0_NoError" 1 "PilotSysHDAVMCamrLHFltSts_1_BlockError" 2 "PilotSysHDAVMCamrLHFltSts_2_SystemTemporaryUnvailable" 3 "PilotSysHDAVMCamrLHFltSts_3_ServiceRequired" 4 "PilotSysHDAVMCamrLHFltSts_4_Reserved";
VAL_ 807 SLIFWrnngMdResp 0 "SLIFWrnngMdResp_0__Unavailable" 1 "SLIFWrnngMdResp_1__Off" 2 "SLIFWrnngMdResp_2__Visual" 3 "SLIFWrnngMdResp_3___Audible";
VAL_ 807 PilotSysLFSDAFltSts 0 "PilotSysLFSDAFltSts_0_NoError" 1 "PilotSysLFSDAFltSts_1_BlockError" 2 "PilotSysLFSDAFltSts_2_SystemTemporaryUnvailable" 3 "PilotSysLFSDAFltSts_3_ServiceRequired" 4 "PilotSysLFSDAFltSts_4_Reserved";
VAL_ 807 PilotSysFDRFltSts 0 "PilotSysFDRFltSts_0_NoError" 1 "PilotSysFDRFltSts_1_BlockError" 2 "PilotSysFDRFltSts_2_SystemTemporaryUnvailable" 3 "PilotSysFDRFltSts_3_ServiceRequired" 4 "PilotSysFDRFltSts_4_Reserved";
VAL_ 807 TrgtSpdSrcSts_IPD 0 "TrgtSpdSrcSts_IPD_0_Undefined" 1 "TrgtSpdSrcSts_IPD_1_Camera" 2 "TrgtSpdSrcSts_IPD_2_Navigation" 3 "TrgtSpdSrcSts_IPD_3_Fault";
VAL_ 807 PilotSysLHRDAFltSts 0 "PilotSysLHRDAFltSts_0_NoError" 1 "PilotSysLHRDAFltSts_1_BlockError" 2 "PilotSysLHRDAFltSts_2_SystemTemporaryUnvailable" 3 "PilotSysLHRDAFltSts_3_ServiceRequired" 4 "PilotSysLHRDAFltSts_4_Reserved";
VAL_ 807 PilotSysRFSDAFltSts 0 "PilotSysRFSDAFltSts_0_NoError" 1 "PilotSysRFSDAFltSts_1_BlockError" 2 "PilotSysRFSDAFltSts_2_SystemTemporaryUnvailable" 3 "PilotSysRFSDAFltSts_3_ServiceRequired" 4 "PilotSysRFSDAFltSts_4_Reserved";
VAL_ 807 SLIFAudWrnng_IPD 0 "SLIFAudWrnng_IPD_0__False" 1 "SLIFAudWrnng_IPD_1__True";
VAL_ 807 SLIFUpdtInd_IPD 0 "SLIFUpdtInd_IPD_0__False" 1 "SLIFUpdtInd_IPD_1__True";
VAL_ 807 PilotSysFLIDARFltSts 0 "PilotSysFLIDARFltSts_0_NoError" 1 "PilotSysFLIDARFltSts_1_BlockError" 2 "PilotSysFLIDARFltSts_2_SystemTemporaryUnvailable" 3 "PilotSysFLIDARFltSts_3_ServiceRequired" 4 "PilotSysFLIDARFltSts_4_Reserved";
VAL_ 807 PilotSysRHRDAFltSts 0 "PilotSysRHRDAFltSts_0_NoError" 1 "PilotSysRHRDAFltSts_1_BlockError" 2 "PilotSysRHRDAFltSts_2_SystemTemporaryUnvailable" 3 "PilotSysRHRDAFltSts_3_ServiceRequired" 4 "PilotSysRHRDAFltSts_4_Reserved";
VAL_ 807 PilotSysUSSFltSts 0 "PilotSysUSSFltSts_0_NoError" 1 "PilotSysUSSFltSts_1_BlockError" 2 "PilotSysUSSFltSts_2_SystemTemporaryUnvailable" 3 "PilotSysUSSFltSts_3_ServiceRequired" 4 "PilotSysUSSFltSts_4_Reserved";
VAL_ 807 HORWarningEvtSts 0 "HORWarningEvtSts_0_default" 1 "HORWarningEvtSts_1_HORForbiddenPilot";
VAL_ 807 EORWarningEvtSts 0 "EORWarningEvtSts_0_default" 1 "EORWarningEvtSts_1_EORForbiddenPilot";
VAL_ 807 PosALCFailed 0 "PosALCFailed_0_default" 1 "PosALCFailed_1_PositiveALCFailed";
VAL_ 807 SLIFSysFltSts 0 "SLIFSysFltSts_0_NoError" 1 "SLIFSysFltSts_1_PerformanceDegradation" 2 "SLIFSysFltSts_2_SystemTemporaryUnavailable" 3 "SLIFSysFltSts_3_ServiceRequired";
VAL_ 807 ADS_ISAMsgReq 0 "ADS_ISAMsgReq_0_Nowarning" 1 "ADS_ISAMsgReq_1_MSG1" 2 "ADS_ISAMsgReq_2_MSG2" 3 "ADS_ISAMsgReq_3_MSG3" 4 "ADS_ISAMsgReq_4_MSG4" 5 "ADS_ISAMsgReq_5_MSG5" 6 "ADS_ISAMsgReq_6_MSG6" 7 "ADS_ISAMsgReq_7_MSG7" 8 "ADS_ISAMsgReq_8_MSG8" 9 "ADS_ISAMsgReq_9_MSG9";
VAL_ 807 SLIFUpdtIndResp_IPD 0 "SLIFUpdtIndResp_IPD_0_Unavailable" 1 "SLIFUpdtIndResp_IPD_1_Off" 2 "SLIFUpdtIndResp_IPD_2_On" 3 "SLIFUpdtIndResp_IPD_3_reserve";
VAL_ 807 ADS_ISASysFltSts 0 "ADS_ISASysFltSts_0_NoError" 1 "ADS_ISASysFltSts_1_PerformanceDegradation" 2 "ADS_ISASysFltSts_2_SystemTemporaryUnavailable" 3 "ADS_ISASysFltSts_3_ServiceRequired";
VAL_ 807 ADS_ISASysSts 0 "ADS_ISASysSts_0_Off" 1 "ADS_ISASysSts_1_Passive" 2 "ADS_ISASysSts_2_Active" 3 "ADS_ISASysSts_3_Overspeed" 4 "ADS_ISASysSts_4_Standby" 5 "ADS_ISASysSts_5_Fault" 6 "ADS_ISASysSts_6_reserve" 7 "ADS_ISASysSts_7_reserve";
VAL_ 807 ParkngSpdSwResp 0 "ParkngSpdSwResp_0_Default" 1 "ParkngSpdSwResp_1_LowSpeed" 2 "ParkngSpdSwResp_2_MiddleSpeed" 3 "ParkngSpdSwResp_3_HighSpeed";
VAL_ 765 FrtCamrHeatCtrl 0 "FrtCamrHeatCtrl_0_no_request" 1 "FrtCamrHeatCtrl_1_request";
VAL_ 844 IACCPreSpdLimtCmd 0 "IACCPreSpdLimtCmd_0_Unavallable" 1 "IACCPreSpdLimtCmd_1_Off" 2 "IACCPreSpdLimtCmd_2_On" 3 "IACCPreSpdLimtCmd_3_Reserve";
VAL_ 844 IACCPreMsgReq 0 "IACCPreMsgReq_0_NoDisplay" 1 "IACCPreMsgReq_1_Roundabout" 2 "IACCPreMsgReq_2_Trafficlight" 3 "IACCPreMsgReq_3_Intersection" 4 "IACCPreMsgReq_4_Curve" 5 "IACCPreMsgReq_5_StopSign" 6 "IACCPreMsgReq_6_Tollstation" 7 "IACCPreMsgReq_7_OvtakingSuppress" 8 "IACCPreMsgReq_8_SpeedLimit" 9 "IACCPreMsgReq_9_Reserve" 10 "IACCPreMsgReq_10_Reserve" 11 "IACCPreMsgReq_11_Reserve" 12 "IACCPreMsgReq_12_Reserve" 13 "IACCPreMsgReq_13_Reserve" 14 "IACCPreMsgReq_14_Reserve" 15 "IACCPreMsgReq_15_Reserve";
VAL_ 844 TgtParkingFavorite 0 "TgtParkingFavorite_0_NoFavorite" 1 "TgtParkingFavorite_1_FavoriteId1" 2 "TgtParkingFavorite_2_FavoriteId2" 3 "TgtParkingFavorite_3_FavoriteId3" 4 "TgtParkingFavorite_4_FavoriteId4" 5 "TgtParkingFavorite_5_FavoriteId5" 6 "TgtParkingFavorite_6_FavoriteId6" 7 "TgtParkingFavorite_7_FavoriteId7" 8 "TgtParkingFavorite_8_FavoriteId8" 9 "TgtParkingFavorite_9_FavoriteId9" 10 "TgtParkingFavorite_10_FavoriteId10" 11 "TgtParkingFavorite_11_FavoriteId11" 12 "TgtParkingFavorite_12_FavoriteId12" 13 "TgtParkingFavorite_13_Reserved1" 14 "TgtParkingFavorite_14_Reserved2" 15 "TgtParkingFavorite_15_Reserved3";
VAL_ 844 IPDWtrClntInltFlwReq 0 "IPDWtrClntInltFlwReq_0_1_L_min" 1 "IPDWtrClntInltFlwReq_1_2_L_min" 2 "IPDWtrClntInltFlwReq_2_3_L_min" 3 "IPDWtrClntInltFlwReq_3_4_L_min" 4 "IPDWtrClntInltFlwReq_4_5_L_min" 5 "IPDWtrClntInltFlwReq_5_6_L_min" 6 "IPDWtrClntInltFlwReq_6_7_L_min" 7 "IPDWtrClntInltFlwReq_7_8_L_min" 8 "IPDWtrClntInltFlwReq_8_9_L_min" 9 "IPDWtrClntInltFlwReq_9_10_L_min" 10 "IPDWtrClntInltFlwReq_10_11_L_min" 11 "IPDWtrClntInltFlwReq_11_12_L_min" 12 "IPDWtrClntInltFlwReq_12_16_L_min" 13 "IPDWtrClntInltFlwReq_13_Reserved0" 14 "IPDWtrClntInltFlwReq_14_Reserved1" 15 "IPDWtrClntInltFlwReq_15_SysMax";
VAL_ 844 IPDAVCamrHeatReq 0 "IPDAVCamrHeatReq_0_Off" 1 "IPDAVCamrHeatReq_1_On";
VAL_ 844 IPDWtrClntInltTimeReq 0 "IPDWtrClntInltTimeReq_0_No_Request" 1 "IPDWtrClntInltTimeReq_1_Request";
VAL_ 844 SpdLmtOfstSetNumResp 0 "SpdLmtOfstSetNumResp_0_Unavailable" 1 "SpdLmtOfstSetNumResp_1_0_km_h" 2 "SpdLmtOfstSetNumResp_2_5_km_h" 3 "SpdLmtOfstSetNumResp_3_10_km_h" 4 "SpdLmtOfstSetNumResp_4_15_km_h" 5 "SpdLmtOfstSetNumResp_5_20_km_h" 6 "SpdLmtOfstSetNumResp_6__5_km_h" 7 "SpdLmtOfstSetNumResp_7__10_km_h" 8 "SpdLmtOfstSetNumResp_8__15_km_h" 9 "SpdLmtOfstSetNumResp_9__20_km_h" 10 "SpdLmtOfstSetNumResp_10_reserved" 11 "SpdLmtOfstSetNumResp_11_reserved" 12 "SpdLmtOfstSetNumResp_12_reserved" 13 "SpdLmtOfstSetNumResp_13_reserved" 14 "SpdLmtOfstSetNumResp_14_reserved";
VAL_ 844 TJAICAMsgReq 0 "TJAICAMsgReq_0_NoDisplay" 1 "TJAICAMsgReq_1_hands_on_request" 2 "TJAICAMsgReq_2_wide_lane_left" 3 "TJAICAMsgReq_3_wide_lane_right" 4 "TJAICAMsgReq_4_red_traffic_light_attention" 5 "TJAICAMsgReq_7_reserve" 6 "TJAICAMsgReq_5_override_attention" 7 "TJAICAMsgReq_6_curve_attention" 8 "TJAICAMsgReq_8_reserve" 9 "TJAICAMsgReq_9_reserve" 10 "TJAICAMsgReq_10_reserve" 11 "TJAICAMsgReq_11_reserve" 12 "TJAICAMsgReq_12_reserve" 13 "TJAICAMsgReq_13_reserve" 14 "TJAICAMsgReq_14_reserve" 15 "TJAICAMsgReq_15_reserve" 16 "TJAICAMsgReq_16_reserve" 17 "TJAICAMsgReq_17_reserve" 18 "TJAICAMsgReq_18_reserve" 19 "TJAICAMsgReq_19_reserve" 20 "TJAICAMsgReq_20_reserve" 21 "TJAICAMsgReq_21_reserve" 22 "TJAICAMsgReq_22_reserve" 23 "TJAICAMsgReq_23_reserve" 24 "TJAICAMsgReq_24_reserve" 25 "TJAICAMsgReq_25_reserve" 26 "TJAICAMsgReq_26_reserve" 27 "TJAICAMsgReq_27_reserve" 28 "TJAICAMsgReq_28_reserve" 29 "TJAICAMsgReq_29_reserve" 30 "TJAICAMsgReq_30_reserve" 31 "TJAICAMsgReq_31_reserve";
VAL_ 844 SpdLmtOfstSetPercResp 0 "SpdLmtOfstSetPercResp_0_Unavailable" 1 "SpdLmtOfstSetPercResp_1_0" 2 "SpdLmtOfstSetPercResp_2_5" 3 "SpdLmtOfstSetPercResp_3_10" 4 "SpdLmtOfstSetPercResp_4_20" 5 "SpdLmtOfstSetPercResp_5__5" 6 "SpdLmtOfstSetPercResp_6__10" 7 "SpdLmtOfstSetPercResp_7__20";
VAL_ 844 ACCStsSw 0 "ACCStsSw_0_unavailable" 1 "ACCStsSw_1_Off" 2 "ACCStsSw_2_On" 3 "ACCStsSw_3_Reserve";
VAL_ 844 ACCSpdLimtSw 0 "ACCSpdLimtSw_0_unavailable" 1 "ACCSpdLimtSw_1_manual" 2 "ACCSpdLimtSw_2_Auto" 3 "ACCSpdLimtSw_3_OFF";
VAL_ 844 SpdLimitManualSts 0 "SpdLimitManualSts_0_NoRequest" 1 "SpdLimitManualSts_1_manual" 2 "SpdLimitManualSts_2_Reserve" 3 "SpdLimitManualSts_3_Reserve";
VAL_ 844 NonDirectDMSSwDspCmd 0 "NonDirectDMSSwDspCmd_0_unavailable" 1 "NonDirectDMSSwDspCmd_1_off" 2 "NonDirectDMSSwDspCmd_2_on" 3 "NonDirectDMSSwDspCmd_3_reserved";
VAL_ 844 CCSpdlVcCmdSwReqDspCmd 0 "CCSpdlVcCmdSwReqDspCmd_0_unavailable" 1 "CCSpdlVcCmdSwReqDspCmd_1_off" 2 "CCSpdlVcCmdSwReqDspCmd_2_on" 3 "CCSpdlVcCmdSwReqDspCmd_3_reserved";
VAL_ 844 ADAudioSWSts 0 "ADAudioSWSts_0_unavailable" 1 "ADAudioSWSts_1_Off" 2 "ADAudioSWSts_2_Concise" 3 "ADAudioSWSts_3_Standard";
VAL_ 844 SpdLmtMdMsgReq 0 "SpdLmtMdMsgReq_0_NoDisplay" 1 "SpdLmtMdMsgReq_1_msg1" 2 "SpdLmtMdMsgReq_2_msg2" 3 "SpdLmtMdMsgReq_3_msg3" 4 "SpdLmtMdMsgReq_4_msg4" 5 "SpdLmtMdMsgReq_5_msg5" 6 "SpdLmtMdMsgReq_6_msg6" 7 "SpdLmtMdMsgReq_7_msg7";
VAL_ 844 NonDirectDMSSysSts 0 "NonDirectDMSSysSts_0_Off" 1 "NonDirectDMSSysSts_1_StandBy" 2 "NonDirectDMSSysSts_2_Active" 3 "NonDirectDMSSysSts_3_On" 4 "NonDirectDMSSysSts_4_Error";
VAL_ 844 IACCOvTSuppresCmd 0 "IACCOvTSuppresCmd_0_unavallable" 1 "IACCOvTSuppresCmd_1_Off" 2 "IACCOvTSuppresCmd_2_Left" 3 "IACCOvTSuppresCmd_3_Right" 4 "IACCOvTSuppresCmd_4_Auto" 5 "IACCOvTSuppresCmd_5_Reserve" 6 "IACCOvTSuppresCmd_6_Reserve" 7 "IACCOvTSuppresCmd_7_Reserve";
VAL_ 755 LADSInfoDispReqToICM_HPP 0 "LADSInfoDispReqToICM_0_Reserved" 2 "LADSInfoDispReqToICM_2_Vehicle_speed_is_too_high_APA_system_abort" 3 "LADSInfoDispReqToICM_3_Vehicle_speed_is_too_high_please_slow_down" 4 "LADSInfoDispReqToICM_4_Parking_slot_searching" 5 "LADSInfoDispReqToICM_5_Parking_Exit" 7 "LADSInfoDispReqToICM_7_Please_stop_the_car" 9 "LADSInfoDispReqToICM_9_Parking_pause_please_confirm_in_APP" 10 "LADSInfoDispReqToICM_10_Press_start_for_APA_vehicle_control_or_choose_RPA" 11 "LADSInfoDispReqToICM_11_Parking_pause_please_confirm_safety" 12 "LADSInfoDispReqToICM_12_EPB_operated_Parking_exit" 13 "LADSInfoDispReqToICM_13_No_obstacle_park_out_by_yourself" 14 "LADSInfoDispReqToICM_14_Please_press_start_park_out" 15 "LADSInfoDispReqToICM_15_Parking_pause_please_press_continue" 16 "LADSInfoDispReqToICM_16_Please_fasten_the_safety_belt" 17 "LADSInfoDispReqToICM_17_Please_close_the_door" 18 "LADSInfoDispReqToICM_18_LADS_unavailable_parking_exit" 19 "LADSInfoDispReqToICM_19_Left_steering" 22 "LADSInfoDispReqToICM_22_RPA_ready_Please_leave_the_car_and_use_app" 29 "LADSInfoDispReqToICM_29_Right_steering" 30 "LADSInfoDispReqToICM_30_Please_step_on_the_brake_and_press_the_SSB" 33 "LADSInfoDispReqToICM_33_Barrier_exist_please_remove" 34 "LADSInfoDispReqToICM_34_Steering_wheel_has_been_turned" 35 "LADSInfoDispReqToICM_35_Accelerator_pressed" 37 "LADSInfoDispReqToICM_37_Shift_operated" 38 "LADSInfoDispReqToICM_38_Adjustment_time_exceeded" 39 "LADSInfoDispReqToICM_39_Slope_too_big" 40 "LADSInfoDispReqToICM_40_Disturbe_overtime" 41 "LADSInfoDispReqToICM_41_Space_too_small" 44 "LADSInfoDispReqToICM_44_Please_release_brake_and_pay_attention_to_surroundings_using_active_control_measure_if_necessary" 45 "LADSInfoDispReqToICM_45_Parking_is_ongoing" 46 "LADSInfoDispReqToICM_46_Parking_manoeuvre_has_completed_Please_take_over_vehicle" 48 "LADSInfoDispReqToICM_48_System_overtime_APA_system_quit" 63 "LADSInfoDispReqToICM_63_Environment_Changed" 65 "LADSInfoDispReqToICM_65_Please_stop_the_car_first" 66 "LADSInfoDispReqToICM_66_Please_shift_to_P_first" 67 "LADSInfoDispReqToICM_67_Please_apply_the_EPB_first" 68 "LADSInfoDispReqToICM_68_Please_start_the_vehicle" 69 "LADSInfoDispReqToICM_69_Please_unlock_the_vehicle" 70 "LADSInfoDispReqToICM_70_Please_takeover" 97 "LADSInfoDispReqToICM_97_Tire_pressure_abnormal" 98 "LADSInfoDispReqToICM_98_Please_turn_off_the_engine_manually" 99 "LADSInfoDispReqToICM_99_Please_lock_the_vehicle" 100 "LADSInfoDispReqToICM_100_Long_time_not_operated" 101 "LADSInfoDispReqToICM_101_Engine_start_error" 102 "LADSInfoDispReqToICM_102_Hazard_start_error" 103 "LADSInfoDispReqToICM_103_Unlock_failed" 104 "LADSInfoDispReqToICM_104_SSB_pressed" 105 "LADSInfoDispReqToICM_105_Bluetooth_inactive" 106 "LADSInfoDispReqToICM_106_Has_changed_to_normal_drive_mode" 107 "LADSInfoDispReqToICM_107_ACC_actived_LADS_exit" 108 "LADSInfoDispReqToICM_108_AEB_actived_LADS_exit" 109 "LADSInfoDispReqToICM_109_TJA_actived_LADS_exit" 110 "LADSInfoDispReqToICM_110_Locked_the_car" 111 "LADSInfoDispReqToICM_111_Not_choose_RPA" 112 "LADSInfoDispReqToICM_112_APP_exit_please_move_to_FICM" 113 "LADSInfoDispReqToICM_113_Vehicle_does_not_stop" 114 "LADSInfoDispReqToICM_114_Barrier_in_slot_change_another" 128 "LADSInfoDispReqToICM_128_Please_press_the_brake_pedal_vehicle_control_has_not_started" 129 "LADSInfoDispReqToICM_129_Parking_pause_please_press_the_button" 130 "LADSInfoDispReqToICM_130_Detecting_if_the_slot_space_is_enough" 146 "LADSInfoDispReqToICM_146_System_selfchecking" 147 "LADSInfoDispReqToICM_147_Please_select_park_out_direction" 148 "LADSInfoDispReqToICM_148_NRCD_is_ready" 149 "LADSInfoDispReqToICM_149_Parking_pause_please_press_continue_in_APP" 160 "LADSInfoDispReqToICM_160_Engine_is_not_ready" 161 "LADSInfoDispReqToICM_161_LADS_fault_can_not_open" 162 "LADSInfoDispReqToICM_162_LADS_busy_can_not_open" 163 "LADSInfoDispReqToICM_163_Speed_is_too_high_can_not_open" 164 "LADSInfoDispReqToICM_164_Vehicle_is_not_stop_can_not_open" 165 "LADSInfoDispReqToICM_165_ADAS_is_actived" 176 "LADSInfoDispReqToICM_176_Parking_into_Power_swap_station" 177 "LADSInfoDispReqToICM_177_Outside_mirror_is_fold" 178 "LADSInfoDispReqToICM_178_Direction_selection_timeout" 179 "LADSInfoDispReqToICM_179_Single_driving_distance_out_of_limit" 180 "LADSInfoDispReqToICM_180_User_pause_the_parking" 181 "LADSInfoDispReqToICM_181_Vehicle_Blocked" 182 "LADSInfoDispReqToICM_182_Slot_searching_fault" 183 "LADSInfoDispReqToICM_183_Slot_searching_conditions_not_satisfied" 184 "LADSInfoDispReqToICM_184_Parking_conditions_not_satisfied" 185 "LADSInfoDispReqToICM_185_Space_limit" 186 "LADSInfoDispReqToICM_186_Speed_high" 187 "LADSInfoDispReqToICM_187_External_ecu_failure" 188 "LADSInfoDispReqToICM_188_Phone_Low_battery" 189 "LADSInfoDispReqToICM_189_External_esc_active" 190 "LADSInfoDispReqToICM_190_Unsafe_Behavior" 191 "LADSInfoDispReqToICM_191_Airbag_deployed" 192 "LADSInfoDispReqToICM_192_USS_covered" 193 "LADSInfoDispReqToICM_193_AVM_camera_covered" 194 "LADSInfoDispReqToICM_194_Answer_the_phone" 195 "LADSInfoDispReqToICM_195_Engine_Front_Door_Open" 196 "LADSInfoDispReqToICM_196_Cruising_conditions_satisfied" 197 "LADSInfoDispReqToICM_197_Please_select_APA_super_or_RPA_super" 198 "LADSInfoDispReqToICM_198_Shift_N_gear_overtime" 199 "LADSInfoDispReqToICM_199_Please_release_Accelerator" 200 "LADSInfoDispReqToICM_200_Charge_gun_connect_can_not_open" 201 "LADSInfoDispReqToICM_201_Vehicle_low_battery_can_not_open" 202 "LADSInfoDispReqToICM_202_Ramp_too_steep_can_not_open" 203 "LADSInfoDispReqToICM_203_Digital_key_inside_the_car_can_not_open" 204 "LADSInfoDispReqToICM_204_Slot_too_small_Recommend_remote_control" 205 "LADSInfoDispReqToICM_205_Free_parking_slot_available" 206 "LADSInfoDispReqToICM_206_Free_parking_slot_unavailable" 207 "LADSInfoDispReqToICM_207_RPA_is_ongoing_Please_try_later" 208 "LADSInfoDispReqToICM_208_FOTA_is_ongoing_Please_try_later" 209 "LADSInfoDispReqToICM_209_vehicle_is_cold_starting_and__expected_to_take_a_long_time_Thanks_for_your_patience" 210 "LADSInfoDispReqToICM_210_Please_proceed_to_the_memory_path" 211 "LADSInfoDispReqToICM_211_Please_reduce_the_speed" 212 "LADSInfoDispReqToICM_212_Going_too_fast__memory_parking_has_exited" 213 "LADSInfoDispReqToICM_213_Slope_is_too_high__Memory_parking_has_exited" 214 "LADSInfoDispReqToICM_214_Memory_parking_hasexited" 215 "LADSInfoDispReqToICM_215_Please_select_the_parking_space_and_switch_to_P_gear_after_pouring_into_the_parking_space" 216 "LADSInfoDispReqToICM_216_Route_overlaps__Memory_parking_has_exited" 217 "LADSInfoDispReqToICM_217_Door_opens__memory_parking_has_exited" 218 "LADSInfoDispReqToICM_218_Astern_distance_is_too_far__Memory_parking_has_exited" 219 "LADSInfoDispReqToICM_219_Learning_distance_is_about_to_exceed_the_limit" 220 "LADSInfoDispReqToICM_220_Route_learning_distance_exceeded__memory_parking_has_exited" 221 "LADSInfoDispReqToICM_221_Route_learning_timed_out__Memory_parking_has_exited" 222 "LADSInfoDispReqToICM_222_Please_release_the_brake" 223 "LADSInfoDispReqToICM_223_Please_close_the_door_or_trunk" 224 "LADSInfoDispReqToICM_224_Target_space_is_occupied__We_will_be_pulling_into_the_next_space_for_you" 225 "LADSInfoDispReqToICM_225_Switched_to_berthing_en_route" 226 "LADSInfoDispReqToICM_226_Memory_parking_has_exited__please_take_over_the_vehicle";
VAL_ 755 ESSAdoWrnngDspCmd 0 "ESSAdoWrnngDspCmd_0_Unavailable" 1 "ESSAdoWrnngDspCmd_1_off" 2 "ESSAdoWrnngDspCmd_2_on" 3 "ESSAdoWrnngDspCmd_3_reserved";
VAL_ 755 HPPFnSts 0 "HPPFnSts_0_Default" 1 "HPPFnSts_1_HPP_Map_Learning" 2 "HPPFnSts_2_HPP_Map_Parking_in_Slot_Learning" 3 "HPPFnSts_3_Map_Building_Processing" 4 "HPPFnSts_4_Waiting_to_save" 5 "HPPFnSts_5_HPP_Learning_Complete" 6 "HPPFnSts_6_HPP_Learning_Fail" 7 "HPPFnSts_7_HPP_Cruising_in" 8 "HPPFnSts_8_HPP_Cruising_out" 9 "HPPFnSts_9_HPP_Cruising_Paused" 10 "HPPFnSts_10_HPP_Parking_in" 11 "HPPFnSts_11_HPP_Parking_out" 12 "HPPFnSts_12_HPP_Parking_in_out_Paused" 13 "HPPFnSts_13_HPP_Cruising_Complete" 14 "HPPFnSts_14_HPP_Cruising_Fail" 15 "HPPFnSts_15_Map_Wating_to_Save" 16 "HPPFnSts_16_Reserved0" 17 "HPPFnSts_17_Reserved1" 18 "HPPFnSts_18_Reserved2" 19 "HPPFnSts_19_Reserved3" 20 "HPPFnSts_20_Reserved4" 21 "HPPFnSts_21_Reserved5" 22 "HPPFnSts_22_Reserved6" 23 "HPPFnSts_23_Reserved7" 24 "HPPFnSts_24_Reserved8" 25 "HPPFnSts_25_Reserved9" 26 "HPPFnSts_26_Reserved10" 27 "HPPFnSts_27_Reserved11" 28 "HPPFnSts_28_Reserved12" 29 "HPPFnSts_29_Reserved13" 30 "HPPFnSts_30_Reserved14" 31 "HPPFnSts_31_Reserved15" 32 "HPPFnSts_32_Reserved16" 33 "HPPFnSts_33_Reserved17" 34 "HPPFnSts_34_Reserved18" 35 "HPPFnSts_35_Reserved19" 36 "HPPFnSts_36_Reserved20" 37 "HPPFnSts_37_Reserved21" 38 "HPPFnSts_38_Reserved22" 39 "HPPFnSts_39_Reserved23" 40 "HPPFnSts_40_Reserved24" 41 "HPPFnSts_41_Reserved25" 42 "HPPFnSts_42_Reserved26" 43 "HPPFnSts_43_Reserved27" 44 "HPPFnSts_44_Reserved28" 45 "HPPFnSts_45_Reserved29" 46 "HPPFnSts_46_Reserved30" 47 "HPPFnSts_47_Reserved31" 48 "HPPFnSts_48_Reserved32" 49 "HPPFnSts_49_Reserved33" 50 "HPPFnSts_50_Reserved34" 51 "HPPFnSts_51_Reserved35" 52 "HPPFnSts_52_Reserved36" 53 "HPPFnSts_53_Reserved37" 54 "HPPFnSts_54_Reserved38" 55 "HPPFnSts_55_Reserved39" 56 "HPPFnSts_56_Reserved40" 57 "HPPFnSts_57_Reserved41" 58 "HPPFnSts_58_Reserved42" 59 "HPPFnSts_59_Reserved43" 60 "HPPFnSts_60_Reserved44" 61 "HPPFnSts_61_Reserved45" 62 "HPPFnSts_62_Reserved46" 63 "HPPFnSts_63_Reserved47";
VAL_ 755 HPPInBmtSts 0 "HPPInBmtSts_0_Not_In_Basement" 1 "HPPInBmtSts_1_In_Basement";
VAL_ 755 ESSDspCmd 0 "ESSSwDspCmd_0_Unavailable" 1 "ESSSwDspCmd_1_Off" 2 "ESSSwDspCmd_2_On" 3 "AESSwDspCmd_3_On";
VAL_ 755 NOACitySysMsg 0 "NOACitySysMsg_0_No_display" 1 "NOACitySysMsg_1_PleaseNoticeTrafficLightAhead" 2 "NOACitySysMsg_2_About_to_TurnLeft" 3 "NOACitySysMsg_3_About_to_TurnRight" 4 "NOACitySysMsg_4_About_to_TurnAround" 5 "NOACitySysMsg_5_EnteringBusLane" 6 "NOACitySysMsg_6_EnteringReversibleLane" 7 "NOACitySysMsg_7_DecelerationToStop" 8 "NOACitySysMsg_8_WaitToStart" 9 "NOACitySysMsg_9_GreenLightToStart" 10 "NOACitySysMsg_10_GoStraightThroughIntersection" 11 "NOACitySysMsg_11_TOR_DifficultToUturn" 12 "NOACitySysMsg_12_EnteringWaitingArea" 13 "NOACitySysMsg_13_LongQuequeAtIntersection" 14 "NOACitySysMsg_14_YieldVRU" 15 "NOACitySysMsg_15_NoParkingArea" 16 "NOACitySysMsg_16_About_to_EnterRoundabout" 17 "NOACitySysMsg_17_About_to_DriveOutRoundabout" 18 "NOACitySysMsg_18_About_to_Detour" 19 "NOACitySysMsg_19_Detouring" 20 "NOACitySysMsg_20_CompleteDetour" 21 "NOACitySysMsg_21_FailtoDetour" 22 "NOACitySysMsg_22_LanechangeForDetouring" 23 "NOACitySysMsg_23_MergelaneAndPassInSequence" 24 "NOACitySysMsg_24_PleaseAssistCNOAWithAccelerateSlightly" 25 "NOACitySysMsg_25_PleaseAssistCNOAWithTurnSteeringWheelSlightly" 26 "NOACitySysMsg_26_TrafficPolice_PleaseTOR" 27 "NOACitySysMsg_27_About_to_EnterMainRoad" 28 "NOACitySysMsg_28_About_to_EnterReliefRoad" 29 "NOACitySysMsg_29_About_to_DetourInOppositeLane" 30 "NOACitySysMsg_30_EnteringTidalLane" 31 "NOACitySysMsg_31_About_to_EnterMTC" 32 "NOACitySysMsg_32_About_to_EnterETC" 33 "NOACitySysMsg_33_Reserved" 34 "NOACitySysMsg_34_Reserved" 35 "NOACitySysMsg_35_Gate_arm_raised_D2D" 36 "NOACitySysMsg_36_Turnstile_wait_timeout_D2D" 37 "NOACitySysMsg_37_About_to_go_through_the_gate_D2D";
VAL_ 755 FLSUSSSts 0 "FLSUSSSts_0_Normal" 1 "FLSUSSSts_1_Fault" 2 "FLSUSSSts_2_Blind";
VAL_ 755 NOPSysMsg 0 "NOPSysMsg_0_No_display" 1 "NOPSysMsg_1_NOP_not_available" 2 "NOPSysMsg_2_Please_hold_steering_wheel" 3 "NOPSysMsg_3_Please_control_steering_wheel" 4 "NOPSysMsg_4_Please_take_over_control_of_vehicle" 5 "NOPSysMsg_5_Approaching_unreleased_highway_section" 6 "NOPSysMsg_6_A_lane_markings_not_present" 7 "NOPSysMsg_7_Road_condition_insufficient" 8 "NOPSysMsg_8_Unreleased_highway" 9 "NOPSysMsg_9_Out_of_speed_range" 10 "NOPSysMsg_10_Please_using_direction_lamp_switch_to_comfirm_right_lane_change_recommendation" 11 "NOPSysMsg_11_Please_using_direction_lamp_switch_to_comfirm_left_lane_change_recommendation" 12 "NOPSysMsg_12_Please_turn_off_direction_lamp_switch" 13 "NOPSysMsg_13_Entering_ramp_on_right_in_2km" 14 "NOPSysMsg_14_Entering_ramp_on_left_in_2km" 15 "NOPSysMsg_15_Entering_ramp_on_right_1km" 16 "NOPSysMsg_16_Entering_ramp_on_left_1km" 17 "NOPSysMsg_17_Entering_ramp_immediately" 18 "NOPSysMsg_18_Entering_main_road_of_highway" 19 "NOPSysMsg_19_About_to_left_lane_change" 20 "NOPSysMsg_20_About_to_right_lane_change" 21 "NOPSysMsg_21_Stay_in_current_lane" 22 "NOPSysMsg_22_Approaching_work_zone" 23 "NOPSysMsg_23_Over_ramp_speed_limit_please_slow_down" 24 "NOPSysMsg_24_Please_change_lane_to_right_manually" 25 "NOPSysMsg_25_Please_change_lane_to_left_manually" 26 "NOPSysMsg_26_Please_merge_into_main_roada_manually" 27 "NOPSysMsg_27_About_to_finish_NOP_navigation" 28 "NOPSysMsg_28_Location_signal_weak" 29 "NOPSysMsg_29_Tire_pressure_condition_insufficient" 30 "NOPSysMsg_30_Brake_disk_temperatue_high" 31 "NOPSysMsg_31_HDM_system_not_available" 32 "NOPSysMsg_32_Please_turn_off_direction_lamp_switch" 33 "NOPSysMsg_33_Limited_function_due_to_faults" 34 "NOPSysMsg_34_Navigation_not_ready" 35 "NOPSysMsg_35_Navigation_started" 36 "NOPSysMsg_36_Recommend_to_Change_to_Left_lane" 37 "NOPSysMsg_37_Recommend_to_Change_to_Right_lane" 38 "NOPSysMsg_38_NOP_approach_boundary" 39 "NOPSysMsg_39_NOP_exit" 40 "NOPSysMsg_40_Navigation_finished" 41 "NOPSysMsg_41_Please_Open_NOA_Switch" 42 "NOPSysMsg_42_Please_Notice_Merging_Veicle" 43 "NOPSysMsg_43_Out_of_Override_Time" 44 "NOPSysMsg_44_Reserved" 45 "NOPSysMsg_45_Left_500m_Exit" 46 "NOPSysMsg_46_Left_200m_Exit" 47 "NOPSysMsg_47_Left_500m_Construct" 48 "NOPSysMsg_48_Approaching_Tunnel" 49 "NOPSysMsg_49_Please_change_lane_manually" 50 "NOPSysMsg_50_Update_Planning_Path" 51 "NOPSysMsg_51_Approaching_AccelerationLane" 52 "NOPSysMsg_52_Approaching_Jam_to_Change_to_Left_lane" 53 "NOPSysMsg_53_Approaching_Jam_to_Change_to_Right_lane" 54 "NOPSysMsg_54_Entering_ramp_on_right_immediately" 55 "NOPSysMsg_55_Entering_ramp_on_left_immediately" 56 "NOPSysMsg_56_Entering_main_on_right_road_of_highway" 57 "NOPSysMsg_57_Entering_main_on_left_road_of_highway" 58 "NOPSysMsg_58_Selecting_toll_lane_D2D" 59 "NOPSysMsg_59_Lane_recognition_failed_manual_takeover_D2D";
VAL_ 755 LCRInHMI 0 "LCRInHMI_0_unavailable" 1 "LCRInHMI_1_NotActive" 2 "LCRInHMI_2_Left" 3 "LCRInHMI_3_Right";
VAL_ 755 NOADistDecMsg 0 "NOADistDecMsg_0_NoDisplay" 1 "NOADistDecMsg_1_Dec1" 2 "NOADistDecMsg_2_Dec2" 3 "NOADistDecMsg_3_Dec3" 4 "NOADistDecMsg_4_Dec4" 5 "NOADistDecMsg_5_Dec5" 6 "NOADistDecMsg_6_Dec6" 7 "NOADistDecMsg_7_Dec7" 8 "NOADistDecMsg_8_Dec8" 9 "NOADistDecMsg_9_Dec9" 10 "NOADistDecMsg_10_Dec10" 11 "NOADistDecMsg_11_Dec11" 12 "NOADistDecMsg_12_Dec12" 13 "NOADistDecMsg_13_Dec13" 14 "NOADistDecMsg_14_Dec14" 15 "NOADistDecMsg_15_Dec15" 16 "NOADistDecMsg_16_Dec16" 17 "NOADistDecMsg_17_Dec17" 18 "NOADistDecMsg_18_Dec18" 19 "NOADistDecMsg_19_Dec19" 20 "NOADistDecMsg_20_Dec20" 21 "NOADistDecMsg_21_Dec21" 22 "NOADistDecMsg_22_Dec22" 23 "NOADistDecMsg_23_Dec23" 24 "NOADistDecMsg_24_Dec24" 25 "NOADistDecMsg_25_Dec25" 26 "NOADistDecMsg_26_Dec26" 27 "NOADistDecMsg_27_Dec27" 28 "NOADistDecMsg_28_Dec28" 29 "NOADistDecMsg_29_Dec29" 30 "NOADistDecMsg_30_Dec30" 31 "NOADistDecMsg_31_Dec31";
VAL_ 755 NarRoVslAssSwResp 0 "NarRoVslAssSwResp_0_0_Unavalible" 1 "NarRoVslAssSwResp_1_1_OFF" 2 "NarRoVslAssSwResp_2_2_Near" 3 "NarRoVslAssSwResp_3_3_Middle" 4 "NarRoVslAssSwResp_4_4_Far";
VAL_ 755 NrwroadBwdAssMesg 0 "NrwroadBwdAssMesg_0_reserved" 1 "NrwroadBwdAssMesg_1_reserved" 2 "NrwroadBwdAssMesg_2_reserved" 3 "NrwroadBwdAssMesg_3_reserved" 4 "NrwroadBwdAssMesg_4_reserved" 5 "NrwroadBwdAssMesg_5_reserved" 6 "NrwroadBwdAssMesg_6_reserved" 7 "NrwroadBwdAssMesg_7_reserved" 8 "NrwroadBwdAssMesg_8_reserved" 9 "NrwroadBwdAssMesg_9_reserved" 10 "NrwroadBwdAssMesg_10_reserved" 11 "NrwroadBwdAssMesg_11_reserved" 12 "NrwroadBwdAssMesg_12_reserved" 13 "NrwroadBwdAssMesg_13_reserved" 14 "NrwroadBwdAssMesg_14_reserved" 15 "NrwroadBwdAssMesg_15_reserved" 16 "NrwroadBwdAssMesg_16_reserved" 17 "NrwroadBwdAssMesg_17_reserved" 18 "NrwroadBwdAssMesg_18_reserved" 19 "NrwroadBwdAssMesg_19_reserved" 20 "NrwroadBwdAssMesg_20_reserved" 21 "NrwroadBwdAssMesg_21_reserved" 22 "NrwroadBwdAssMesg_22_reserved" 23 "NrwroadBwdAssMesg_23_reserved" 24 "NrwroadBwdAssMesg_24_reserved" 25 "NrwroadBwdAssMesg_25_reserved" 26 "NrwroadBwdAssMesg_26_reserved" 27 "NrwroadBwdAssMesg_27_reserved" 28 "NrwroadBwdAssMesg_28_reserved" 29 "NrwroadBwdAssMesg_29_reserved" 30 "NrwroadBwdAssMesg_30_reserved" 31 "NrwroadBwdAssMesg_31_reserved";
VAL_ 755 JAMsgReq 0 "JAMsgReq_0_NoDisplay" 1 "JAMsgReq_1__1" 2 "JAMsgReq_2__2" 3 "JAMsgReq_3__3" 4 "JAMsgReq_4__4" 5 "JAMsgReq_5__5" 6 "JAMsgReq_6__6" 7 "JAMsgReq_7__7" 8 "JAMsgReq_8__8" 9 "JAMsgReq_9__9" 10 "JAMsgReq_10__10" 11 "JAMsgReq_11__11" 12 "JAMsgReq_12__12" 13 "JAMsgReq_13__12" 14 "JAMsgReq_14__14" 15 "JAMsgReq_15__15";
VAL_ 755 DetourMsgReq 0 "DetourMsgReq_0_NoDisplay" 1 "DetourMsgReq_1__1" 2 "DetourMsgReq_2__2" 3 "DetourMsgReq_3__3" 4 "DetourMsgReq_4__4" 5 "DetourMsgReq_5__5" 6 "DetourMsgReq_6__6" 7 "DetourMsgReq_7__7" 8 "DetourMsgReq_8__8" 9 "DetourMsgReq_9__9" 10 "DetourMsgReq_10__10" 11 "DetourMsgReq_11__11" 12 "DetourMsgReq_12__12" 13 "DetourMsgReq_13__12" 14 "DetourMsgReq_14__14" 15 "DetourMsgReq_15__15";
VAL_ 755 ParkngOutDircnSelResult 0 "ParkngOutDircnSelResult_0_none" 1 "ParkngOutDircnSelResult_1_Front_Left_Cross" 2 "ParkngOutDircnSelResult_2_Front_Left_Parallel" 3 "ParkngOutDircnSelResult_3_Front_Out" 4 "ParkngOutDircnSelResult_4_Front_Right_Cross" 5 "ParkngOutDircnSelResult_5_Front_Right_Parallel" 6 "ParkngOutDircnSelResult_6_Back_Out" 7 "ParkngOutDircnSelResult_7_Back_Left_Cross" 8 "ParkngOutDircnSelResult_8_Back_Right_Cross" 9 "ParkngOutDircnSelResult_9_Reserved" 10 "ParkngOutDircnSelResult_10_Reserved" 11 "ParkngOutDircnSelResult_11_Reserved" 12 "ParkngOutDircnSelResult_12_Reserved" 13 "ParkngOutDircnSelResult_13_Reserved" 14 "ParkngOutDircnSelResult_14_Reserved" 15 "ParkngOutDircnSelResult_15_Reserved";
VAL_ 755 NOAQukChgSwDspCmd 0 "NOAQukChgSwDspCmd_0_unavailable" 1 "NOAQukChgSwDspCmd_1_temporary_unavailable" 2 "NOAQukChgSwDspCmd_2_NOA2LCC" 3 "NOAQukChgSwDspCmd_3_LCC2NOA";
VAL_ 755 NrwroadBwdAssSwSts 0 "NrwroadBwdAssSwSts_0_0_Unavialable" 1 "NrwroadBwdAssSwSts_1_1_Highlight" 2 "NrwroadBwdAssSwSts_2_2_Flashing" 3 "NrwroadBwdAssSwSts_3_3_Hide" 4 "NrwroadBwdAssSwSts_4_4_Reserved4" 5 "NrwroadBwdAssSwSts_5_5_Reserved5" 6 "NrwroadBwdAssSwSts_6_6_Reserved6" 7 "NrwroadBwdAssSwSts_7_7_Reserved7";
VAL_ 755 FLUSSSts 0 "FLUSSSts_0_Normal" 1 "FLUSSSts_1_Fault" 2 "FLUSSSts_2_Blind";
VAL_ 755 PEBSts 0 "PEBSts_0_off" 1 "PEBSts_1_passive" 2 "PEBSts_2_standby" 3 "PEBSts_3_active" 4 "PEBSts_4_error" 5 "PEBSts_5_Reserved";
VAL_ 755 FrtCarGoNotfrDspCmd 0 "FrtCarGoNotfrDspCmd_0_Unavallable" 1 "FrtCarGoNotfrDspCmd_1_Off" 2 "FrtCarGoNotfrDspCmd_2_On" 3 "FrtCarGoNotfrDspCmd_3_Reserved";
VAL_ 755 FRSUSSSts 0 "FRSUSSSts_0_Normal" 1 "FRSUSSSts_1_Fault" 2 "FRSUSSSts_2_Blind";
VAL_ 755 FMRUSSSts 0 "FMRUSSSts_0_Normal" 1 "FMRUSSSts_1_Fault" 2 "FMRUSSSts_2_Blind";
VAL_ 755 FMLUSSSts 0 "FMLUSSSts_0_Normal" 1 "FMLUSSSts_1_Fault" 2 "FMLUSSSts_2_Blind";
VAL_ 755 NOALaneSetDspCmd 0 "NOALaneSetDspCmd_0_NOALaneSetCmd_0_unavailable" 1 "NOALaneSetDspCmd_1_NOALaneSetCmd_1_Left1" 2 "NOALaneSetDspCmd_2_NOALaneSetCmd_2_Left2" 3 "NOALaneSetDspCmd_3_Reserved";
VAL_ 755 NOAETCSetDspCmd 0 "NOAETCSetDspCmd_0_NoRequest" 1 "NOAETCSetDspCmd_1_MTC" 2 "NOAETCSetDspCmd_2_ETC" 3 "NOAETCSetDspCmd_3_Reserved";
VAL_ 755 LCRSwDspCmd 0 "LCRSwDspCmd_0_unavailable" 1 "LCRSwDspCmd_1_off" 2 "LCRSwDspCmd_2_on" 3 "LCRSwDspCmd_3_reserved";
VAL_ 755 FRUSSSts 0 "FRUSSSts_0_Normal" 1 "FRUSSSts_1_Fault" 2 "FRUSSSts_2_Blind";
VAL_ 755 NOPCitySwDspCmd 0 "NOPCitySwDspCmd_0_Unavailable" 1 "NOPCitySwDspCmd_1_Off" 2 "NOPCitySwDspCmd_2_On" 3 "NOPCitySwDspCmd_3_Reserved";
VAL_ 755 NOPSwDspCmd 0 "NOPSwDspCmd_0_Unavailable" 1 "NOPSwDspCmd_1_off" 2 "NOPSwDspCmd_2_NOP_NdConfirm" 3 "NOPSwDspCmd_3_NOP_NotNdConfirm";
VAL_ 755 NOAReportSetDspCmd 0 "NOAReportSetDspCmd_0_NOAReportSetCmd_0_unavailable" 1 "NOAReportSetDspCmd_1_NOAReportSetCmd_1_detail" 2 "NOAReportSetDspCmd_2_NOAReportSetCmd_2_concision" 3 "NOAReportSetDspCmd_3_NOAReportSetCmd__3_minimal";
VAL_ 755 RLUSSSts 0 "RLUSSSts_0_Normal" 1 "RLUSSSts_1_Fault" 2 "RLUSSSts_2_Blind";
VAL_ 755 RLSUSSSts 0 "RLSUSSSts_0_Normal" 1 "RLSUSSSts_1_Fault" 2 "RLSUSSSts_2_Blind";
VAL_ 755 PEBWarngReq 0 "PEBWarngReq_0_Default" 1 "PEBWarngReq_1_TURN_GREEN" 2 "PEBWarngReq_2_TURN_YELLOW" 3 "PEBWarngReq_3_TURN_RED";
VAL_ 755 NrwroadBwdAssConfrmSwDscmd 0 "NrwroadBwdAssConfrmSwDscmd_0_0_Unavalible" 1 "NrwroadBwdAssConfrmSwDscmd_1_1_Activeconformed" 2 "NrwroadBwdAssConfrmSwDscmd_2_2_quitconformed";
VAL_ 755 RRUSSSts 0 "RRUSSSts_0_Normal" 1 "RRUSSSts_1_Fault" 2 "RRUSSSts_2_Blind";
VAL_ 755 RRSUSSSts 0 "RRSUSSSts_0_Normal" 1 "RRSUSSSts_1_Fault" 2 "RRSUSSSts_2_Blind";
VAL_ 755 RMRUSSSts 0 "RMRUSSSts_0_Normal" 1 "RMRUSSSts_1_Fault" 2 "RMRUSSSts_2_Blind";
VAL_ 755 RMLUSSSts 0 "RMLUSSSts_0_Normal" 1 "RMLUSSSts_1_Fault" 2 "RMLUSSSts_2_Blind";
VAL_ 755 ParkngOutFRCrsSts 0 "ParkngOutFRCrsSts_0_Invalid" 1 "ParkngOutFRCrsSts_1_Valid";
VAL_ 755 ParkngOutFLParllSts 0 "ParkngOutFLParllSts_0_Invalid" 1 "ParkngOutFLParllSts_1_Valid";
VAL_ 755 ParkngOutFLCrsSts 0 "ParkngOutFLCrsSts_0_Invalid" 1 "ParkngOutFLCrsSts_1_Valid";
VAL_ 755 ParkngOutBkRCrsSts 0 "ParkngOutBkRCrsSts_0_Invalid" 1 "ParkngOutBkRCrsSts_1_Valid";
VAL_ 755 ParkngOutBkLCrsSts 0 "ParkngOutBkLCrsSts_0_Invalid" 1 "ParkngOutBkLCrsSts_1_Valid";
VAL_ 755 ParkngOutBkCrsSts 0 "ParkngOutBkCrsSts_0_Invalid" 1 "ParkngOutBkCrsSts_1_Valid";
VAL_ 755 HPPOnRoutSts 0 "HPPOnRoutSts_0_Not_On_Rout" 1 "HPPOnRoutSts_1_On_Rout";
VAL_ 755 HPPMapBuildSts 0 "HPPMapBuildSts_0_Not_Built" 1 "HPPMapBuildSts_1_Built";
VAL_ 755 ParkngDirAvlSts 0 "ParkngDirAvlSts_0_Rear" 1 "ParkngDirAvlSts_1_Head" 2 "ParkngDirAvlSts_2_Rear_and_Head" 3 "ParkngDirAvlSts_3_Reserved" 4 "ParkngDirAvlSts_4_Reserved" 5 "ParkngDirAvlSts_5_Reserved" 6 "ParkngDirAvlSts_6_Reserved" 7 "ParkngDirAvlSts_7_Reserved";
VAL_ 755 ParkngDirSwResp 0 "ParkngDirSwResp_0_No_Request" 1 "ParkngDirSwResp_1_Front_parking_in" 2 "ParkngDirSwResp_2_back_parking_in" 3 "ParkngDirSwResp_3_Reserved";
VAL_ 755 ParkngSlotFindSts 0 "ParkngSlotFindSts_0_False" 1 "ParkngSlotFindSts_1_True";
VAL_ 755 ParkngOutFrtCrsSts 0 "ParkngOutFrtCrsSts_0_Invalid" 1 "ParkngOutFrtCrsSts_1_Valid";
VAL_ 755 ParkngOutFRParllSts 0 "ParkngOutFRParllSts_0_Invalid" 1 "ParkngOutFRParllSts_1_Valid";
VAL_ 755 PEBSwResp 0 "PEBSwResp_0_unavailable" 1 "PEBSwResp_1_On" 2 "PEBSwResp_2_Off" 3 "PEBSwResp_3_Reserve";
VAL_ 774 ParkngNCPAvlSts 0 "ParkngNCPAvlSts_0_None" 1 "ParkngNCPAvlSts_1_Middle" 2 "ParkngNCPAvlSts_2_Left" 3 "ParkngNCPAvlSts_3_Left_and_Middle" 4 "ParkngNCPAvlSts_4_Righht" 5 "ParkngNCPAvlSts_5_Right_and_Middle" 6 "ParkngNCPAvlSts_6_Right_and_Left" 7 "ParkngNCPAvlSts_7_ALL";
VAL_ 774 TrfcLghtFuctionSwSts 0 "TrfcLghtFuctionSwSts_0_Trfclghtfnswsts_0_Unavailable" 1 "TrfcLghtFuctionSwSts_1_TrfcLghtFnSwSts_1_OFF" 2 "TrfcLghtFuctionSwSts_2_TrfcLghtFnSwSts_2_Warning" 3 "TrfcLghtFuctionSwSts_3_TrfcLghtFnSwSts_3_Contorl";
VAL_ 774 APASpdMdSwSts 0 "APASpdMdSwSts_0_Disable" 1 "APASpdMdSwSts_1_Fast" 2 "APASpdMdSwSts_2_Slow" 3 "APASpdMdSwSts_3_Reserved";
VAL_ 208 APAParkInOffsetType 0 "APAParkInOffsetType_0_INVALID" 1 "APAParkInOffsetType_1_LEFT" 2 "APAParkInOffsetType_2_MIDDLE" 3 "APAParkInOffsetType_3_RIGHT";
VAL_ 208 APASW 0 "APASW_0_CLOSE" 1 "APASW_1_OPEN";
VAL_ 486 FrtCarGoNotfr 0 "FrtCarGoNotfr_0_False" 1 "FrtCarGoNotfr_1_Waminglevel1" 2 "FrtCarGoNotfr_2_Warninglevel2" 3 "FrtCarGoNotfr_3_Warninglevel3";
VAL_ 486 ACCSysFltSts_SCS 0 "ACCSysFltSts_SCS_0_NoError" 1 "ACCSysFltSts_SCS_1_PerformanceDegradation" 2 "ACCSysFltSts_SCS_2_SystemTemporaryUnvailable" 3 "ACCSysFltSts_SCS_3_ServiceRequired" 4 "ACCSysFltSts_SCS_4_Reserved" 5 "ACCSysFltSts_SCS_5_Reserved" 6 "ACCSysFltSts_SCS_6_Reserved" 7 "ACCSysFltSts_SCS_7_Reserved";
VAL_ 337 AutoLaneChngRLaneSts 0 "AutoLaneChngRLaneSts_0_NoRequest" 1 "AutoLaneChngRLaneSts_1_LaneChangeInhibit" 2 "AutoLaneChngRLaneSts_2_WaitingForLaneChangeStarting" 3 "AutoLaneChngRLaneSts_3_LaneChangeInProgress" 4 "AutoLaneChngRLaneSts_4_LaneChangeSucces" 5 "AutoLaneChngRLaneSts_5_LaneChangeFailed" 6 "AutoLaneChngRLaneSts_6_LaneChangeSuppressByDriver" 7 "AutoLaneChngRLaneSts_7_ReturnToEgoLaneByDriver" 8 "AutoLaneChngRLaneSts_8_ReturnToEgoLaneByAlc" 9 "AutoLaneChngRLaneSts_9_LaneChangeManoeuvreWithRisk" 10 "AutoLaneChngRLaneSts_10_ReturnToEgoLaneSuccess" 11 "AutoLaneChngRLaneSts_11_WaitingForALCBecauseVehicleSpeedTooLow" 12 "AutoLaneChngRLaneSts_12_WaitingForALCBecauseVehicleSpeedTooHigh" 13 "AutoLaneChngRLaneSts_13_Vehiclegothroughthelane";
VAL_ 337 ESSDirInd 0 "ESSDirInd_0_Unactive" 1 "ESSDirInd_1_Left" 2 "ESSDirInd_2_Right" 3 "ESSDirInd_3_reserved";
VAL_ 337 PilotTkovMsgReq 0 "PilotTkovMsgReq_0_NoDisplay" 1 "PilotTkovMsgReq_1__1" 2 "PilotTkovMsgReq_2__2" 3 "PilotTkovMsgReq_3__3" 4 "PilotTkovMsgReq_4__4" 5 "PilotTkovMsgReq_5__5" 6 "PilotTkovMsgReq_6__6" 7 "PilotTkovMsgReq_7__7" 8 "PilotTkovMsgReq_8__8" 9 "PilotTkovMsgReq_9__9" 10 "PilotTkovMsgReq_10__10" 11 "PilotTkovMsgReq_11__11" 12 "PilotTkovMsgReq_12__12" 13 "PilotTkovMsgReq_13__12" 14 "PilotTkovMsgReq_14__14" 15 "PilotTkovMsgReq_15__15";
VAL_ 337 NOPSysSts_ZPD 0 "NOPSysSts_ZPD_0_Off" 1 "NOPSysSts_ZPD_1_Passive" 2 "NOPSysSts_ZPD_2_Standby" 3 "NOPSysSts_ZPD_3_HandsOn_active" 4 "NOPSysSts_ZPD_4_HandsFree_active" 5 "NOPSysSts_ZPD_5_Wait_for_driver_to_confirm" 6 "NOPSysSts_ZPD_6_ALC_Active" 7 "NOPSysSts_ZPD_7_Override" 8 "NOPSysSts_ZPD_8_TOR" 9 "NOPSysSts_ZPD_9_Prohibit" 10 "NOPSysSts_ZPD_10_Fault" 11 "NOPSysSts_ZPD_11_SafeStop";
VAL_ 337 PrkgDstCtrlSwResp 0 "PrkgDstCtrlSwResp_0_Unavailable" 1 "PrkgDstCtrlSwResp_1_ON" 2 "PrkgDstCtrlSwResp_2_OFF";
VAL_ 337 ALCSysSts 0 "ALCSysSts_0_Off" 1 "ALCSysSts_1_Standby" 2 "ALCSysSts_2_ActiveRequest" 3 "ALCSysSts_3_ActiveControl" 4 "ALCSysSts_4_Passive" 5 "ALCSysSts_5_LaneChangeReturning" 6 "ALCSysSts_6_TOR" 7 "ALCSysSts_7_Reserve";
VAL_ 337 ALCSysFltSts 0 "ALCSysFltSts_0_No_error" 1 "ALCSysFltSts_1_Performance_degradation" 2 "ALCSysFltSts_2_System_temporary_unavailable" 3 "ALCSysFltSts_3_Service_required" 4 "ALCSysFltSts_4_Reserved";
VAL_ 337 AutoLaneChngLLaneSts 0 "AutoLaneChngLLaneSts_0_NoRequest" 1 "AutoLaneChngLLaneSts_1_LaneChangeInhibit" 2 "AutoLaneChngLLaneSts_2_WaitingForLaneChangeStarting" 3 "AutoLaneChngLLaneSts_3_LaneChangeInProgress" 4 "AutoLaneChngLLaneSts_4_LaneChangeSucces" 5 "AutoLaneChngLLaneSts_5_LaneChangeFailed" 6 "AutoLaneChngLLaneSts_6_LaneChangeSuppressByDriver" 7 "AutoLaneChngLLaneSts_7_ReturnToEgoLaneByDriver" 8 "AutoLaneChngLLaneSts_8_ReturnToEgoLaneByAlc" 9 "AutoLaneChngLLaneSts_9_LaneChangeManoeuvreWithRisk" 10 "AutoLaneChngLLaneSts_10_ReturnToEgoLaneSuccess" 11 "AutoLaneChngRLaneSts_11_WaitingForALCBecauseVehicleSpeedTooLow" 12 "AutoLaneChngRLaneSts_12_WaitingForALCBecauseVehicleSpeedTooHigh" 13 "AutoLaneChngRLaneSts_13_Vehiclegothroughthelane";
VAL_ 337 ESSSysSts 0 "ESSSysSts_0_Off" 1 "ESSSysSts_1_StandBy" 2 "ESSSysSts_2_Passive" 3 "ESSSysSts_3_Active" 4 "ESSSysSts_4_Disable" 5 "ESSSysSts_5_reserved" 6 "ESSSysSts_6_reserved";
VAL_ 337 ESSSysFltSts 0 "ESSSysFltSts_0_NoError" 1 "ESSSysFltSts_1_PerformanceDegradation" 2 "ESSSysFltSts_2_SystemTemporaryUnvailable" 3 "ESSSysFltSts_3_ServiceRequired" 4 "ESSSysFltSts_4_Reserved" 5 "ESSSysFltSts_5_Reserved" 6 "ESSSysFltSts_6_Reserved" 7 "ESSSysFltSts_7_Reserved";
VAL_ 337 ESSDrvrTkovReq 0 "ESSDrvrTkovReq_0_False" 1 "ESSDrvrTkovReq_1_True";
VAL_ 337 Parkngslottype 0 "ParkngSlotType_0__null" 1 "ParkngSlotType_1_left_vertical" 2 "ParkngSlotType_2_left_parallel" 3 "ParkngSlotType_3_right_vertical" 4 "ParkngSlotType_4_right_parallel";
VAL_ 337 NOPSysFltSts 0 "NOPSysFltSts_0_No_error" 1 "NOPSysFltSts_1_Performance_degradation" 2 "NOPSysFltSts_2_System_temporary_unavailable" 3 "NOPSysFltSts_3_Service_required" 4 "NOPSysFltSts_4_Reserved";
VAL_ 720 LADSInfoDispReq 0 "LADSInfoDispReq_0_NoRequest" 1 "LADSInfoDispReq_1_Reserved" 2 "LADSInfoDispReq_2_Vehicle_speed_is_too_high_APA_system_abort" 3 "LADSInfoDispReq_3_Vehicle_speed_is_too_high_please_be_slow_down" 4 "LADSInfoDispReq_4_Parking_slot_searching" 5 "LADSInfoDispReq_5_Parking_Exit" 6 "LADSInfoDispReq_6_Reserved" 7 "LADSInfoDispReq_7_Please_stop_the_car" 8 "LADSInfoDispReq_8_Reserved" 9 "LADSInfoDispReq_9_Parking_pause_please_confirm_in_APP" 10 "LADSInfoDispReq_10_Press_start_for_APA_vehicle_control_or_choose_RPA" 11 "LADSInfoDispReq_11_Parking_pause_please_confirm_safety" 12 "LADSInfoDispReq_12_EPB_operated_Parking_exit" 13 "LADSInfoDispReq_13_No_obstacle_park_out_by_yourself" 14 "LADSInfoDispReq_14_Please_press_start_park_out" 15 "LADSInfoDispReq_15_Parking_pause_please_press_continue" 16 "LADSInfoDispReq_16_Please_fasten_the_safety_belt" 17 "LADSInfoDispReq_17_Please_close_the_door" 18 "LADSInfoDispReq_18_LADS_unavailable_parking_exit" 19 "LADSInfoDispReq_19_19_Left_steering" 20 "LADSInfoDispReq_20_20_user_open_the_door_Learning_quite" 21 "LADSInfoDispReq_21_Reserved" 22 "LADSInfoDispReq_22_22_RPA_ready_Please_leave_the_car_and_use_app" 23 "LADSInfoDispReq_23_Reserved" 24 "LADSInfoDispReq_24_Reserved" 25 "LADSInfoDispReq_25_Reserved" 26 "LADSInfoDispReq_26_Reserved" 27 "LADSInfoDispReq_27_Reserved" 28 "LADSInfoDispReq_28_Reserved" 29 "LADSInfoDispReq_29_29_Right_steering" 30 "LADSInfoDispReq_30_30_Please_step_on_the_brake_and_press_the_SSB" 31 "LADSInfoDispReq_31_31_Brake_And_PressSSB_to_take_over_Vehicle_during_P2P_or_APA" 32 "LADSInfoDispReq_32_Reserved" 33 "LADSInfoDispReq_33_33_Barrier_exist_please_remove" 34 "LADSInfoDispReq_34_34_Steering_wheel_has_been_turned" 35 "LADSInfoDispReq_35_35_Accelerator_pressed" 36 "LADSInfoDispReq_36_Reserved" 37 "LADSInfoDispReq_37_37_Shift_operated" 38 "LADSInfoDispReq_38_38_Adjustment_time_exceeded" 39 "LADSInfoDispReq_39_39_Slope_too_big" 40 "LADSInfoDispReq_40_40_Disturbe_overtime" 41 "LADSInfoDispReq_41_41_Space_too_small" 42 "LADSInfoDispReq_42_Reserved" 43 "LADSInfoDispReq_43_Reserved" 44 "LADSInfoDispReq_44_44_Please_release_brake_and_pay_attention_to_surroundings_using_active_control_measure_if_necessary" 45 "LADSInfoDispReq_45_45_Parking_is_ongoing" 46 "LADSInfoDispReq_46_46_Parking_manoeuvre_has_completed__Please_take_over_vehicle" 47 "LADSInfoDispReq_47_Reserved" 48 "LADSInfoDispReq_48_48_System_overtime_APA_system_quit" 49 "LADSInfoDispReq_49_Reserved" 50 "LADSInfoDispReq_50_Reserved" 51 "LADSInfoDispReq_51_Reserved" 52 "LADSInfoDispReq_52_Reserved" 53 "LADSInfoDispReq_53_Reserved" 54 "LADSInfoDispReq_54_Reserved" 55 "LADSInfoDispReq_55_Reserved" 56 "LADSInfoDispReq_56_Reserved" 57 "LADSInfoDispReq_57_Reserved" 58 "LADSInfoDispReq_58_Reserved" 59 "LADSInfoDispReq_59_Reserved" 60 "LADSInfoDispReq_60_Reserved" 61 "LADSInfoDispReq_61_Reserved" 62 "LADSInfoDispReq_62_Reserved" 63 "LADSInfoDispReq_63_63_Environment_Changed" 64 "LADSInfoDispReq_64_Reserved" 65 "LADSInfoDispReq_65_65_Pleasestopthecarfirst" 66 "LADSInfoDispReq_66_66_PleaseshifttoPfirst" 67 "LADSInfoDispReq_67_67_PleaseapplytheEPBfirst" 68 "LADSInfoDispReq_68_68_Pleasestartthevehicle" 69 "LADSInfoDispReq_69_69_Please_unlock_the_vehicle" 70 "LADSInfoDispReq_70_70_Please_takeover" 71 "LADSInfoDispReq_71_Reserved" 72 "LADSInfoDispReq_72_Reserved" 73 "LADSInfoDispReq_73_Reserved" 74 "LADSInfoDispReq_74_Reserved" 75 "LADSInfoDispReq_75_Reserved" 76 "LADSInfoDispReq_76_Reserved" 77 "LADSInfoDispReq_77_Reserved" 78 "LADSInfoDispReq_78_Reserved" 79 "LADSInfoDispReq_79_Reserved" 80 "LADSInfoDispReq_80_Reserved" 81 "LADSInfoDispReq_81_Reserved" 82 "LADSInfoDispReq_82_Reserved" 83 "LADSInfoDispReq_83_Reserved" 84 "LADSInfoDispReq_84_Reserved" 85 "LADSInfoDispReq_85_Reserved" 86 "LADSInfoDispReq_86_Reserved" 87 "LADSInfoDispReq_87_Reserved" 88 "LADSInfoDispReq_88_Reserved" 89 "LADSInfoDispReq_89_Reserved" 90 "LADSInfoDispReq_90_Reserved" 91 "LADSInfoDispReq_91_Reserved" 92 "LADSInfoDispReq_92_Reserved" 93 "LADSInfoDispReq_93_Reserved" 94 "LADSInfoDispReq_94_Reserved" 95 "LADSInfoDispReq_95_Reserved" 96 "LADSInfoDispReq_96_Reserved" 97 "LADSInfoDispReq_97_97_Tire_pressure_abnormal" 98 "LADSInfoDispReq_98_98_Please_turn_off_the_engine_manually" 99 "LADSInfoDispReq_99_99_Please_lock_the_vehicle" 100 "LADSInfoDispReq_100_100_Long_time_not_operated" 101 "LADSInfoDispReq_101_Reserved" 102 "LADSInfoDispReq_102_102_HaParkingPausezard_start_error" 103 "LADSInfoDispReq_103_103_Unlock_failed" 104 "LADSInfoDispReq_104_104_SSB_pressed" 105 "LADSInfoDispReq_105_105_Bluetooth_inactive" 106 "LADSInfoDispReq_106_106_Has_changed_to_normal_drive_mode" 107 "LADSInfoDispReq_107_ACC_actived_LADS_exit" 108 "LADSInfoDispReq_108_AEB_actived_LADS_exit" 109 "LADSInfoDispReq_109_109_TJA_actived_LADS_exit" 110 "LADSInfoDispReq_110_110_Lockedthecar" 111 "LADSInfoDispReq_111_111_NotchooseRPA" 112 "LADSInfoDispReq_112_Reserved" 113 "LADSInfoDispReq_113_113_Vehicle_does_not_stop" 114 "LADSInfoDispReq_114_114_Barrier_in_slot_change_another" 115 "LADSInfoDispReq_115_Reserved" 116 "LADSInfoDispReq_116_Reserved" 117 "LADSInfoDispReq_117_Reserved" 118 "LADSInfoDispReq_118_Reserved" 119 "LADSInfoDispReq_119_Reserved" 120 "LADSInfoDispReq_120_Reserved" 121 "LADSInfoDispReq_121_Reserved" 122 "LADSInfoDispReq_122_Reserved" 123 "LADSInfoDispReq_123_Reserved" 124 "LADSInfoDispReq_124_Reserved" 125 "LADSInfoDispReq_125_Reserved" 126 "LADSInfoDispReq_126_Reserved" 127 "LADSInfoDispReq_127_Reserved" 128 "LADSInfoDispReq_128_128_Please_press_the_brake_padel_vehicle_control_has_not_started" 129 "LADSInfoDispReq_129_129_Parking_pause_please_press_the_button" 130 "LADSInfoDispReq_130_130_Detecting_if_the_slot_space_is_enough" 131 "LADSInfoDispReq_131_131_Please_exit_current_function_then_press_parkin" 132 "LADSInfoDispReq_132_Reserved" 133 "LADSInfoDispReq_133_Reserved" 134 "LADSInfoDispReq_134_Reserved" 135 "LADSInfoDispReq_135_Reserved" 136 "LADSInfoDispReq_136_Reserved" 137 "LADSInfoDispReq_137_Reserved" 138 "LADSInfoDispReq_138_Reserved" 139 "LADSInfoDispReq_139_Reserved" 140 "LADSInfoDispReq_140_Reserved" 141 "LADSInfoDispReq_141_Reserved" 142 "LADSInfoDispReq_142_Reserved" 143 "LADSInfoDispReq_143_Reserved" 144 "LADSInfoDispReq_144_Reserved" 145 "LADSInfoDispReq_145_Reserved" 146 "LADSInfoDispReq_146_146_Systemselfchecking" 147 "LADSInfoDispReq_147_Reserved" 148 "LADSInfoDispReq_148_Reserved" 149 "LADSInfoDispReq_149_149_Parking_pause_please_press_continue_in_APP" 150 "LADSInfoDispReq_150_150_Please_select_parkout_direction_in_ICM" 151 "LADSInfoDispReq_151_Reserved" 152 "LADSInfoDispReq_152_Reserved" 153 "LADSInfoDispReq_153_Reserved" 154 "LADSInfoDispReq_154_Reserved" 155 "LADSInfoDispReq_155_Reserved" 156 "LADSInfoDispReq_156_Reserved" 157 "LADSInfoDispReq_157_Reserved" 158 "LADSInfoDispReq_158_Reserved" 159 "LADSInfoDispReq_159_Reserved" 160 "LADSInfoDispReq_160_160_Engine_is_not_ready" 161 "LADSInfoDispReq_161_161_LADS_faultcannot_open" 162 "LADSInfoDispReq_162_162_LADS_busy_cannot_open" 163 "LADSInfoDispReq_163_163_Speed_is_too_high_cannot_open" 164 "LADSInfoDispReq_164_164_Vehicle_is_not_stop_cannot_open" 165 "LADSInfoDispReq_165_165_ADAS_is_actived" 166 "LADSInfoDispReq_166_166_waiting_for_key_off_and_lock" 167 "LADSInfoDispReq_167_167_Route_Learning_Start" 168 "LADSInfoDispReq_168_168_Route_learning_is_exit_Press_to_save_route" 169 "LADSInfoDispReq_169_169_Route_learning_is_over_time_Press_to_save_route" 170 "LADSInfoDispReq_170_170_Route_Learning_is_ongoing" 171 "LADSInfoDispReq_171_171_Stop_and_shift_to_P_if_want_to_finish_Leaning" 172 "LADSInfoDispReq_172_172_shift_to_P_if_want_to_finish_Leaning" 173 "LADSInfoDispReq_173_173_Route_learning_will_over_distance" 174 "LADSInfoDispReq_174_174_Select_Saving_Route" 175 "LADSInfoDispReq_175_175_stop_too_long_timesystem_exit" 176 "LADSInfoDispReq_176_176_Learning_over_distancesystem_exit" 177 "LADSInfoDispReq_177_177_shift_gear_over_timessystem_exit" 178 "LADSInfoDispReq_178_178_Route_too_complex_system_exit" 179 "LADSInfoDispReq_179_179_During_Route_Matching" 180 "LADSInfoDispReq_180_180_Route_Matched_Please_stop_car" 181 "LADSInfoDispReq_181_181_Route_Matched_Please_keep_stopping" 182 "LADSInfoDispReq_182_182_Route_Matching_Failedsystem_exit" 183 "LADSInfoDispReq_183_183_Route_FaultMatching_again" 184 "LADSInfoDispReq_184_184_Map_Loading_Failed" 185 "LADSInfoDispReq_185_185_Not_In_P_gearsystem_exit" 186 "LADSInfoDispReq_186_186_EPB_is_not_operated_system_exit" 187 "LADSInfoDispReq_187_187_Route_Delete_succeeded" 188 "LADSInfoDispReq_188_188_Route_Delete_Failedsystem_exit" 189 "LADSInfoDispReq_189_189_Not_supported_this_Route" 190 "LADSInfoDispReq_190_190_Environment_is_not_OK_for_Learning" 191 "LADSInfoDispReq_191_191_Route_is_SavingPlease_wait" 192 "LADSInfoDispReq_192_192_Please_select_park_route" 193 "LADSInfoDispReq_193_193_Route_Saving_succeeded" 194 "LADSInfoDispReq_194_194_Route_Saving_FailedSystem_exit" 195 "LADSInfoDispReq_195_195_Please_do_not_touch_the_steering_wheel" 196 "LADSInfoDispReq_196_196_Press_start_for_Route_Reply_vehicle_control_or_choose_APP" 197 "LADSInfoDispReq_197_197_Route_Reply_Ongoing" 198 "LADSInfoDispReq_198_198_Please_select_parking_slot" 199 "LADSInfoDispReq_199_199_Press_start_for_Parking_vehicle_control" 200 "LADSInfoDispReq_200_200_Please_select_route_to_replace" 201 "LADSInfoDispReq_201_201_Please_Press_to_Start_Route_Reply" 202 "LADSInfoDispReq_202_202_System_control_exit_press_button_to_continute_learning_by_driver" 203 "LADSInfoDispReq_203_203_Finial_slot_not_available_Please_select_other_slot" 204 "LADSInfoDispReq_204_204_Route_learning_Failed" 205 "LADSInfoDispReq_205_205_Route_Reply_Completed" 206 "LADSInfoDispReq_206_206_Route_learning_press_stop_button_to_finsih_learning" 207 "LADSInfoDispReq_207_207_Please_select_route" 208 "LADSInfoDispReq_208_208_Route_learning_will_over_time" 209 "LADSInfoDispReq_209_209_Route_Unavailable" 210 "LADSInfoDispReq_210_210_Not_In_R_gear" 211 "LADSInfoDispReq_211_211_ARA_Ongoing" 212 "LADSInfoDispReq_212_212_ARA_Completed" 213 "LADSInfoDispReq_213_213_Please_press_the_brake_padel_for_vehicle_control_hand_shake" 214 "LADSInfoDispReq_214_214_No_P2P_Route" 215 "LADSInfoDispReq_215_215_System_control_exit_press_button_to_save_route" 216 "LADSInfoDispReq_216_216_System_Loading_please_wait" 217 "LADSInfoDispReq_217_217_No_GPS_system_function_exited" 218 "LADSInfoDispReq_218_218_No_GPSl_please_drive_to_open_area" 219 "LADSInfoDispReq_219_219_Remote_parking_completed_the_destination_is_not_a_storage_location" 220 "LADSInfoDispReq_220_220_Obstacle_avoidance_routes_during_vehicle_control" 221 "LADSInfoDispReq_221_221_Insufficient_environmental_information_not_supporting_P2P" 222 "LADSInfoDispReq_222_222_The_vehicle_passes_through_a_toll_pole_and_does_not_support_route_learning" 223 "LADSInfoDispReq_223_223_Long_time_without_passing_through_the_parking_area_not_supporting_route_learning" 224 "LADSInfoDispReq_224_224_Obstacle_avoidance_risk_is_high_and_requires_user_confirmation" 225 "LADSInfoDispReq_225_225_During_the_matching_process_the_vehicle_leaves_the_geofence" 226 "LADSInfoDispReq_226_226_When_the_steering_wheel_angle_is_too_large_during_the_learning_process" 227 "LADSInfoDispReq_227_227_The_learning_route_is_too_short_to_save" 228 "LADSInfoDispReq_228_228_When_the_P2P4G_parking_function_is_enabled_the_user_clicks_on_the_relevant_parking_function_on_the_large_screen" 229 "LADSInfoDispReq_229_229_SilentSelect_parking_slot" 230 "LADSInfoDispReq_230_230_Temporary_system_malfunction" 231 "LADSInfoDispReq_231_231_Camera_occlusion_affecting_P2P_functionality" 232 "LADSInfoDispReq_232_232_During_the_playback_process_the_user_intervenes_with_the_actuator_and_the_system_re_plans_the_route_based_on_the_current_position_of_the_vehicle" 233 "LADSInfoDispReq_233_233_During_the_playback_process_the_self_owned_vehicle_intelligently_gives_way_to_other_vehicles" 234 "LADSInfoDispReq_234_234_The_environment_is_too_dark_affecting_perception_accuracy" 235 "LADSInfoDispReq_235_235_Remind_users_at_the_beginning_of_route_learning" 236 "LADSInfoDispReq_236_236_Detect_deceleration_of_vehicles_with_obstacles";
VAL_ 720 LADSInfoDispReqToICM 0 "LADSInfoDispReqToICM_0_0_NoRequest" 1 "LADSInfoDispReqToICM_1_Reserved" 2 "LADSInfoDispReqToICM_2_2_Vehicle_speed_is_too_high_APA_system_abort" 3 "LADSInfoDispReqToICM_3_3_Vehicle_speed_is_too_high_please_be_slow_down" 4 "LADSInfoDispReqToICM_4_4_Parking_slot_searching" 5 "LADSInfoDispReqToICM_5_5_Parking_Exit" 6 "LADSInfoDispReqToICM_6_Reserved" 7 "LADSInfoDispReqToICM_7_7_Please_stop_the_car" 8 "LADSInfoDispReqToICM_8_Reserved" 9 "LADSInfoDispReqToICM_9_9_Parking_pause_please_confirm_in_APP" 10 "LADSInfoDispReqToICM_10_10_Press_start_for_APA_vehicle_control_or_choose_RPA" 11 "LADSInfoDispReqToICM_11_11_Parking_pause_please_confirm_safety" 12 "LADSInfoDispReqToICM_12_12_EPB_operated_Parking_exit" 13 "LADSInfoDispReqToICM_13_13_No_obstacle_park_out_by_yourself" 14 "LADSInfoDispReqToICM_14_14_Please_press_start_park_out" 15 "LADSInfoDispReqToICM_15_15_Parking_pause_please_press_continue" 16 "LADSInfoDispReqToICM_16_16_Please_fasten_the_safety_belt" 17 "LADSInfoDispReqToICM_17_17_Please_close_the_door" 18 "LADSInfoDispReqToICM_18_18_LADS_unavailable_parking_exit" 19 "LADSInfoDispReqToICM_19_19_Left_steering" 20 "LADSInfoDispReqToICM_20_20_user_open_the_door_Learning_quite" 21 "LADSInfoDispReqToICM_21_Reserved" 22 "LADSInfoDispReqToICM_22_22_RPA_ready_Please_leave_the_car_and_use_app" 23 "LADSInfoDispReqToICM_23_Reserved" 24 "LADSInfoDispReqToICM_24_Reserved" 25 "LADSInfoDispReqToICM_25_Reserved" 26 "LADSInfoDispReqToICM_26_Reserved" 27 "LADSInfoDispReqToICM_27_Reserved" 28 "LADSInfoDispReqToICM_28_Reserved" 29 "LADSInfoDispReqToICM_29_29_Right_steering" 30 "LADSInfoDispReqToICM_30_30_Please_step_on_the_brake_and_press_the_SSB" 31 "LADSInfoDispReqToICM_31_31_Brake_And_PressSSB_to_take_over_Vehicle_during_P2P_or_APA" 32 "LADSInfoDispReqToICM_32_Reserved" 33 "LADSInfoDispReqToICM_33_33_Barrier_exist_please_remove" 34 "LADSInfoDispReqToICM_34_34_Steering_wheel_has_been_turned" 35 "LADSInfoDispReqToICM_35_35_Accelerator_pressed" 36 "LADSInfoDispReqToICM_36_Reserved" 37 "LADSInfoDispReqToICM_37_37_Shift_operated" 38 "LADSInfoDispReqToICM_38_38_Adjustment_time_exceeded" 39 "LADSInfoDispReqToICM_39_39_Slope_too_big" 40 "LADSInfoDispReqToICM_40_40_Disturbe_overtime" 41 "LADSInfoDispReqToICM_41_41_Space_too_small" 42 "LADSInfoDispReqToICM_42_Reserved" 43 "LADSInfoDispReqToICM_43_Reserved" 44 "LADSInfoDispReqToICM_44_44_Please_release_brake_and_pay_attention_to_surroundings_using_active_control_measure_if_necessary" 45 "LADSInfoDispReqToICM_45_45_Parking_is_ongoing" 46 "LADSInfoDispReqToICM_46_46_Parking_manoeuvre_has_completed__Please_take_over_vehicle" 47 "LADSInfoDispReqToICM_47_Reserved" 48 "LADSInfoDispReqToICM_48_48_System_overtime_APA_system_quit" 49 "LADSInfoDispReqToICM_49_Reserved" 50 "LADSInfoDispReqToICM_50_Reserved" 51 "LADSInfoDispReqToICM_51_Reserved" 52 "LADSInfoDispReqToICM_52_Reserved" 53 "LADSInfoDispReqToICM_53_Reserved" 54 "LADSInfoDispReqToICM_54_Reserved" 55 "LADSInfoDispReqToICM_55_Reserved" 56 "LADSInfoDispReqToICM_56_Reserved" 57 "LADSInfoDispReqToICM_57_Reserved" 58 "LADSInfoDispReqToICM_58_Reserved" 59 "LADSInfoDispReqToICM_59_Reserved" 60 "LADSInfoDispReqToICM_60_Reserved" 61 "LADSInfoDispReqToICM_61_Reserved" 62 "LADSInfoDispReqToICM_62_Reserved" 63 "LADSInfoDispReqToICM_63_63_Environment_Changed" 64 "LADSInfoDispReqToICM_64_Reserved" 65 "LADSInfoDispReqToICM_65_65_Pleasestopthecarfirst" 66 "LADSInfoDispReqToICM_66_66_PleaseshifttoPfirst" 67 "LADSInfoDispReqToICM_67_67_PleaseapplytheEPBfirst" 68 "LADSInfoDispReqToICM_68_68_Pleasestartthevehicle" 69 "LADSInfoDispReqToICM_69_69_Please_unlock_the_vehicle" 70 "LADSInfoDispReqToICM_70_70_Please_takeover" 71 "LADSInfoDispReqToICM_71_Reserved" 72 "LADSInfoDispReqToICM_72_Reserved" 73 "LADSInfoDispReqToICM_73_Reserved" 74 "LADSInfoDispReqToICM_74_Reserved" 75 "LADSInfoDispReqToICM_75_Reserved" 76 "LADSInfoDispReqToICM_76_Reserved" 77 "LADSInfoDispReqToICM_77_Reserved" 78 "LADSInfoDispReqToICM_78_Reserved" 79 "LADSInfoDispReqToICM_79_Reserved" 80 "LADSInfoDispReqToICM_80_Reserved" 81 "LADSInfoDispReqToICM_81_Reserved" 82 "LADSInfoDispReqToICM_82_Reserved" 83 "LADSInfoDispReqToICM_83_Reserved" 84 "LADSInfoDispReqToICM_84_Reserved" 85 "LADSInfoDispReqToICM_85_Reserved" 86 "LADSInfoDispReqToICM_86_Reserved" 87 "LADSInfoDispReqToICM_87_Reserved" 88 "LADSInfoDispReqToICM_88_Reserved" 89 "LADSInfoDispReqToICM_89_Reserved" 90 "LADSInfoDispReqToICM_90_Reserved" 91 "LADSInfoDispReqToICM_91_Reserved" 92 "LADSInfoDispReqToICM_92_Reserved" 93 "LADSInfoDispReqToICM_93_Reserved" 94 "LADSInfoDispReqToICM_94_Reserved" 95 "LADSInfoDispReqToICM_95_Reserved" 96 "LADSInfoDispReqToICM_96_Reserved" 97 "LADSInfoDispReqToICM_97_97_Tire_pressure_abnormal" 98 "LADSInfoDispReqToICM_98_98_Please_turn_off_the_engine_manually" 99 "LADSInfoDispReqToICM_99_99_Please_lock_the_vehicle" 100 "LADSInfoDispReqToICM_100_100_Long_time_not_operated" 101 "LADSInfoDispReqToICM_101_Reserved" 102 "LADSInfoDispReqToICM_102_102_HaParkingPausezard_start_error" 103 "LADSInfoDispReqToICM_103_103_Unlock_failed" 104 "LADSInfoDispReqToICM_104_104_SSB_pressed" 105 "LADSInfoDispReqToICM_105_105_Bluetooth_inactive" 106 "LADSInfoDispReqToICM_106_106_Has_changed_to_normal_drive_mode" 107 "LADSInfoDispReqToICM_107_ACC_actived_LADS_exit" 108 "LADSInfoDispReqToICM_108_AEB_actived_LADS_exit" 109 "LADSInfoDispReqToICM_109_109_TJA_actived_LADS_exit" 110 "LADSInfoDispReqToICM_110_110_Lockedthecar" 111 "LADSInfoDispReqToICM_111_111_NotchooseRPA" 112 "LADSInfoDispReqToICM_112_Reserved" 113 "LADSInfoDispReqToICM_113_113_Vehicle_does_not_stop" 114 "LADSInfoDispReqToICM_114_114_Barrier_in_slot_change_another" 115 "LADSInfoDispReqToICM_115_Reserved" 116 "LADSInfoDispReqToICM_116_Reserved" 117 "LADSInfoDispReqToICM_117_Reserved" 118 "LADSInfoDispReqToICM_118_Reserved" 119 "LADSInfoDispReqToICM_119_Reserved" 120 "LADSInfoDispReqToICM_120_Reserved" 121 "LADSInfoDispReqToICM_121_Reserved" 122 "LADSInfoDispReqToICM_122_Reserved" 123 "LADSInfoDispReqToICM_123_Reserved" 124 "LADSInfoDispReqToICM_124_Reserved" 125 "LADSInfoDispReqToICM_125_Reserved" 126 "LADSInfoDispReqToICM_126_Reserved" 127 "LADSInfoDispReqToICM_127_Reserved" 128 "LADSInfoDispReqToICM_128_128_Please_press_the_brake_padel_vehicle_control_has_not_started" 129 "LADSInfoDispReqToICM_129_129_Parking_pause_please_press_the_button" 130 "LADSInfoDispReqToICM_130_130_Detecting_if_the_slot_space_is_enough" 131 "LADSInfoDispReqToICM_131_131_Please_exit_current_function_then_press_parkin" 132 "LADSInfoDispReqToICM_132_Reserved" 133 "LADSInfoDispReqToICM_133_Reserved" 134 "LADSInfoDispReqToICM_134_Reserved" 135 "LADSInfoDispReqToICM_135_Reserved" 136 "LADSInfoDispReqToICM_136_Reserved" 137 "LADSInfoDispReqToICM_137_Reserved" 138 "LADSInfoDispReqToICM_138_Reserved" 139 "LADSInfoDispReqToICM_139_Reserved" 140 "LADSInfoDispReqToICM_140_Reserved" 141 "LADSInfoDispReqToICM_141_Reserved" 142 "LADSInfoDispReqToICM_142_Reserved" 143 "LADSInfoDispReqToICM_143_Reserved" 144 "LADSInfoDispReqToICM_144_Reserved" 145 "LADSInfoDispReqToICM_145_Reserved" 146 "LADSInfoDispReqToICM_146_146_Systemselfchecking" 147 "LADSInfoDispReqToICM_147_Reserved" 148 "LADSInfoDispReqToICM_148_Reserved" 149 "LADSInfoDispReqToICM_149_149_Parking_pause_please_press_continue_in_APP" 150 "LADSInfoDispReqToICM_150_150_Please_select_parkout_direction_in_ICM" 151 "LADSInfoDispReqToICM_151_Reserved" 152 "LADSInfoDispReqToICM_152_Reserved" 153 "LADSInfoDispReqToICM_153_Reserved" 154 "LADSInfoDispReqToICM_154_Reserved" 155 "LADSInfoDispReqToICM_155_Reserved" 156 "LADSInfoDispReqToICM_156_Reserved" 157 "LADSInfoDispReqToICM_157_Reserved" 158 "LADSInfoDispReqToICM_158_Reserved" 159 "LADSInfoDispReqToICM_159_Reserved" 160 "LADSInfoDispReqToICM_160_160_Engine_is_not_ready" 161 "LADSInfoDispReqToICM_161_161_LADS_faultcannot_open" 162 "LADSInfoDispReqToICM_162_162_LADS_busy_cannot_open" 163 "LADSInfoDispReqToICM_163_163_Speed_is_too_high_cannot_open" 164 "LADSInfoDispReqToICM_164_164_Vehicle_is_not_stop_cannot_open" 165 "LADSInfoDispReqToICM_165_165_ADAS_is_actived" 166 "LADSInfoDispReqToICM_166_166_waiting_for_key_off_and_lock" 167 "LADSInfoDispReqToICM_167_167_Route_Learning_Start" 168 "LADSInfoDispReqToICM_168_168_Route_learning_is_exit_Press_to_save_route" 169 "LADSInfoDispReqToICM_169_169_Route_learning_is_over_time_Press_to_save_route" 170 "LADSInfoDispReqToICM_170_170_Route_Learning_is_ongoing" 171 "LADSInfoDispReqToICM_171_171_Stop_and_shift_to_P_if_want_to_finish_Leaning" 172 "LADSInfoDispReqToICM_172_172_shift_to_P_if_want_to_finish_Leaning" 173 "LADSInfoDispReqToICM_173_173_Route_learning_will_over_distance" 174 "LADSInfoDispReqToICM_174_174_Select_Saving_Route" 175 "LADSInfoDispReqToICM_175_175_stop_too_long_timesystem_exit" 176 "LADSInfoDispReqToICM_176_176_Learning_over_distancesystem_exit" 177 "LADSInfoDispReqToICM_177_177_shift_gear_over_timessystem_exit" 178 "LADSInfoDispReqToICM_178_178_Route_too_complex_system_exit" 179 "LADSInfoDispReqToICM_179_179_During_Route_Matching" 180 "LADSInfoDispReqToICM_180_180_Route_Matched_Please_stop_car" 181 "LADSInfoDispReqToICM_181_181_Route_Matched_Please_keep_stopping" 182 "LADSInfoDispReqToICM_182_182_Route_Matching_Failedsystem_exit" 183 "LADSInfoDispReqToICM_183_183_Route_FaultMatching_again" 184 "LADSInfoDispReqToICM_184_184_Map_Loading_Failed" 185 "LADSInfoDispReqToICM_185_185_Not_In_P_gearsystem_exit" 186 "LADSInfoDispReqToICM_186_186_EPB_is_not_operated_system_exit" 187 "LADSInfoDispReqToICM_187_187_Route_Delete_succeeded" 188 "LADSInfoDispReqToICM_188_188_Route_Delete_Failedsystem_exit" 189 "LADSInfoDispReqToICM_189_189_Not_supported_this_Route" 190 "LADSInfoDispReqToICM_190_190_Environment_is_not_OK_for_Learning" 191 "LADSInfoDispReqToICM_191_191_Route_is_SavingPlease_wait" 192 "LADSInfoDispReqToICM_192_192_Please_select_park_route" 193 "LADSInfoDispReqToICM_193_193_Route_Saving_succeeded" 194 "LADSInfoDispReqToICM_194_194_Route_Saving_FailedSystem_exit" 195 "LADSInfoDispReqToICM_195_195_Please_do_not_touch_the_steering_wheel" 196 "LADSInfoDispReqToICM_196_196_Press_start_for_Route_Reply_vehicle_control_or_choose_APP" 197 "LADSInfoDispReqToICM_197_197_Route_Reply_Ongoing" 198 "LADSInfoDispReqToICM_198_198_Please_select_parking_slot" 199 "LADSInfoDispReqToICM_199_199_Press_start_for_Parking_vehicle_control" 200 "LADSInfoDispReqToICM_200_200_Please_select_route_to_replace" 201 "LADSInfoDispReqToICM_201_201_Please_Press_to_Start_Route_Reply" 202 "LADSInfoDispReqToICM_202_202_System_control_exit_press_button_to_continute_learning_by_driver" 203 "LADSInfoDispReqToICM_203_203_Finial_slot_not_available_Please_select_other_slot" 204 "LADSInfoDispReqToICM_204_204_Route_learning_Failed" 205 "LADSInfoDispReqToICM_205_205_Route_Reply_Completed" 206 "LADSInfoDispReqToICM_206_206_Route_learning_press_stop_button_to_finsih_learning" 207 "LADSInfoDispReqToICM_207_207_Please_select_route" 208 "LADSInfoDispReqToICM_208_208_Route_learning_will_over_time" 209 "LADSInfoDispReqToICM_209_209_Route_Unavailable" 210 "LADSInfoDispReqToICM_210_210_Not_In_R_gear" 211 "LADSInfoDispReqToICM_211_211_ARA_Ongoing" 212 "LADSInfoDispReqToICM_212_212_ARA_Completed" 213 "LADSInfoDispReqToICM_213_213_Please_press_the_brake_padel_for_vehicle_control_hand_shake" 214 "LADSInfoDispReqToICM_214_214_No_P2P_Route" 215 "LADSInfoDispReqToICM_215_215_System_control_exit_press_button_to_save_route" 216 "LADSInfoDispReqToICM_216_216_System_Loading_please_wait" 217 "LADSInfoDispReqToICM_217_217_No_GPS_system_function_exited" 218 "LADSInfoDispReqToICM_218_218_No_GPSl_please_drive_to_open_area" 219 "LADSInfoDispReqToICM_219_219_Remote_parking_completed_the_destination_is_not_a_storage_location" 220 "LADSInfoDispReqToICM_220_220_Obstacle_avoidance_routes_during_vehicle_control" 221 "LADSInfoDispReqToICM_221_221_Insufficient_environmental_information_not_supporting_P2P" 222 "LADSInfoDispReqToICM_222_222_The_vehicle_passes_through_a_toll_pole_and_does_not_support_route_learning" 223 "LADSInfoDispReqToICM_223_223_Long_time_without_passing_through_the_parking_area_not_supporting_route_learning" 224 "LADSInfoDispReqToICM_224_224_Obstacle_avoidance_risk_is_high_and_requires_user_confirmation" 225 "LADSInfoDispReqToICM_225_225_During_the_matching_process_the_vehicle_leaves_the_geofence" 226 "LADSInfoDispReqToICM_226_226_When_the_steering_wheel_angle_is_too_large_during_the_learning_process" 227 "LADSInfoDispReqToICM_227_227_The_learning_route_is_too_short_to_save" 228 "LADSInfoDispReqToICM_228_228_When_the_P2P_4G_parking_function_is_enabled_the_user_clicks_on_the_relevant_parking_function_on_the_large_screen" 229 "LADSInfoDispReqToICM_229_229_SilentSelect_parking_slot" 230 "LADSInfoDispReqToICM_230_230_Temporary_system_malfunction" 231 "LADSInfoDispReqToICM_231_231_Camera_occlusion_affecting_P2P_functionality" 232 "LADSInfoDispReqToICM_232_232_During_the_playback_process_the_user_intervenes_with_the_actuator_and_the_system_re_plans_the_route_based_on_the_current_position_of_the_vehicle" 233 "LADSInfoDispReqToICM_233_233_During_the_playback_process_the_self_owned_vehicle_intelligently_gives_way_to_other_vehicles" 234 "LADSInfoDispReqToICM_234_234_The_environment_is_too_dark_affecting_perception_accuracy" 235 "LADSInfoDispReqToICM_235_235_Remind_users_at_the_beginning_of_route_learning" 236 "LADSInfoDispReqToICM_236_236_Detect_deceleration_of_vehicles_with_obstacles";
VAL_ 720 SDWLSRObsRng 0 "SDWLSRObsRng_0_NoObstacle" 1 "SDWLSRObsRng_1_Range1" 2 "SDWLSRObsRng_2_Range2" 3 "SDWLSRObsRng_3_Range3" 4 "SDWLSRObsRng_4_Range4" 5 "SDWLSRObsRng_5_Range5" 6 "SDWLSRObsRng_6_Range6" 7 "SDWLSRObsRng_7_Range7" 8 "SDWLSRObsRng_8_Range8" 9 "SDWLSRObsRng_9_Range9" 10 "SDWLSRObsRng_10_Range10" 11 "SDWLSRObsRng_11_Range11" 12 "SDWLSRObsRng_12_Range12" 13 "SDWLSRObsRng_13_Range13" 14 "SDWLSRObsRng_14_Range14" 15 "SDWLSRObsRng_15_Range15";
VAL_ 720 SDWLSFObsRng 0 "SDWLSFObsRng_0_NoObstacle" 1 "SDWLSFObsRng_1_Range1" 2 "SDWLSFObsRng_2_Range2" 3 "SDWLSFObsRng_3_Range3" 4 "SDWLSFObsRng_4_Range4" 5 "SDWLSFObsRng_5_Range5" 6 "SDWLSFObsRng_6_Range6" 7 "SDWLSFObsRng_7_Range7" 8 "SDWLSFObsRng_8_Range8" 9 "SDWLSFObsRng_9_Range9" 10 "SDWLSFObsRng_10_Range10" 11 "SDWLSFObsRng_11_Range11" 12 "SDWLSFObsRng_12_Range12" 13 "SDWLSFObsRng_13_Range13" 14 "SDWLSFObsRng_14_Range14" 15 "SDWLSFObsRng_15_Range15";
VAL_ 720 SDWRSRObsRng 0 "SDWRSRObsRng_0_NoObstacle" 1 "SDWRSRObsRng_1_Range1" 2 "SDWRSRObsRng_2_Range2" 3 "SDWRSRObsRng_3_Range3" 4 "SDWRSRObsRng_4_Range4" 5 "SDWRSRObsRng_5_Range5" 6 "SDWRSRObsRng_6_Range6" 7 "SDWRSRObsRng_7_Range7" 8 "SDWRSRObsRng_8_Range8" 9 "SDWRSRObsRng_9_Range9" 10 "SDWRSRObsRng_10_Range10" 11 "SDWRSRObsRng_11_Range11" 12 "SDWRSRObsRng_12_Range12" 13 "SDWRSRObsRng_13_Range13" 14 "SDWRSRObsRng_14_Range14" 15 "SDWRSRObsRng_15_Range15";
VAL_ 720 SDWRSFObsRng 0 "SDWRSFObsRng_0_NoObstacle" 1 "SDWRSFObsRng_1_Range1" 2 "SDWRSFObsRng_2_Range2" 3 "SDWRSFObsRng_3_Range3" 4 "SDWRSFObsRng_4_Range4" 5 "SDWRSFObsRng_5_Range5" 6 "SDWRSFObsRng_6_Range6" 7 "SDWRSFObsRng_7_Range7" 8 "SDWRSFObsRng_8_Range8" 9 "SDWRSFObsRng_9_Range9" 10 "SDWRSFObsRng_10_Range10" 11 "SDWRSFObsRng_11_Range11" 12 "SDWRSFObsRng_12_Range12" 13 "SDWRSFObsRng_13_Range13" 14 "SDWRSFObsRng_14_Range14" 15 "SDWRSFObsRng_15_Range15";
VAL_ 733 KeepPwrRsnIPD 0 "KeepPwrRsnIPD_0_Unknown" 1 "KeepPwrRsnIPD_1_Off" 2 "KeepPwrRsnIPD_2_On" 3 "KeepPwrRsnIPD_3__LPM_SnsrOff" 4 "KeepPwrRsnIPD_4_SnsrOff" 5 "KeepPwrRsnIPD_5_Reserved" 6 "KeepPwrRsnIPD_6_Reserved" 7 "KeepPwrRsnIPD_7_Reserved" 8 "KeepPwrRsnIPD_8_Reserved" 9 "KeepPwrRsnIPD_9_GoingDown" 10 "KeepPwrRsnIPD_10_off_SuperECO" 11 "KeepPwrRsnIPD_11_Reserved" 12 "KeepPwrRsnIPD_12_Reserved" 13 "KeepPwrRsnIPD_13_Reserved" 14 "KeepPwrRsnIPD_14_Reserved" 15 "KeepPwrRsnIPD_15_Reserved";
VAL_ 733 SysPwrMdCtrl 0 "SysPwrMdCtrl_0_NoRequest" 1 "SysPwrMdCtrl_1_Accessory" 2 "SysPwrMdCtrl_2_Run" 3 "SysPwrMdCtrl_3_Crank_Request" 4 "SysPwrMdCtrl_4_Change_to_normal_mode" 5 "SysPwrMdCtrl_5_Change_to_AD_mode" 6 "SysPwrMdCtrl_6_OFF";
VAL_ 733 APAEnRunReq 0 "APAEnRunReq_0_No_request" 1 "APAEnRunReq_1_Request";
VAL_ 733 LADSAFnInd 0 "LADSAFnInd_0_IDLE" 1 "LADSAFnInd_1_RADS" 2 "LADSAFnInd_2_ESSSwap_Park" 3 "LADSAFnInd_3_NPA" 4 "LADSAFnInd_4_AVP" 5 "LADSAFnInd_5_Remember_Build_Map" 6 "LADSAFnInd_6_Remember_Summon" 7 "LADSAFnInd_7_Remember_ParkIn" 8 "LADSAFnInd_8_RemoteOnekeyParkIn_Super" 9 "LADSAFnInd_9_ParkIn_super" 10 "LADSAFnInd_10_ParkIn" 11 "LADSAFnInd_11_ParkOut" 12 "LADSAFnInd_12_NRCD" 13 "LADSAFnInd_13_RemoteOnekeyParkIn" 14 "LADSAFnInd_14_RemoteOnekeyParkOut" 15 "LADSAFnInd_15_NCP";
VAL_ 1143 SyncMsgType 32 "SyncMsgType_32_TSync" 40 "SyncMsgType_40_TSync_FUP";
VAL_ 1143 SyncMsgSGW 0 "SyncMsgSGW_0_SyncToGTM" 1 "SyncMsgSGW_1_SyncToSubDomain";
VAL_ 1526 IPDComKeyEnbResp 0 "IPDComKeyEnbResp_0_Failed" 1 "IPDComKeyEnbResp_1_Success";
VAL_ 1526 AIParkngRespICB 1 "AIParkngRespICB_1_Start_Parking_in" 2 "AIParkngRespICB_2_Start_Parking_out" 3 "AIParkngRespICB_3_Pause" 4 "AIParkngRespICB_4_Continue" 5 "AIParkngRespICB_5_Cancel" 6 "AIParkngRespICB_6_Back_XEquals1" 7 "AIParkngRespICB_7_Left_Parking_out" 8 "AIParkngRespICB_8_Right_Parking_out" 9 "AIParkngRespICB_9_Fast_Parking" 10 "AIParkngRespICB_10_Line_out_System_Start" 11 "AIParkngRespICB_11_Line_back_System_Start" 12 "AIParkngRespICB_12_Call_to_Position_X" 13 "AIParkngRespICB_13_StartParkingScanningManualDriving_XEquals1" 14 "AIParkngRespICB_14_Remote_turn_left_XEquals8" 15 "AIParkngRespICB_15_Remote_turn_right_XEquals8" 16 "AIParkngRespICB_16_RememberBuildMap" 17 "AIParkngRespICB_17_Remember_Park_In" 18 "AIParkngRespICB_18_Remember_Summon" 19 "AIParkngRespICB_19_Start_Remember_Parking" 20 "AIParkngRespICB_20_Keep_Going_Forword" 21 "AIParkngRespICB_21_Keep_Going_Back" 22 "AIParkngRespICB_22_Start_AVP_in" 23 "AIParkngRespICB_23_Start_AVP_out" 24 "AIParkngRespICB_24_Back_Left_Parking_out" 25 "AIParkngRespICB_25_Back_Right_Parking_out" 32 "AIParkngRespICB_32_choose_left_direction_XEquals1" 33 "AIParkngRespICB_33_choose_right_direction_XEquals1" 34 "AIParkngRespICB_34_ReverseParkingInRecordingParking_XEquals1" 35 "AIParkngRespICB_35_MinorAdjEntry_XEquals1" 36 "AIParkngRespICB_36_MinorAdjActive_XEquals1" 37 "AIParkngRespICB_37_ReverseParkingEntry_XEquals1" 38 "MinorAdjActive_Left_XEquals1_2_P11L_M2_P11LX1_S11L_M1_P12L_427PP01_P11L_M3_EP33L_S11L_M2_S12L_M1" 39 "MinorAdjActive_Right_XEquals1_2_P11L_M2_P11LX1_S11L_M1_P12L_427PP01_P11L_M3_EP33_S11L_M2_S12L_M1" 40 "FixMinorAdj_XEquals1_2_P11L_M2_P11LX1_S11L_M1_P12L_427PP01_P11L_M3_EP33L_S11L_M2_S12L_M1" 41 "AIParkngRespICB_41_Trun_around_Left" 42 "AIParkngRespICB_42_RPAIN_Confirming" 45 "AIParkngRespICB_45_NarrowRoadForwardActive" 46 "AIParkngRespICB_46_NarrowRoadForwardEntry" 48 "AIParkngRespICB_48_Trun_around_Right" 49 "AIParkngRespICB_49_Choose_left_turn_round" 50 "AIParkngRespICB_50_Choose_right_turn_round" 51 "AIParkngRespICB_51_choose_right_back_direction" 52 "AIParkngRespICB_52_choose_left_back_direction" 53 "AIParkngRespICB_53_reserved" 54 "AIParkngRespICB_54_reserved" 55 "AIParkngRespICB_55_reserved" 56 "AIParkngRespICB_56_reserved" 57 "AIParkngRespICB_57_reserved" 58 "AIParkngRespICB_58_reserved" 59 "AIParkngRespICB_59_reserved" 60 "AIParkngRespICB_60_reserved" 61 "AIParkngRespICB_61_reserved" 62 "AIParkngRespICB_62_reserved" 63 "AIParkngRespICB_63_reserved" 64 "AIParkngRespICB_64_reserved" 65 "AIParkngRespICB_65_reserved" 66 "AIParkngRespICB_66_reserved" 67 "AIParkngRespICB_67_reserved" 68 "AIParkngRespICB_68_reserved" 69 "AIParkngRespICB_69_reserved" 70 "AIParkngRespICB_70_reserved" 71 "AIParkngRespICB_71_reserved" 72 "AIParkngRespICB_72_reserved" 73 "AIParkngRespICB_73_reserved" 74 "AIParkngRespICB_74_reserved" 75 "AIParkngRespICB_75_reserved" 76 "AIParkngRespICB_76_reserved" 77 "AIParkngRespICB_77_reserved" 78 "AIParkngRespICB_78_reserved" 79 "AIParkngRespICB_79_reserved" 80 "AIParkngRespICB_80_reserved" 81 "AIParkngRespICB_81_reserved" 82 "AIParkngRespICB_82_reserved" 83 "AIParkngRespICB_83_reserved" 84 "AIParkngRespICB_84_reserved" 85 "AIParkngRespICB_85_reserved" 86 "AIParkngRespICB_86_reserved" 87 "AIParkngRespICB_87_reserved" 88 "AIParkngRespICB_88_reserved" 89 "AIParkngRespICB_89_reserved" 90 "AIParkngRespICB_90_reserved" 91 "AIParkngRespICB_91_reserved" 92 "AIParkngRespICB_92_reserved" 93 "AIParkngRespICB_93_reserved" 94 "AIParkngRespICB_94_reserved" 95 "AIParkngRespICB_95_reserved" 96 "AIParkngRespICB_96_reserved" 97 "AIParkngRespICB_97_reserved" 98 "AIParkngRespICB_98_reserved" 99 "AIParkngRespICB_99_reserved" 100 "AIParkngRespICB_100_reserved" 101 "AIParkngRespICB_101_reserved" 102 "AIParkngRespICB_102_reserved" 103 "AIParkngRespICB_103_reserved" 104 "AIParkngRespICB_104_reserved" 105 "AIParkngRespICB_105_reserved" 106 "AIParkngRespICB_106_reserved" 107 "AIParkngRespICB_107_reserved" 108 "AIParkngRespICB_108_reserved" 109 "AIParkngRespICB_109_reserved" 110 "AIParkngRespICB_110_reserved" 111 "AIParkngRespICB_111_reserved" 112 "AIParkngRespICB_112_reserved" 113 "AIParkngRespICB_113_reserved" 114 "AIParkngRespICB_114_reserved" 115 "AIParkngRespICB_115_reserved" 116 "AIParkngRespICB_116_reserved" 117 "AIParkngRespICB_117_reserved" 118 "AIParkngRespICB_118_reserved" 119 "AIParkngRespICB_119_reserved" 120 "AIParkngRespICB_120_reserved" 121 "AIParkngRespICB_121_reserved" 122 "AIParkngRespICB_122_reserved" 123 "AIParkngRespICB_123_reserved" 124 "AIParkngRespICB_124_reserved" 125 "AIParkngRespICB_125_reserved" 126 "AIParkngRespICB_126_reserved" 127 "AIParkngRespICB_127_reserved" 128 "AIParkngRespICB_128_reserved" 129 "AIParkngRespICB_129_reserved" 130 "AIParkngRespICB_130_reserved" 131 "AIParkngRespICB_131_reserved" 132 "AIParkngRespICB_132_reserved" 133 "AIParkngRespICB_133_reserved" 134 "AIParkngRespICB_134_reserved" 135 "AIParkngRespICB_135_reserved" 136 "AIParkngRespICB_136_reserved" 137 "AIParkngRespICB_137_reserved" 138 "AIParkngRespICB_138_reserved" 139 "AIParkngRespICB_139_reserved" 140 "AIParkngRespICB_140_reserved" 141 "AIParkngRespICB_141_reserved" 142 "AIParkngRespICB_142_reserved" 143 "AIParkngRespICB_143_reserved" 144 "AIParkngRespICB_144_reserved" 145 "AIParkngRespICB_145_reserved" 146 "AIParkngRespICB_146_reserved" 147 "AIParkngRespICB_147_reserved" 148 "AIParkngRespICB_148_reserved" 149 "AIParkngRespICB_149_reserved" 150 "AIParkngRespICB_150_reserved" 151 "AIParkngRespICB_151_reserved" 152 "AIParkngRespICB_152_reserved" 153 "AIParkngRespICB_153_reserved" 154 "AIParkngRespICB_154_reserved" 155 "AIParkngRespICB_155_reserved" 156 "AIParkngRespICB_156_reserved" 157 "AIParkngRespICB_157_reserved" 158 "AIParkngRespICB_158_reserved" 159 "AIParkngRespICB_159_reserved" 160 "AIParkngRespICB_160_reserved" 161 "AIParkngRespICB_161_reserved" 162 "AIParkngRespICB_162_reserved" 163 "AIParkngRespICB_163_reserved" 164 "AIParkngRespICB_164_reserved" 165 "AIParkngRespICB_165_reserved" 166 "AIParkngRespICB_166_reserved" 167 "AIParkngRespICB_167_reserved" 168 "AIParkngRespICB_168_reserved" 169 "AIParkngRespICB_169_reserved" 170 "AIParkngRespICB_170_reserved" 171 "AIParkngRespICB_171_reserved" 172 "AIParkngRespICB_172_reserved" 173 "AIParkngRespICB_173_reserved" 174 "AIParkngRespICB_174_reserved" 175 "AIParkngRespICB_175_reserved" 176 "AIParkngRespICB_176_reserved" 177 "AIParkngRespICB_177_reserved" 178 "AIParkngRespICB_178_reserved" 179 "AIParkngRespICB_179_reserved" 180 "AIParkngRespICB_180_reserved" 181 "AIParkngRespICB_181_reserved" 182 "AIParkngRespICB_182_reserved" 183 "AIParkngRespICB_183_reserved" 184 "AIParkngRespICB_184_reserved" 185 "AIParkngRespICB_185_reserved" 186 "AIParkngRespICB_186_reserved" 187 "AIParkngRespICB_187_reserved" 188 "AIParkngRespICB_188_reserved" 189 "AIParkngRespICB_189_reserved" 190 "AIParkngRespICB_190_reserved" 191 "AIParkngRespICB_191_reserved" 192 "AIParkngRespICB_192_reserved" 193 "AIParkngRespICB_193_reserved" 194 "AIParkngRespICB_194_reserved" 195 "AIParkngRespICB_195_reserved" 196 "AIParkngRespICB_196_reserved" 197 "AIParkngRespICB_197_reserved" 198 "AIParkngRespICB_198_reserved" 199 "AIParkngRespICB_199_reserved" 200 "AIParkngRespICB_200_reserved" 201 "AIParkngRespICB_201_reserved" 202 "AIParkngRespICB_202_reserved" 203 "AIParkngRespICB_203_reserved" 204 "AIParkngRespICB_204_reserved" 205 "AIParkngRespICB_205_reserved" 206 "AIParkngRespICB_206_reserved" 207 "AIParkngRespICB_207_reserved" 208 "AIParkngRespICB_208_reserved" 209 "AIParkngRespICB_209_reserved" 210 "AIParkngRespICB_210_reserved" 211 "AIParkngRespICB_211_reserved" 212 "AIParkngRespICB_212_reserved" 213 "AIParkngRespICB_213_reserved" 214 "AIParkngRespICB_214_reserved" 215 "AIParkngRespICB_215_reserved" 216 "AIParkngRespICB_216_reserved" 217 "AIParkngRespICB_217_reserved" 218 "AIParkngRespICB_218_reserved" 219 "AIParkngRespICB_219_reserved" 220 "AIParkngRespICB_220_reserved" 221 "AIParkngRespICB_221_reserved" 222 "AIParkngRespICB_222_reserved" 223 "AIParkngRespICB_223_reserved" 224 "AIParkngRespICB_224_reserved" 225 "AIParkngRespICB_225_reserved" 226 "AIParkngRespICB_226_reserved" 227 "AIParkngRespICB_227_reserved" 228 "AIParkngRespICB_228_reserved" 229 "AIParkngRespICB_229_reserved" 230 "AIParkngRespICB_230_reserved" 231 "AIParkngRespICB_231_reserved" 232 "AIParkngRespICB_232_reserved" 233 "AIParkngRespICB_233_reserved" 234 "AIParkngRespICB_234_reserved" 235 "AIParkngRespICB_235_reserved" 236 "AIParkngRespICB_236_reserved" 237 "AIParkngRespICB_237_reserved" 238 "AIParkngRespICB_238_reserved" 239 "AIParkngRespICB_239_reserved" 240 "AIParkngRespICB_240_reserved" 241 "AIParkngRespICB_241_reserved" 242 "AIParkngRespICB_242_reserved" 243 "AIParkngRespICB_243_reserved" 244 "AIParkngRespICB_244_reserved" 245 "AIParkngRespICB_245_reserved" 246 "AIParkngRespICB_246_reserved" 247 "AIParkngRespICB_247_reserved" 248 "AIParkngRespICB_248_reserved" 249 "AIParkngRespICB_249_reserved" 250 "AIParkngRespICB_250_reserved" 251 "AIParkngRespICB_251_reserved" 252 "AIParkngRespICB_252_reserved" 253 "AIParkngRespICB_253_reserved" 254 "AIParkngRespICB_254_reserved" 255 "AIParkngRespICB_255_reserved";
SIG_GROUP_ 486 IIPD_20ms_Group43 1 : ACCAccReqToqVal ACCSysFltSts_SCS FrtCarGoNotfr IPD_20ms_Group43_CRC IPD_20ms_Group43_RC IPD_20ms_Group43_Reserved1 IPD_20ms_Group43_Reserved2 IPD_20ms_Group43_Reserved3 IPD_20ms_Group43_Reserved4 IPD_20ms_Group43_Reserved5;
SIG_GROUP_ 337 IIPD_20ms_Group60 1 : ALCSysFltSts ALCSysSts APASCSToqReqVal APAVehCrdnatAzmth APAVehCrdnatPosX APAVehCrdnatPosY AutoLaneChngLLaneSts AutoLaneChngRLaneSts ESSDirInd ESSDrvrTkovReq ESSSysFltSts ESSSysSts IPD_20ms_Group60_CRC IPD_20ms_Group60_RC IPD_20ms_Group60_Reserved1 IPD_20ms_Group60_Reserved10 IPD_20ms_Group60_Reserved11 IPD_20ms_Group60_Reserved2 IPD_20ms_Group60_Reserved4 IPD_20ms_Group60_Reserved5 IPD_20ms_Group60_Reserved6 IPD_20ms_Group60_Reserved7 IPD_20ms_Group60_Reserved8 IPD_20ms_Group60_Reserved9 NOPSysFltSts NOPSysSts_ZPD Parkngslottype PilotTkovMsgReq PrkgDstCtrlSwResp;
SIG_GROUP_ 720 IIPD_50ms_Group14 1 : IPD_50ms_Group14_CRC IPD_50ms_Group14_RC IPD_50ms_Group14_Reserved1 IPD_50ms_Group14_Reserved10 IPD_50ms_Group14_Reserved11 IPD_50ms_Group14_Reserved2 IPD_50ms_Group14_Reserved3 IPD_50ms_Group14_Reserved4 IPD_50ms_Group14_Reserved5 IPD_50ms_Group14_Reserved6 IPD_50ms_Group14_Reserved7 IPD_50ms_Group14_Reserved8 IPD_50ms_Group14_Reserved9 LADSInfoDispReq LADSInfoDispReqToICM LADSProgressBar SDWLSFObsRng SDWLSRObsRng SDWRSFObsRng SDWRSRObsRng;
SIG_GROUP_ 733 IIPD_50ms_Group49 1 : APAEnRunReq IPD_50ms_Group49_CRC IPD_50ms_Group49_RC IPD_50ms_Group49_Reserved1 IPD_50ms_Group49_Reserved2 IPD_50ms_Group49_Reserved3 IPD_50ms_Group49_Reserved4 IPD_50ms_Group49_Reserved5 IPD_50ms_Group49_Reserved6 KeepPwrRsnIPD LADSAFnInd SysPwrMdCtrl;
SIG_GROUP_ 1143 IIPD_Sporadic_TimeSync_Group 1 : SyncMsgCheckSum SyncMsgOVS SyncMsgSGW SyncMsgSequenceCounter SyncMsgTime SyncMsgTimeDomain SyncMsgType SyncMsgreserved;
